VERSION ""

NS_ :

BS_:

BU_: VT3 VT2 VT1 Implement

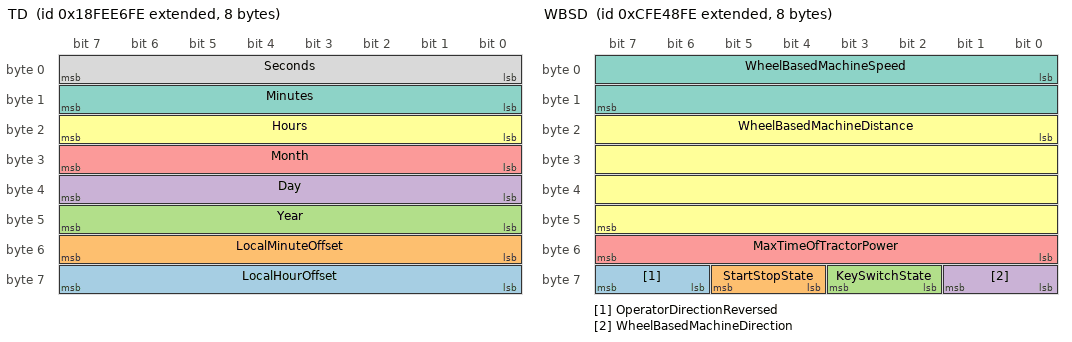
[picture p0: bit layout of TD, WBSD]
BO_ 2566842110 TD: 8 Vector__XXX
 SG_ LocalHourOffset : 56|8@1+ (1,-125) [-125|125] "hr" Vector__XXX
 SG_ LocalMinuteOffset : 48|8@1+ (1,-125) [-125|125] "mins" Vector__XXX
 SG_ Year : 40|8@1+ (1,1985) [1985|2235] "years" Vector__XXX
 SG_ Day : 32|8@1+ (0.25,0) [0|62.5] "days" Vector__XXX
 SG_ Month : 24|8@1+ (1,0) [0|250] "months" Vector__XXX
 SG_ Hours : 16|8@1+ (1,0) [0|250] "hr" Vector__XXX
 SG_ Minutes : 8|8@1+ (1,0) [0|250] "mins" Vector__XXX
 SG_ Seconds : 0|8@1+ (0.25,0) [0|62.5] "s" Vector__XXX

BO_ 2365475326 GBSD: 8 Vector__XXX
 SG_ GroundBasedMachineDirection : 56|2@1+ (1,0) [0|3] "" Vector__XXX
 SG_ GroundBasedMachineDistance : 16|32@1+ (0.001,0) [0|4211080] "m" Vector__XXX
 SG_ GroundBasedMachineSpeed : 0|16@1+ (0.001,0) [0|64.255] "m/s" Vector__XXX

BO_ 2365475070 WBSD: 8 Vector__XXX
 SG_ OperatorDirectionReversed : 62|2@1+ (1,0) [0|3] "" Vector__XXX
 SG_ StartStopState : 60|2@1+ (1,0) [0|4] "" Vector__XXX
 SG_ KeySwitchState : 58|2@1+ (1,0) [0|3] "" Vector__XXX
 SG_ WheelBasedMachineDirection : 56|2@1+ (1,0) [0|3] "" Vector__XXX
 SG_ MaxTimeOfTractorPower : 48|8@1+ (1,0) [0|250] "min" Vector__XXX
 SG_ WheelBasedMachineDistance : 16|32@1+ (0.001,0) [0|4211081.215] "m" Vector__XXX
 SG_ WheelBasedMachineSpeed : 0|16@1+ (0.001,0) [0|64.255] "m/s" Vector__XXX

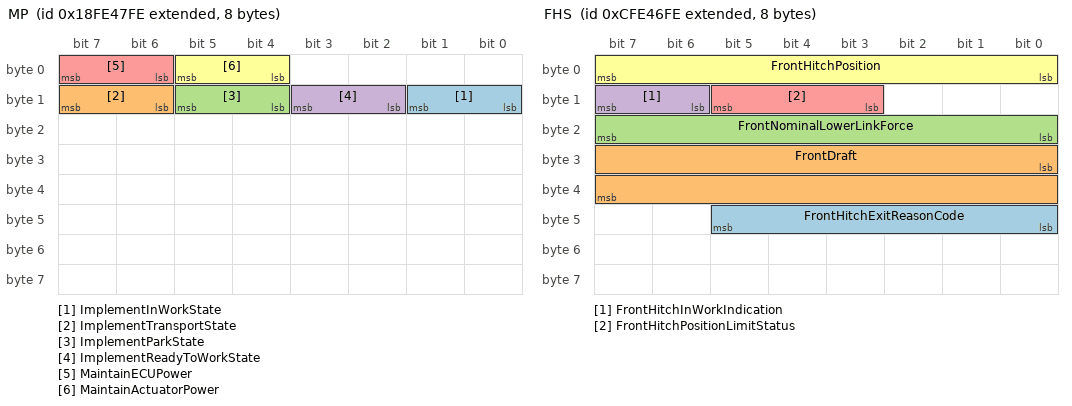
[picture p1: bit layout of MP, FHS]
BO_ 2566801406 MP: 8 Vector__XXX
 SG_ ImplementInWorkState : 8|2@1+ (1,0) [0|0] "" Vector__XXX
 SG_ ImplementTransportState : 14|2@1+ (1,0) [0|3] "" Vector__XXX
 SG_ ImplementParkState : 12|2@1+ (1,0) [0|3] "" Vector__XXX
 SG_ ImplementReadyToWorkState : 10|2@1+ (1,0) [0|3] "" Vector__XXX
 SG_ MaintainECUPower : 6|2@1+ (1,0) [0|0] "" Vector__XXX
 SG_ MaintainActuatorPower : 4|2@1+ (1,0) [0|3] "" Vector__XXX

BO_ 2365474558 FHS: 8 Vector__XXX
 SG_ FrontHitchExitReasonCode : 40|6@1+ (1,0) [0|63] "" Vector__XXX
 SG_ FrontDraft : 24|16@1+ (10,-320000) [-320000|322550] "N" Vector__XXX
 SG_ FrontNominalLowerLinkForce : 16|8@1+ (0.8,-100) [-100|100] "%" Vector__XXX
 SG_ FrontHitchInWorkIndication : 14|2@1+ (1,0) [0|3] "" Vector__XXX
 SG_ FrontHitchPositionLimitStatus : 11|3@1+ (1,0) [0|7] "" Vector__XXX
 SG_ FrontHitchPosition : 0|8@1+ (0.4,0) [0|100] "%" Vector__XXX

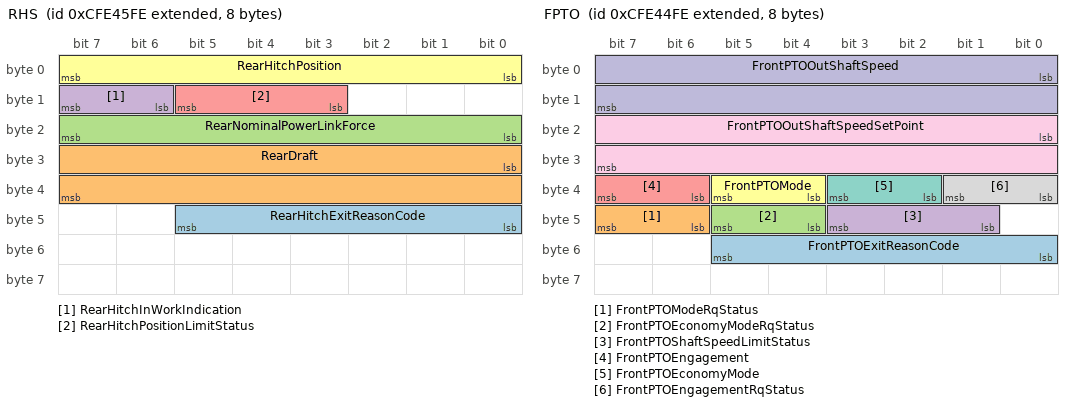
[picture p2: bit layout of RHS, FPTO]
BO_ 2365474302 RHS: 8 Vector__XXX
 SG_ RearHitchExitReasonCode : 40|6@1+ (1,0) [0|63] "" Vector__XXX
 SG_ RearDraft : 24|16@1+ (10,-320000) [-320000|322550] "N" Vector__XXX
 SG_ RearNominalPowerLinkForce : 16|8@1+ (0.8,-100) [-100|100] "%" Vector__XXX
 SG_ RearHitchInWorkIndication : 14|2@1+ (1,0) [0|3] "" Vector__XXX
 SG_ RearHitchPositionLimitStatus : 11|3@1+ (1,0) [0|7] "" Vector__XXX
 SG_ RearHitchPosition : 0|8@1+ (0.4,0) [0|100] "%" Vector__XXX

BO_ 2365474046 FPTO: 8 Vector__XXX
 SG_ FrontPTOExitReasonCode : 48|6@1+ (1,0) [0|63] "" Vector__XXX
 SG_ FrontPTOModeRqStatus : 46|2@1+ (1,0) [0|3] "" Vector__XXX
 SG_ FrontPTOEconomyModeRqStatus : 44|2@1+ (1,0) [0|3] "" Vector__XXX
 SG_ FrontPTOShaftSpeedLimitStatus : 41|3@1+ (1,0) [0|7] "" Vector__XXX
 SG_ FrontPTOEngagement : 38|2@1+ (1,0) [0|3] "" Vector__XXX
 SG_ FrontPTOMode : 36|2@1+ (1,0) [0|3] "" Vector__XXX
 SG_ FrontPTOEconomyMode : 34|2@1+ (1,0) [0|3] "" Vector__XXX
 SG_ FrontPTOEngagementRqStatus : 32|2@1+ (1,0) [0|3] "" Vector__XXX
 SG_ FrontPTOOutShaftSpeedSetPoint : 16|16@1+ (0.125,0) [0|8031.88] "1/min" Vector__XXX
 SG_ FrontPTOOutShaftSpeed : 0|16@1+ (0.125,0) [0|8031.88] "1/min" Vector__XXX

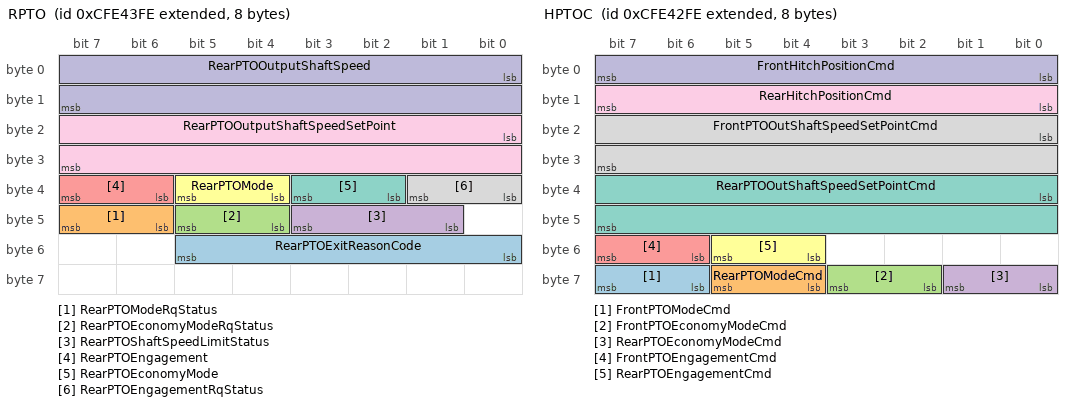
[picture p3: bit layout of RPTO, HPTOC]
BO_ 2365473790 RPTO: 8 Vector__XXX
 SG_ RearPTOExitReasonCode : 48|6@1+ (1,0) [0|63] "" Vector__XXX
 SG_ RearPTOModeRqStatus : 46|2@1+ (1,0) [0|3] "" Vector__XXX
 SG_ RearPTOEconomyModeRqStatus : 44|2@1+ (1,0) [0|3] "" Vector__XXX
 SG_ RearPTOShaftSpeedLimitStatus : 41|3@1+ (1,0) [0|7] "" Vector__XXX
 SG_ RearPTOEngagement : 38|2@1+ (1,0) [0|3] "" Vector__XXX
 SG_ RearPTOMode : 36|2@1+ (1,0) [0|3] "" Vector__XXX
 SG_ RearPTOEconomyMode : 34|2@1+ (1,0) [0|3] "" Vector__XXX
 SG_ RearPTOEngagementRqStatus : 32|2@1+ (1,0) [0|3] "" Vector__XXX
 SG_ RearPTOOutputShaftSpeedSetPoint : 16|16@1+ (0.125,0) [0|8031.88] "1/min" Vector__XXX
 SG_ RearPTOOutputShaftSpeed : 0|16@1+ (0.125,0) [0|8031.88] "1/min" Vector__XXX

BO_ 2365473534 HPTOC: 8 Vector__XXX
 SG_ FrontPTOModeCmd : 62|2@1+ (1,0) [0|3] "" Vector__XXX
 SG_ RearPTOModeCmd : 60|2@1+ (1,0) [0|3] "" Vector__XXX
 SG_ FrontPTOEconomyModeCmd : 58|2@1+ (1,0) [0|3] "" Vector__XXX
 SG_ RearPTOEconomyModeCmd : 56|2@1+ (1,0) [0|3] "" Vector__XXX
 SG_ FrontPTOEngagementCmd : 54|2@1+ (1,0) [0|3] "" Vector__XXX
 SG_ RearPTOEngagementCmd : 52|2@1+ (1,0) [0|3] "" Vector__XXX
 SG_ RearPTOOutShaftSpeedSetPointCmd : 32|16@1+ (0.125,0) [0|801.875] "1/min" Vector__XXX
 SG_ FrontPTOOutShaftSpeedSetPointCmd : 16|16@1+ (0.125,0) [0|8031.875] "1/min" Vector__XXX
 SG_ RearHitchPositionCmd : 8|8@1+ (0.4,0) [0|100] "%" Vector__XXX
 SG_ FrontHitchPositionCmd : 0|8@1+ (0.4,0) [0|100] "%" Vector__XXX

BO_ 2365473278 LCMD: 8 Vector__XXX
 SG_ ImplementRearWorkLightCmd : 62|2@1+ (1,0) [0|3] "" Vector__XXX
 SG_ ImplementLeftFacingWorkLightCmd : 60|2@1+ (1,0) [0|3] "" Vector__XXX
 SG_ ImplementRightFacingWorkLightCmd : 58|2@1+ (1,0) [0|3] "" Vector__XXX
 SG_ LightingDataRequestCmd : 56|2@1+ (1,0) [0|3] "" Vector__XXX
 SG_ ImplementLeftForwardLightCmd : 54|2@1+ (1,0) [0|3] "" Vector__XXX
 SG_ ImplementRightForwardLightCmd : 52|2@1+ (1,0) [0|3] "" Vector__XXX
 SG_ ImplementOEMOption1LightCmd : 50|2@1+ (1,0) [0|3] "" Vector__XXX
 SG_ ImplementOEMOption2LightCmd : 48|2@1+ (1,0) [0|3] "" Vector__XXX
 SG_ TractorFrontHighWorkLightCmd : 46|2@1+ (1,0) [0|3] "" Vector__XXX
 SG_ TractorFrontLowWorkLightCmd : 44|2@1+ (1,0) [0|3] "" Vector__XXX
 SG_ TractorSideHighWorkLightCmd : 42|2@1+ (1,0) [0|3] "" Vector__XXX
 SG_ TractorSideLowWorkLightCmd : 40|2@1+ (1,0) [0|3] "" Vector__XXX
 SG_ TractorRearHighWorkLightCmd : 38|2@1+ (1,0) [0|3] "" Vector__XXX
 SG_ TractorRearLowWorkLightCmd : 36|2@1+ (1,0) [0|3] "" Vector__XXX
 SG_ TractorUndersideWorkLightCmd : 34|2@1+ (1,0) [0|3] "" Vector__XXX
 SG_ RearFogLightCmd : 32|2@1+ (1,0) [0|3] "" Vector__XXX
 SG_ TractorMarkerLightCmd : 30|2@1+ (1,0) [0|3] "" Vector__XXX
 SG_ ImplementMarkerLightCmd : 28|2@1+ (1,0) [0|3] "" Vector__XXX
 SG_ TractorClearanceLightCmd : 26|2@1+ (1,0) [0|3] "" Vector__XXX
 SG_ ImplementClearanceLightCmd : 24|2@1+ (1,0) [0|3] "" Vector__XXX
 SG_ LeftStopLightCmd : 22|2@1+ (1,0) [0|3] "" Vector__XXX
 SG_ RightStopLightCmd : 20|2@1+ (1,0) [0|3] "" Vector__XXX
 SG_ CentreStopLightCmd : 18|2@1+ (1,0) [0|3] "" Vector__XXX
 SG_ BackUpLightAndAlarmHornCmd : 16|2@1+ (1,0) [0|3] "" Vector__XXX
 SG_ LeftTurnSignalLightCmd : 14|2@1+ (1,0) [0|3] "" Vector__XXX
 SG_ RightTurnSignalLightCmd : 12|2@1+ (1,0) [0|3] "" Vector__XXX
 SG_ RotatingBeaconLightCmd : 10|2@1+ (1,0) [0|3] "" Vector__XXX
 SG_ TractorFrontFogLightCmd : 8|2@1+ (1,0) [0|3] "" Vector__XXX
 SG_ HighBeamHeadLightCmd : 6|2@1+ (1,0) [0|3] "" Vector__XXX
 SG_ LowBeamHeadLightCmd : 4|2@1+ (1,0) [0|3] "" Vector__XXX
 SG_ AlternateHeadLightCmd : 2|2@1+ (1,0) [0|3] "" Vector__XXX
 SG_ DaytimeRunningLightCmd : 0|2@1+ (1,0) [0|3] "" Vector__XXX

BO_ 2566799614 LID: 8 Vector__XXX
 SG_ ImplementRearWorkLightData : 62|2@1+ (1,0) [0|3] "" Vector__XXX
 SG_ ImplLeftFacingWorkLightData : 60|2@1+ (1,0) [0|3] "" Vector__XXX
 SG_ ImplRightFacingWorkLightData : 58|2@1+ (1,0) [0|3] "" Vector__XXX
 SG_ ImplementLeftForwardLightData : 54|2@1+ (1,0) [0|3] "" Vector__XXX
 SG_ ImplementRightForwardLightData : 52|2@1+ (1,0) [0|3] "" Vector__XXX
 SG_ ImplementOEMOption1LightData : 50|2@1+ (1,0) [0|3] "" Vector__XXX
 SG_ ImplementOEMOption2LightData : 48|2@1+ (1,0) [0|3] "" Vector__XXX
 SG_ TractorFrontHighWorkLightData : 46|2@1+ (1,0) [0|3] "" Vector__XXX
 SG_ TractorFrontLowWorkLightData : 44|2@1+ (1,0) [0|3] "" Vector__XXX
 SG_ TractorSideHighWorkLightData : 42|2@1+ (1,0) [0|3] "" Vector__XXX
 SG_ TractorSideLowWorkLightData : 40|2@1+ (1,0) [0|3] "" Vector__XXX
 SG_ TractorRearHighWorkLightData : 38|2@1+ (1,0) [0|3] "" Vector__XXX
 SG_ TractorRearLowWorkLightData : 36|2@1+ (1,0) [0|3] "" Vector__XXX
 SG_ TractorUndersideWorkLightData : 34|2@1+ (1,0) [0|3] "" Vector__XXX
 SG_ RearFogLightData : 32|2@1+ (1,0) [0|3] "" Vector__XXX
 SG_ TractorMarkerLightData : 30|2@1+ (1,0) [0|3] "" Vector__XXX
 SG_ ImplementMarkerLightData : 28|2@1+ (1,0) [0|3] "" Vector__XXX
 SG_ TractorClearanceLightData : 26|2@1+ (1,0) [0|3] "" Vector__XXX
 SG_ ImplementClearanceLightData : 24|2@1+ (1,0) [0|3] "" Vector__XXX
 SG_ LefttStopLightData : 22|2@1+ (1,0) [0|3] "" Vector__XXX
 SG_ RightStopLightData : 20|2@1+ (1,0) [0|3] "" Vector__XXX
 SG_ CentreStopLightData : 18|2@1+ (1,0) [0|3] "" Vector__XXX
 SG_ BackUpLightAndAlarmHornData : 16|2@1+ (1,0) [0|3] "" Vector__XXX
 SG_ LeftTurnSignalLightData : 14|2@1+ (1,0) [0|3] "" Vector__XXX
 SG_ RightTurnSignalLightData : 12|2@1+ (1,0) [0|3] "" Vector__XXX
 SG_ RotationBeaconLightData : 10|2@1+ (1,0) [0|3] "" Vector__XXX
 SG_ TractorFrontFogLightData : 8|2@1+ (1,0) [0|3] "" Vector__XXX
 SG_ HighBeamHeadLightData : 6|2@1+ (1,0) [0|3] "" Vector__XXX
 SG_ LowBeamHeadLightData : 4|2@1+ (1,0) [0|3] "" Vector__XXX
 SG_ AlternateHeadLightData : 2|2@1+ (1,0) [0|3] "" Vector__XXX
 SG_ DaytimeRunningLightData : 0|2@1+ (1,0) [0|3] "" Vector__XXX

BO_ 2365472766 AV15C: 8 Vector__XXX
 SG_ Valve15FailSaveModeCmd : 22|2@1+ (1,0) [0|3] "" Vector__XXX
 SG_ Valve15StateCmd : 16|4@1+ (1,0) [0|15] "" Vector__XXX
 SG_ Valve15PortFlowCmd : 0|8@1+ (0.4,0) [0|100] "%" Vector__XXX

BO_ 2365472510 AV14C: 8 Vector__XXX
 SG_ Valve14FailSaveModeCmd : 22|2@1+ (1,0) [0|3] "" Vector__XXX
 SG_ Valve14StateCmd : 16|4@1+ (1,0) [0|15] "" Vector__XXX
 SG_ Valve14PortFlowCmd : 0|8@1+ (0.4,0) [0|100] "%" Vector__XXX

BO_ 2365472254 AV13C: 8 Vector__XXX
 SG_ Valve13FailSaveModeCmd : 22|2@1+ (1,0) [0|3] "" Vector__XXX
 SG_ Valve13StateCmd : 16|4@1+ (1,0) [0|15] "" Vector__XXX
 SG_ Valve13PortFlowCmd : 0|8@1+ (0.4,0) [0|100] "%" Vector__XXX

BO_ 2365471998 AV12C: 8 Vector__XXX
 SG_ Valve12FailSaveModeCmd : 22|2@1+ (1,0) [0|3] "" Vector__XXX
 SG_ Valve12StateCmd : 16|4@1+ (1,0) [0|15] "" Vector__XXX
 SG_ Valve12PortFlowCmd : 0|8@1+ (0.4,0) [0|100] "%" Vector__XXX

BO_ 2365471742 AV11C: 8 Vector__XXX
 SG_ Valve11FailSaveModeCmd : 22|2@1+ (1,0) [0|3] "" Vector__XXX
 SG_ Valve11StateCmd : 16|4@1+ (1,0) [0|15] "" Vector__XXX
 SG_ Valve11PortFlowCmd : 0|8@1+ (0.4,0) [0|100] "%" Vector__XXX

BO_ 2365471486 AV10C: 8 Vector__XXX
 SG_ Valve10FailSaveModeCmd : 22|2@1+ (1,0) [0|3] "" Vector__XXX
 SG_ Valve10StateCmd : 16|4@1+ (1,0) [0|15] "" Vector__XXX
 SG_ Valve10PortFlowCmd : 0|8@1+ (0.4,0) [0|100] "%" Vector__XXX

BO_ 2365471230 AV09C: 8 Vector__XXX
 SG_ Valve9FailSaveModeCmd : 22|2@1+ (1,0) [0|3] "" Vector__XXX
 SG_ Valve9StateCmd : 16|4@1+ (1,0) [0|15] "" Vector__XXX
 SG_ Valve9PortFlowCmd : 0|8@1+ (0.4,0) [0|100] "%" Vector__XXX

BO_ 2365470974 AV08C: 8 Vector__XXX
 SG_ Valve8FailSaveModeCmd : 22|2@1+ (1,0) [0|3] "" Vector__XXX
 SG_ Valve8StateCmd : 16|4@1+ (1,0) [0|15] "" Vector__XXX
 SG_ Valve8PortFlowCmd : 0|8@1+ (0.4,0) [0|100] "%" Vector__XXX

BO_ 2365470718 AV07C: 8 Vector__XXX
 SG_ Valve7FailSaveModeCmd : 22|2@1+ (1,0) [0|3] "" Vector__XXX
 SG_ Valve7StateCmd : 16|4@1+ (1,0) [0|15] "" Vector__XXX
 SG_ Valve7PortFlowCmd : 0|8@1+ (0.4,0) [0|100] "%" Vector__XXX

BO_ 2365470462 AV06C: 8 Vector__XXX
 SG_ Valve6FailSaveModeCmd : 22|2@1+ (1,0) [0|3] "" Vector__XXX
 SG_ Valve6StateCmd : 16|4@1+ (1,0) [0|15] "" Vector__XXX
 SG_ Valve6PortFlowCmd : 0|8@1+ (0.4,0) [0|100] "%" Vector__XXX

BO_ 2365470206 AV05C: 8 Vector__XXX
 SG_ Valve5FailSaveModeCmd : 22|2@1+ (1,0) [0|3] "" Vector__XXX
 SG_ Valve5StateCmd : 16|4@1+ (1,0) [0|15] "" Vector__XXX
 SG_ Valve5PortFlowCmd : 0|8@1+ (0.4,0) [0|100] "%" Vector__XXX

BO_ 2365469950 AV04C: 8 Vector__XXX
 SG_ Valve4FailSaveModeCmd : 22|2@1+ (1,0) [0|3] "" Vector__XXX
 SG_ Valve4StateCmd : 16|4@1+ (1,0) [0|15] "" Vector__XXX
 SG_ Valve4PortFlowCmd : 0|8@1+ (0.4,0) [0|100] "%" Vector__XXX

BO_ 2365469694 AV03C: 8 Vector__XXX
 SG_ Valve3FailSaveModeCmd : 22|2@1+ (1,0) [0|3] "" Vector__XXX
 SG_ Valve3StateCmd : 16|4@1+ (1,0) [0|15] "" Vector__XXX
 SG_ Valve3PortFlowCmd : 0|8@1+ (0.4,0) [0|100] "%" Vector__XXX

BO_ 2365469438 AV02C: 8 Vector__XXX
 SG_ Valve2FailSaveModeCmd : 22|2@1+ (1,0) [0|3] "" Vector__XXX
 SG_ Valve2StateCmd : 16|4@1+ (1,0) [0|15] "" Vector__XXX
 SG_ Valve2PortFlowCmd : 0|8@1+ (0.4,0) [0|100] "%" Vector__XXX

BO_ 2365469182 AV01C: 8 Vector__XXX
 SG_ Valve1FailSaveModeCmd : 22|2@1+ (1,0) [0|3] "" Vector__XXX
 SG_ Valve1StateCmd : 16|4@1+ (1,0) [0|15] "" Vector__XXX
 SG_ Valve1PortFlowCmd : 0|8@1+ (0.4,0) [0|100] "%" Vector__XXX

BO_ 2365468926 AV00C: 8 Vector__XXX
 SG_ Valve0FailSaveModeCmd : 22|2@1+ (1,0) [0|3] "" Vector__XXX
 SG_ Valve0StateCmd : 16|4@1+ (1,0) [0|15] "" Vector__XXX
 SG_ Valve0PortFlowCmd : 0|8@1+ (0.4,0) [0|100] "%" Vector__XXX

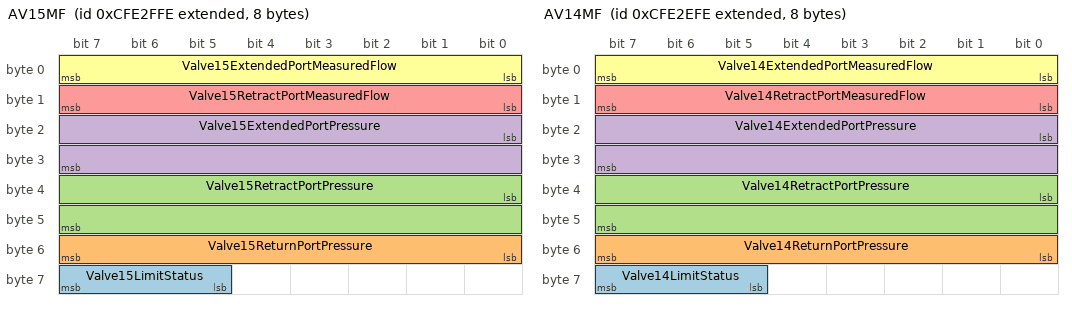
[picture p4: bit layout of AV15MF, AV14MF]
BO_ 2365468670 AV15MF: 8 Vector__XXX
 SG_ Valve15LimitStatus : 61|3@1+ (1,0) [0|7] "" Vector__XXX
 SG_ Valve15ReturnPortPressure : 48|8@1+ (16,0) [0|4000] "kPa" Vector__XXX
 SG_ Valve15RetractPortPressure : 32|16@1+ (5,0) [0|321275] "kPa" Vector__XXX
 SG_ Valve15ExtendedPortPressure : 16|16@1+ (5,0) [0|321275] "kPa" Vector__XXX
 SG_ Valve15RetractPortMeasuredFlow : 8|8@1+ (1,-125) [-125|125] "%" Vector__XXX
 SG_ Valve15ExtendedPortMeasuredFlow : 0|8@1+ (1,-125) [-125|125] "%" Vector__XXX

BO_ 2365468414 AV14MF: 8 Vector__XXX
 SG_ Valve14LimitStatus : 61|3@1+ (1,0) [0|7] "" Vector__XXX
 SG_ Valve14ReturnPortPressure : 48|8@1+ (16,0) [0|4000] "kPa" Vector__XXX
 SG_ Valve14RetractPortPressure : 32|16@1+ (5,0) [0|321275] "kPa" Vector__XXX
 SG_ Valve14ExtendedPortPressure : 16|16@1+ (5,0) [0|321275] "kPa" Vector__XXX
 SG_ Valve14RetractPortMeasuredFlow : 8|8@1+ (1,-125) [-125|125] "%" Vector__XXX
 SG_ Valve14ExtendedPortMeasuredFlow : 0|8@1+ (1,-125) [-125|125] "%" Vector__XXX

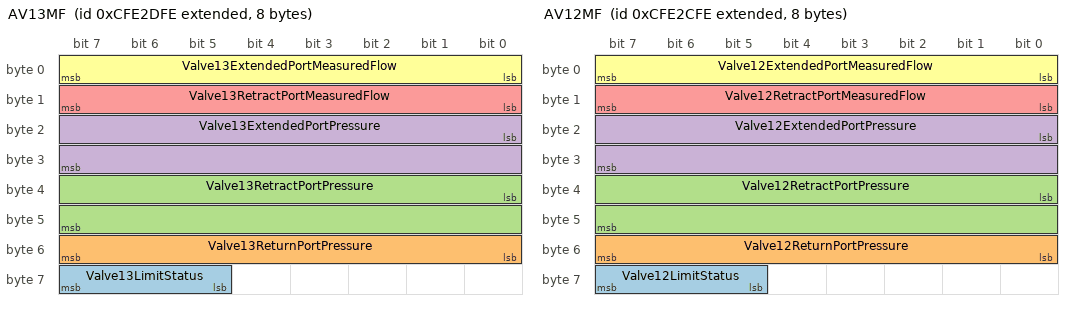
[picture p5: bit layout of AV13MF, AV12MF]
BO_ 2365468158 AV13MF: 8 Vector__XXX
 SG_ Valve13LimitStatus : 61|3@1+ (1,0) [0|7] "" Vector__XXX
 SG_ Valve13ReturnPortPressure : 48|8@1+ (16,0) [0|4000] "kPa" Vector__XXX
 SG_ Valve13RetractPortPressure : 32|16@1+ (5,0) [0|321275] "kPa" Vector__XXX
 SG_ Valve13ExtendedPortPressure : 16|16@1+ (5,0) [0|321275] "kPa" Vector__XXX
 SG_ Valve13RetractPortMeasuredFlow : 8|8@1+ (1,-125) [-125|125] "%" Vector__XXX
 SG_ Valve13ExtendedPortMeasuredFlow : 0|8@1+ (1,-125) [-125|125] "%" Vector__XXX

BO_ 2365467902 AV12MF: 8 Vector__XXX
 SG_ Valve12LimitStatus : 61|3@1+ (1,0) [0|7] "" Vector__XXX
 SG_ Valve12ReturnPortPressure : 48|8@1+ (16,0) [0|4000] "kPa" Vector__XXX
 SG_ Valve12RetractPortPressure : 32|16@1+ (5,0) [0|321275] "kPa" Vector__XXX
 SG_ Valve12ExtendedPortPressure : 16|16@1+ (5,0) [0|321275] "kPa" Vector__XXX
 SG_ Valve12RetractPortMeasuredFlow : 8|8@1+ (1,-125) [-125|125] "%" Vector__XXX
 SG_ Valve12ExtendedPortMeasuredFlow : 0|8@1+ (1,-125) [-125|125] "%" Vector__XXX

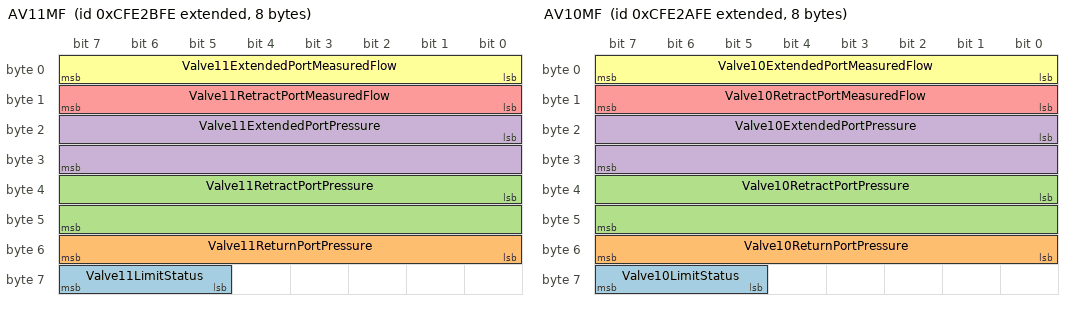
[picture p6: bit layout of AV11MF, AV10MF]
BO_ 2365467646 AV11MF: 8 Vector__XXX
 SG_ Valve11LimitStatus : 61|3@1+ (1,0) [0|7] "" Vector__XXX
 SG_ Valve11ReturnPortPressure : 48|8@1+ (16,0) [0|4000] "kPa" Vector__XXX
 SG_ Valve11RetractPortPressure : 32|16@1+ (5,0) [0|321275] "kPa" Vector__XXX
 SG_ Valve11ExtendedPortPressure : 16|16@1+ (5,0) [0|321275] "kPa" Vector__XXX
 SG_ Valve11RetractPortMeasuredFlow : 8|8@1+ (1,-125) [-125|125] "%" Vector__XXX
 SG_ Valve11ExtendedPortMeasuredFlow : 0|8@1+ (1,-125) [-125|125] "%" Vector__XXX

BO_ 2365467390 AV10MF: 8 Vector__XXX
 SG_ Valve10LimitStatus : 61|3@1+ (1,0) [0|7] "" Vector__XXX
 SG_ Valve10ReturnPortPressure : 48|8@1+ (16,0) [0|4000] "kPa" Vector__XXX
 SG_ Valve10RetractPortPressure : 32|16@1+ (5,0) [0|321275] "kPa" Vector__XXX
 SG_ Valve10ExtendedPortPressure : 16|16@1+ (5,0) [0|321275] "kPa" Vector__XXX
 SG_ Valve10RetractPortMeasuredFlow : 8|8@1+ (1,-125) [-125|125] "%" Vector__XXX
 SG_ Valve10ExtendedPortMeasuredFlow : 0|8@1+ (1,-125) [-125|125] "%" Vector__XXX

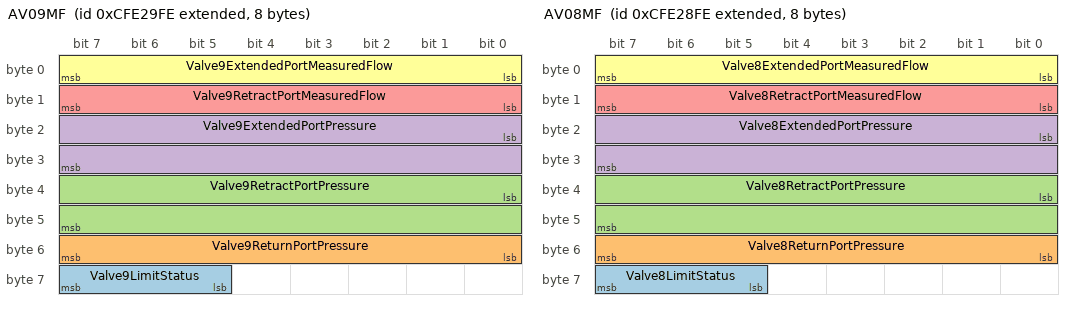
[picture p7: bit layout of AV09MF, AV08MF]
BO_ 2365467134 AV09MF: 8 Vector__XXX
 SG_ Valve9LimitStatus : 61|3@1+ (1,0) [0|7] "" Vector__XXX
 SG_ Valve9ReturnPortPressure : 48|8@1+ (16,0) [0|4000] "kPa" Vector__XXX
 SG_ Valve9RetractPortPressure : 32|16@1+ (5,0) [0|321275] "kPa" Vector__XXX
 SG_ Valve9ExtendedPortPressure : 16|16@1+ (5,0) [0|321275] "kPa" Vector__XXX
 SG_ Valve9RetractPortMeasuredFlow : 8|8@1+ (1,-125) [-125|125] "%" Vector__XXX
 SG_ Valve9ExtendedPortMeasuredFlow : 0|8@1+ (1,-125) [-125|125] "%" Vector__XXX

BO_ 2365466878 AV08MF: 8 Vector__XXX
 SG_ Valve8LimitStatus : 61|3@1+ (1,0) [0|7] "" Vector__XXX
 SG_ Valve8ReturnPortPressure : 48|8@1+ (16,0) [0|4000] "kPa" Vector__XXX
 SG_ Valve8RetractPortPressure : 32|16@1+ (5,0) [0|321275] "kPa" Vector__XXX
 SG_ Valve8ExtendedPortPressure : 16|16@1+ (5,0) [0|321275] "kPa" Vector__XXX
 SG_ Valve8RetractPortMeasuredFlow : 8|8@1+ (1,-125) [-125|125] "%" Vector__XXX
 SG_ Valve8ExtendedPortMeasuredFlow : 0|8@1+ (1,-125) [-125|125] "%" Vector__XXX

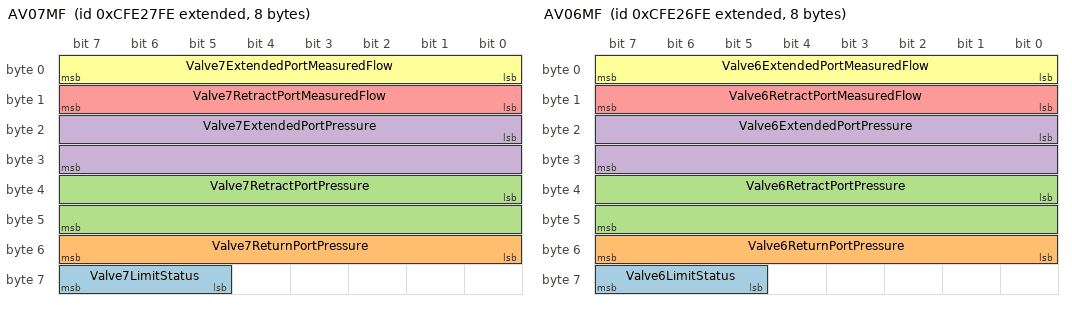
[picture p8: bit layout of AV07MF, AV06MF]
BO_ 2365466622 AV07MF: 8 Vector__XXX
 SG_ Valve7LimitStatus : 61|3@1+ (1,0) [0|7] "" Vector__XXX
 SG_ Valve7ReturnPortPressure : 48|8@1+ (16,0) [0|4000] "kPa" Vector__XXX
 SG_ Valve7RetractPortPressure : 32|16@1+ (5,0) [0|321275] "kPa" Vector__XXX
 SG_ Valve7ExtendedPortPressure : 16|16@1+ (5,0) [0|321275] "kPa" Vector__XXX
 SG_ Valve7RetractPortMeasuredFlow : 8|8@1+ (1,-125) [-125|125] "%" Vector__XXX
 SG_ Valve7ExtendedPortMeasuredFlow : 0|8@1+ (1,-125) [-125|125] "%" Vector__XXX

BO_ 2365466366 AV06MF: 8 Vector__XXX
 SG_ Valve6LimitStatus : 61|3@1+ (1,0) [0|7] "" Vector__XXX
 SG_ Valve6ReturnPortPressure : 48|8@1+ (16,0) [0|4000] "kPa" Vector__XXX
 SG_ Valve6RetractPortPressure : 32|16@1+ (5,0) [0|321275] "kPa" Vector__XXX
 SG_ Valve6ExtendedPortPressure : 16|16@1+ (5,0) [0|321275] "kPa" Vector__XXX
 SG_ Valve6RetractPortMeasuredFlow : 8|8@1+ (1,-125) [-125|125] "%" Vector__XXX
 SG_ Valve6ExtendedPortMeasuredFlow : 0|8@1+ (1,-125) [-125|125] "%" Vector__XXX

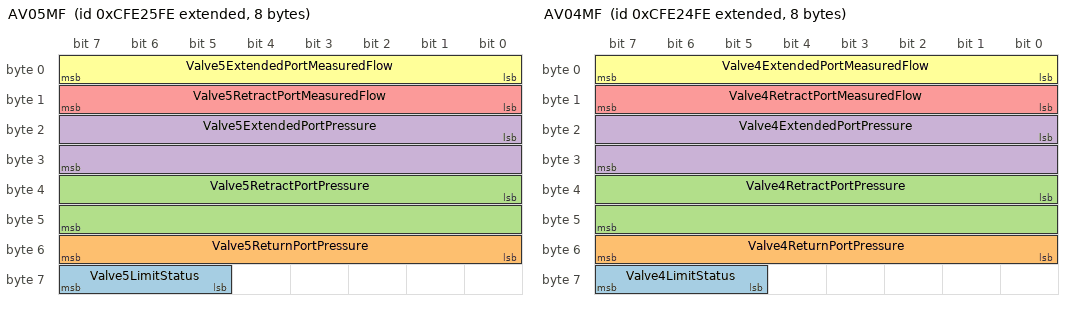
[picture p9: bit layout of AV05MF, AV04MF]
BO_ 2365466110 AV05MF: 8 Vector__XXX
 SG_ Valve5LimitStatus : 61|3@1+ (1,0) [0|7] "" Vector__XXX
 SG_ Valve5ReturnPortPressure : 48|8@1+ (16,0) [0|4000] "kPa" Vector__XXX
 SG_ Valve5RetractPortPressure : 32|16@1+ (5,0) [0|321275] "kPa" Vector__XXX
 SG_ Valve5ExtendedPortPressure : 16|16@1+ (5,0) [0|321275] "kPa" Vector__XXX
 SG_ Valve5RetractPortMeasuredFlow : 8|8@1+ (1,-125) [-125|125] "%" Vector__XXX
 SG_ Valve5ExtendedPortMeasuredFlow : 0|8@1+ (1,-125) [-125|125] "%" Vector__XXX

BO_ 2365465854 AV04MF: 8 Vector__XXX
 SG_ Valve4LimitStatus : 61|3@1+ (1,0) [0|7] "" Vector__XXX
 SG_ Valve4ReturnPortPressure : 48|8@1+ (16,0) [0|4000] "kPa" Vector__XXX
 SG_ Valve4RetractPortPressure : 32|16@1+ (5,0) [0|321275] "kPa" Vector__XXX
 SG_ Valve4ExtendedPortPressure : 16|16@1+ (5,0) [0|321275] "kPa" Vector__XXX
 SG_ Valve4RetractPortMeasuredFlow : 8|8@1+ (1,-125) [-125|125] "%" Vector__XXX
 SG_ Valve4ExtendedPortMeasuredFlow : 0|8@1+ (1,-125) [-125|125] "%" Vector__XXX

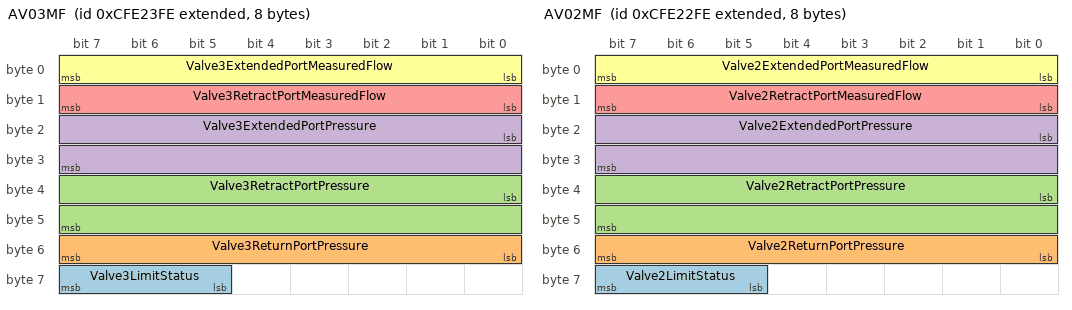
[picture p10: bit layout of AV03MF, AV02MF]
BO_ 2365465598 AV03MF: 8 Vector__XXX
 SG_ Valve3LimitStatus : 61|3@1+ (1,0) [0|7] "" Vector__XXX
 SG_ Valve3ReturnPortPressure : 48|8@1+ (16,0) [0|4000] "kPa" Vector__XXX
 SG_ Valve3RetractPortPressure : 32|16@1+ (5,0) [0|321275] "kPa" Vector__XXX
 SG_ Valve3ExtendedPortPressure : 16|16@1+ (5,0) [0|321275] "kPa" Vector__XXX
 SG_ Valve3RetractPortMeasuredFlow : 8|8@1+ (1,-125) [-125|125] "%" Vector__XXX
 SG_ Valve3ExtendedPortMeasuredFlow : 0|8@1+ (1,-125) [-125|125] "%" Vector__XXX

BO_ 2365465342 AV02MF: 8 Vector__XXX
 SG_ Valve2LimitStatus : 61|3@1+ (1,0) [0|7] "" Vector__XXX
 SG_ Valve2ReturnPortPressure : 48|8@1+ (16,0) [0|4000] "kPa" Vector__XXX
 SG_ Valve2RetractPortPressure : 32|16@1+ (5,0) [0|321275] "kPa" Vector__XXX
 SG_ Valve2ExtendedPortPressure : 16|16@1+ (5,0) [0|321275] "kPa" Vector__XXX
 SG_ Valve2RetractPortMeasuredFlow : 8|8@1+ (1,-125) [-125|125] "%" Vector__XXX
 SG_ Valve2ExtendedPortMeasuredFlow : 0|8@1+ (1,-125) [-125|125] "%" Vector__XXX

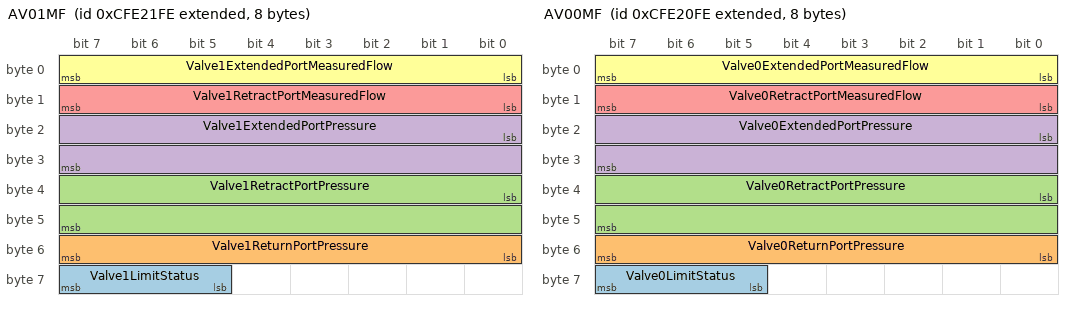
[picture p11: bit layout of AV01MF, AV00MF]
BO_ 2365465086 AV01MF: 8 Vector__XXX
 SG_ Valve1LimitStatus : 61|3@1+ (1,0) [0|7] "" Vector__XXX
 SG_ Valve1ReturnPortPressure : 48|8@1+ (16,0) [0|4000] "kPa" Vector__XXX
 SG_ Valve1RetractPortPressure : 32|16@1+ (5,0) [0|321275] "kPa" Vector__XXX
 SG_ Valve1ExtendedPortPressure : 16|16@1+ (5,0) [0|321275] "kPa" Vector__XXX
 SG_ Valve1RetractPortMeasuredFlow : 8|8@1+ (1,-125) [-125|125] "%" Vector__XXX
 SG_ Valve1ExtendedPortMeasuredFlow : 0|8@1+ (1,-125) [-125|125] "%" Vector__XXX

BO_ 2365464830 AV00MF: 8 Vector__XXX
 SG_ Valve0LimitStatus : 61|3@1+ (1,0) [0|7] "" Vector__XXX
 SG_ Valve0ReturnPortPressure : 48|8@1+ (16,0) [0|4000] "kPa" Vector__XXX
 SG_ Valve0RetractPortPressure : 32|16@1+ (5,0) [0|321275] "kPa" Vector__XXX
 SG_ Valve0ExtendedPortPressure : 16|16@1+ (5,0) [0|321275] "kPa" Vector__XXX
 SG_ Valve0RetractPortMeasuredFlow : 8|8@1+ (1,-125) [-125|125] "%" Vector__XXX
 SG_ Valve0ExtendedPortMeasuredFlow : 0|8@1+ (1,-125) [-125|125] "%" Vector__XXX

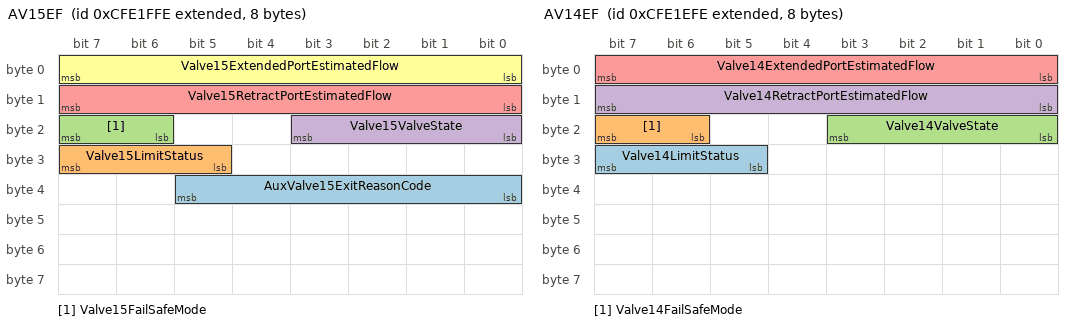
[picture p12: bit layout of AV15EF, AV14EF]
BO_ 2365464574 AV15EF: 8 Vector__XXX
 SG_ AuxValve15ExitReasonCode : 32|6@1+ (1,0) [0|63] "" Vector__XXX
 SG_ Valve15LimitStatus : 29|3@1+ (1,0) [0|7] "" Vector__XXX
 SG_ Valve15FailSafeMode : 22|2@1+ (1,0) [0|3] "" Vector__XXX
 SG_ Valve15ValveState : 16|4@1+ (1,0) [0|15] "" Vector__XXX
 SG_ Valve15RetractPortEstimatedFlow : 8|8@1+ (1,-125) [-125|125] "%" Vector__XXX
 SG_ Valve15ExtendedPortEstimatedFlow : 0|8@1+ (1,-125) [-125|125] "%" Vector__XXX

BO_ 2365464318 AV14EF: 8 Vector__XXX
 SG_ Valve14LimitStatus : 29|3@1+ (1,0) [0|7] "" Vector__XXX
 SG_ Valve14FailSafeMode : 22|2@1+ (1,0) [0|3] "" Vector__XXX
 SG_ Valve14ValveState : 16|4@1+ (1,0) [0|15] "" Vector__XXX
 SG_ Valve14RetractPortEstimatedFlow : 8|8@1+ (1,-125) [-125|125] "%" Vector__XXX
 SG_ Valve14ExtendedPortEstimatedFlow : 0|8@1+ (1,-125) [-125|125] "%" Vector__XXX

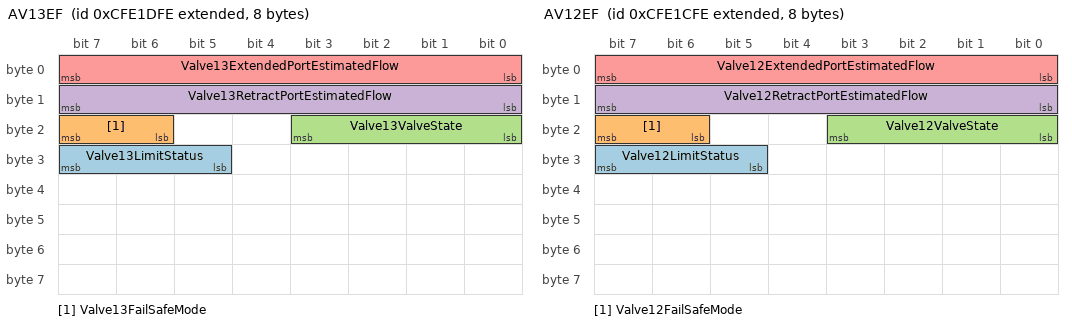
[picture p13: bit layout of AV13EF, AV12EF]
BO_ 2365464062 AV13EF: 8 Vector__XXX
 SG_ Valve13LimitStatus : 29|3@1+ (1,0) [0|7] "" Vector__XXX
 SG_ Valve13FailSafeMode : 22|2@1+ (1,0) [0|3] "" Vector__XXX
 SG_ Valve13ValveState : 16|4@1+ (1,0) [0|15] "" Vector__XXX
 SG_ Valve13RetractPortEstimatedFlow : 8|8@1+ (1,-125) [-125|125] "%" Vector__XXX
 SG_ Valve13ExtendedPortEstimatedFlow : 0|8@1+ (1,-125) [-125|125] "%" Vector__XXX

BO_ 2365463806 AV12EF: 8 Vector__XXX
 SG_ Valve12LimitStatus : 29|3@1+ (1,0) [0|7] "" Vector__XXX
 SG_ Valve12FailSafeMode : 22|2@1+ (1,0) [0|3] "" Vector__XXX
 SG_ Valve12ValveState : 16|4@1+ (1,0) [0|15] "" Vector__XXX
 SG_ Valve12RetractPortEstimatedFlow : 8|8@1+ (1,-125) [-125|125] "%" Vector__XXX
 SG_ Valve12ExtendedPortEstimatedFlow : 0|8@1+ (1,-125) [-125|125] "%" Vector__XXX

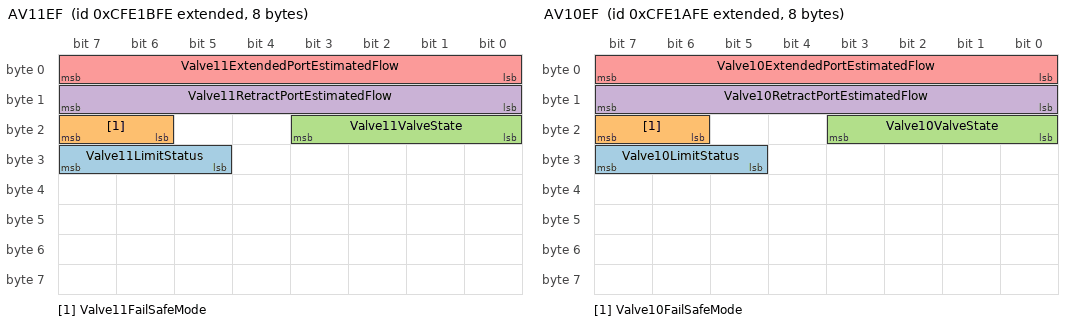
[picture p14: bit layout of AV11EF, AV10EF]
BO_ 2365463550 AV11EF: 8 Vector__XXX
 SG_ Valve11LimitStatus : 29|3@1+ (1,0) [0|7] "" Vector__XXX
 SG_ Valve11FailSafeMode : 22|2@1+ (1,0) [0|3] "" Vector__XXX
 SG_ Valve11ValveState : 16|4@1+ (1,0) [0|15] "" Vector__XXX
 SG_ Valve11RetractPortEstimatedFlow : 8|8@1+ (1,-125) [-125|125] "%" Vector__XXX
 SG_ Valve11ExtendedPortEstimatedFlow : 0|8@1+ (1,-125) [-125|125] "%" Vector__XXX

BO_ 2365463294 AV10EF: 8 Vector__XXX
 SG_ Valve10LimitStatus : 29|3@1+ (1,0) [0|7] "" Vector__XXX
 SG_ Valve10FailSafeMode : 22|2@1+ (1,0) [0|3] "" Vector__XXX
 SG_ Valve10ValveState : 16|4@1+ (1,0) [0|15] "" Vector__XXX
 SG_ Valve10RetractPortEstimatedFlow : 8|8@1+ (1,-125) [-125|125] "%" Vector__XXX
 SG_ Valve10ExtendedPortEstimatedFlow : 0|8@1+ (1,-125) [-125|125] "%" Vector__XXX

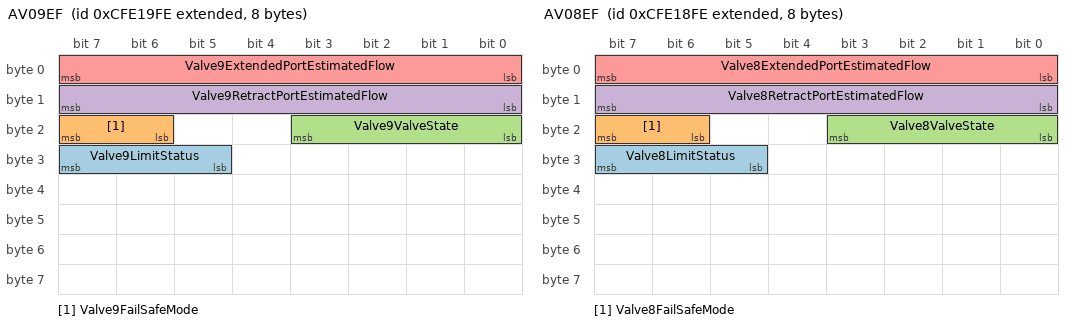
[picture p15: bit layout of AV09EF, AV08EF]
BO_ 2365463038 AV09EF: 8 Vector__XXX
 SG_ Valve9LimitStatus : 29|3@1+ (1,0) [0|7] "" Vector__XXX
 SG_ Valve9FailSafeMode : 22|2@1+ (1,0) [0|3] "" Vector__XXX
 SG_ Valve9ValveState : 16|4@1+ (1,0) [0|15] "" Vector__XXX
 SG_ Valve9RetractPortEstimatedFlow : 8|8@1+ (1,-125) [-125|125] "%" Vector__XXX
 SG_ Valve9ExtendedPortEstimatedFlow : 0|8@1+ (1,-125) [-125|125] "%" Vector__XXX

BO_ 2365462782 AV08EF: 8 Vector__XXX
 SG_ Valve8LimitStatus : 29|3@1+ (1,0) [0|7] "" Vector__XXX
 SG_ Valve8FailSafeMode : 22|2@1+ (1,0) [0|3] "" Vector__XXX
 SG_ Valve8ValveState : 16|4@1+ (1,0) [0|15] "" Vector__XXX
 SG_ Valve8RetractPortEstimatedFlow : 8|8@1+ (1,-125) [-125|125] "%" Vector__XXX
 SG_ Valve8ExtendedPortEstimatedFlow : 0|8@1+ (1,-125) [-125|125] "%" Vector__XXX

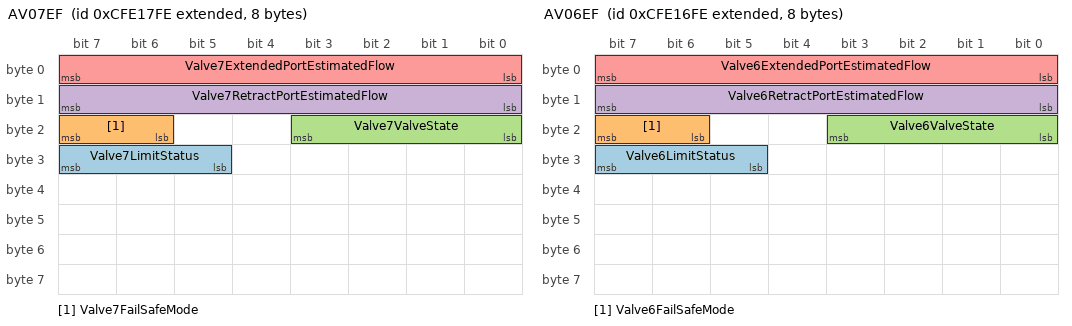
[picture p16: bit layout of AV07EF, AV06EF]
BO_ 2365462526 AV07EF: 8 Vector__XXX
 SG_ Valve7LimitStatus : 29|3@1+ (1,0) [0|7] "" Vector__XXX
 SG_ Valve7FailSafeMode : 22|2@1+ (1,0) [0|3] "" Vector__XXX
 SG_ Valve7ValveState : 16|4@1+ (1,0) [0|15] "" Vector__XXX
 SG_ Valve7RetractPortEstimatedFlow : 8|8@1+ (1,-125) [-125|125] "%" Vector__XXX
 SG_ Valve7ExtendedPortEstimatedFlow : 0|8@1+ (1,-125) [-125|125] "%" Vector__XXX

BO_ 2365462270 AV06EF: 8 Vector__XXX
 SG_ Valve6LimitStatus : 29|3@1+ (1,0) [0|7] "" Vector__XXX
 SG_ Valve6FailSafeMode : 22|2@1+ (1,0) [0|3] "" Vector__XXX
 SG_ Valve6ValveState : 16|4@1+ (1,0) [0|15] "" Vector__XXX
 SG_ Valve6RetractPortEstimatedFlow : 8|8@1+ (1,-125) [-125|125] "%" Vector__XXX
 SG_ Valve6ExtendedPortEstimatedFlow : 0|8@1+ (1,-125) [-125|125] "%" Vector__XXX

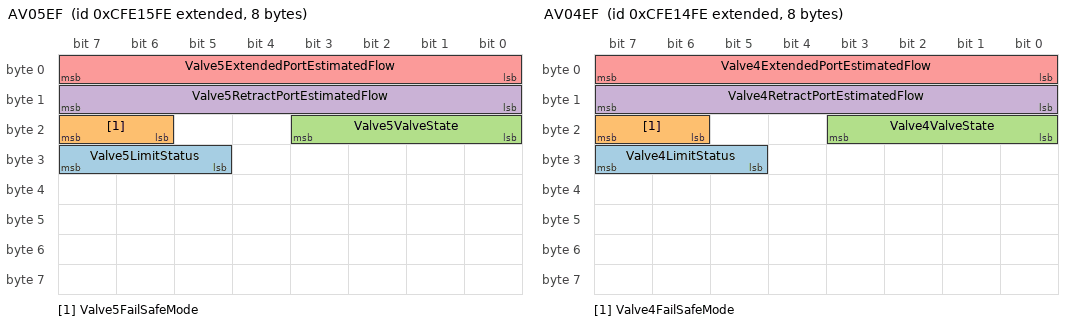
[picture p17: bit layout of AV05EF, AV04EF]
BO_ 2365462014 AV05EF: 8 Vector__XXX
 SG_ Valve5LimitStatus : 29|3@1+ (1,0) [0|7] "" Vector__XXX
 SG_ Valve5FailSafeMode : 22|2@1+ (1,0) [0|3] "" Vector__XXX
 SG_ Valve5ValveState : 16|4@1+ (1,0) [0|15] "" Vector__XXX
 SG_ Valve5RetractPortEstimatedFlow : 8|8@1+ (1,-125) [-125|125] "%" Vector__XXX
 SG_ Valve5ExtendedPortEstimatedFlow : 0|8@1+ (1,-125) [-125|125] "%" Vector__XXX

BO_ 2365461758 AV04EF: 8 Vector__XXX
 SG_ Valve4LimitStatus : 29|3@1+ (1,0) [0|7] "" Vector__XXX
 SG_ Valve4FailSafeMode : 22|2@1+ (1,0) [0|3] "" Vector__XXX
 SG_ Valve4ValveState : 16|4@1+ (1,0) [0|15] "" Vector__XXX
 SG_ Valve4RetractPortEstimatedFlow : 8|8@1+ (1,-125) [-125|125] "%" Vector__XXX
 SG_ Valve4ExtendedPortEstimatedFlow : 0|8@1+ (1,-125) [-125|125] "%" Vector__XXX

BO_ 2365461502 AV03EF: 8 Vector__XXX
 SG_ Valve3LimitStatus : 29|3@1+ (1,0) [0|7] "" Vector__XXX
 SG_ Valve3FailSafeMode : 22|2@1+ (1,0) [0|3] "" Vector__XXX
 SG_ Valve3ValveState : 16|4@1+ (1,0) [0|15] "" Vector__XXX
 SG_ Valve3RetractPortEstimatedFlow : 8|8@1+ (1,-125) [-125|125] "%" Vector__XXX
 SG_ Valve3ExtendedPortEstimatedFlow : 0|8@1+ (1,-125) [-125|125] "%" Vector__XXX

BO_ 2365461246 AV02EF: 8 Vector__XXX
 SG_ Valve2LimitStatus : 29|3@1+ (1,0) [0|7] "" Vector__XXX
 SG_ Valve2FailSafeMode : 22|2@1+ (1,0) [0|3] "" Vector__XXX
 SG_ Valve2ValveState : 16|4@1+ (1,0) [0|15] "" Vector__XXX
 SG_ Valve2RetractPortEstimatedFlow : 8|8@1+ (1,-125) [-125|125] "%" Vector__XXX
 SG_ Valve2ExtendedPortEstimatedFlow : 0|8@1+ (1,-125) [-125|125] "%" Vector__XXX

BO_ 2365460990 AV01EF: 8 Vector__XXX
 SG_ Valve1LimitStatus : 29|3@1+ (1,0) [0|7] "" Vector__XXX
 SG_ Valve1FailSafeMode : 22|2@1+ (1,0) [0|3] "" Vector__XXX
 SG_ Valve1ValveState : 16|4@1+ (1,0) [0|15] "" Vector__XXX
 SG_ Valve1RetractPortEstimatedFlow : 8|8@1+ (1,-125) [-125|125] "%" Vector__XXX
 SG_ Valve1ExtendedPortEstimatedFlow : 0|8@1+ (1,-125) [-125|125] "%" Vector__XXX

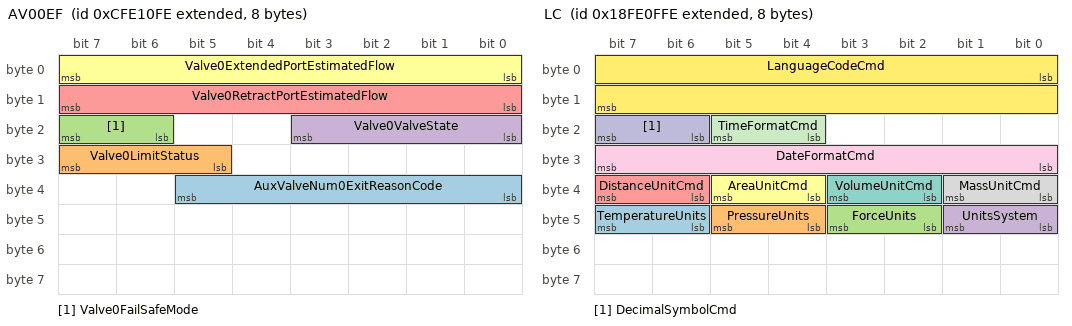
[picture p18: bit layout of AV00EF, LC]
BO_ 2365460734 AV00EF: 8 Vector__XXX
 SG_ AuxValveNum0ExitReasonCode : 32|6@1+ (1,0) [0|63] "" Vector__XXX
 SG_ Valve0LimitStatus : 29|3@1+ (1,0) [0|7] "" Vector__XXX
 SG_ Valve0FailSafeMode : 22|2@1+ (1,0) [0|3] "" Vector__XXX
 SG_ Valve0ValveState : 16|4@1+ (1,0) [0|15] "" Vector__XXX
 SG_ Valve0RetractPortEstimatedFlow : 8|8@1+ (1,-125) [-125|125] "%" Vector__XXX
 SG_ Valve0ExtendedPortEstimatedFlow : 0|8@1+ (1,-125) [-125|125] "%" Vector__XXX

BO_ 2566787070 LC: 8 Vector__XXX
 SG_ TemperatureUnits : 46|2@1+ (1,0) [0|3] "" Vector__XXX
 SG_ PressureUnits : 44|2@1+ (1,0) [0|3] "" Vector__XXX
 SG_ ForceUnits : 42|2@1+ (1,0) [0|3] "" Vector__XXX
 SG_ UnitsSystem : 40|2@1+ (1,0) [0|3] "" Vector__XXX
 SG_ DistanceUnitCmd : 38|2@1+ (1,0) [0|3] "" Vector__XXX
 SG_ AreaUnitCmd : 36|2@1+ (1,0) [0|3] "" Vector__XXX
 SG_ VolumeUnitCmd : 34|2@1+ (1,0) [0|3] "" Vector__XXX
 SG_ MassUnitCmd : 32|2@1+ (1,0) [0|3] "" Vector__XXX
 SG_ DateFormatCmd : 24|8@1+ (1,0) [0|255] "" Vector__XXX
 SG_ DecimalSymbolCmd : 22|2@1+ (1,0) [0|3] "" Vector__XXX
 SG_ TimeFormatCmd : 20|2@1+ (1,0) [0|3] "" Vector__XXX
 SG_ LanguageCodeCmd : 0|16@1+ (1,0) [0|16383] "" Vector__XXX

BO_ 2566786814 RESRR: 8 Vector__XXX
 SG_ ActualRepetitionRate : 24|16@1+ (1,0) [0|64255] "ms" Vector__XXX
 SG_ PGN : 0|24@1+ (1,0) [0|16777200] "" Vector__XXX

BO_ 2633895422 WSMSTR: 8 Vector__XXX
 SG_ NumberOfMembers : 0|8@1+ (1,0) [0|0] "" Vector__XXX

BO_ 2633895166 WSMEM: 8 Vector__XXX
 SG_ ArbitraryAddressCapable : 63|1@1+ (1,0) [0|1] "" Vector__XXX
 SG_ ECUInstance : 32|3@1+ (1,0) [0|7] "" Vector__XXX
 SG_ Function : 40|8@1+ (1,0) [0|255] "" Vector__XXX
 SG_ FunctionInstance : 35|5@1+ (1,0) [0|31] "" Vector__XXX
 SG_ IdentityNumber : 0|21@1+ (1,0) [0|2097152] "" Vector__XXX
 SG_ IndustryGroup M : 60|3@1+ (1,0) [0|7] "" Vector__XXX
 SG_ ManufacturerCode : 21|11@1+ (1,0) [0|2047] "" Vector__XXX
 SG_ VehicleSystem m0 : 49|7@1+ (1,0) [0|127] "" Vector__XXX
 SG_ VehicleSystem1 m1 : 49|7@1+ (1,0) [0|127] "" Vector__XXX
 SG_ VehicleSystem2 m2 : 49|7@1+ (1,0) [0|127] "" Vector__XXX
 SG_ VehicleSystem3 m3 : 49|7@1+ (1,0) [0|127] "" Vector__XXX
 SG_ VehicleSystem4 m4 : 49|7@1+ (1,0) [0|127] "" Vector__XXX
 SG_ VehicleSystem5 m5 : 49|7@1+ (1,0) [0|127] "" Vector__XXX
 SG_ VehicleSystemInstance m0 : 56|4@1+ (1,0) [0|15] "" Vector__XXX

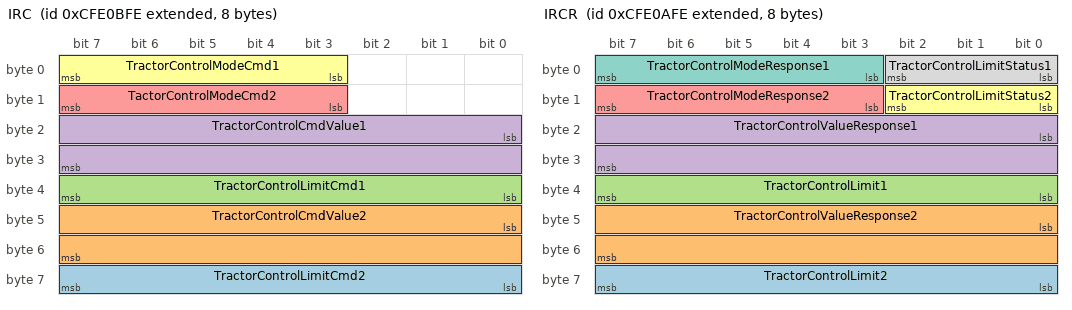
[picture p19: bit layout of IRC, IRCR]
BO_ 2365459454 IRC: 8 Vector__XXX
 SG_ TractorControlLimitCmd2 : 56|8@1- (1,0) [0|0] "" Vector__XXX
 SG_ TractorControlCmdValue2 : 40|16@1+ (1,0) [0|0] "" Vector__XXX
 SG_ TractorControlLimitCmd1 : 32|8@1- (1,0) [0|0] "" Vector__XXX
 SG_ TractorControlCmdValue1 : 16|16@1+ (1,0) [0|0] "" Vector__XXX
 SG_ TactorControlModeCmd2 : 11|5@1+ (1,0) [0|31] "" Vector__XXX
 SG_ TractorControlModeCmd1 : 3|5@1+ (1,0) [0|31] "" Vector__XXX

BO_ 2365459198 IRCR: 8 Vector__XXX
 SG_ TractorControlLimit2 : 56|8@1- (1,0) [0|0] "" Vector__XXX
 SG_ TractorControlValueResponse2 : 40|16@1+ (1,0) [0|0] "" Vector__XXX
 SG_ TractorControlLimit1 : 32|8@1- (1,0) [0|0] "" Vector__XXX
 SG_ TractorControlValueResponse1 : 16|16@1+ (1,0) [0|0] "" Vector__XXX
 SG_ TractorControlModeResponse2 : 11|5@1+ (1,0) [0|31] "" Vector__XXX
 SG_ TractorControlLimitStatus2 : 8|3@1+ (1,0) [0|7] "" Vector__XXX
 SG_ TractorControlModeResponse1 : 3|5@1+ (1,0) [0|31] "" Vector__XXX
 SG_ TractorControlLimitStatus1 : 0|3@1+ (1,0) [0|7] "" Vector__XXX

CM_ BO_ 2566842110 "Time/Date";
CM_ SG_ 2566842110 LocalHourOffset "The hour component of the offset between the UTC (Universal Time Coordinate) time and date and a local time zone time ...";
CM_ SG_ 2566842110 LocalMinuteOffset "The minute component of the offset between the UTC time and date and a local time zone time and date.  This is the ...";
CM_ SG_ 2566842110 Day "The day component of the current calendar date.  This should be reported as the day component of the current date at ...";
CM_ SG_ 2566842110 Hours "The hour component of the current time of day.  This should be reported as the hour component of the current time at ...";
CM_ SG_ 2566842110 Minutes "The minutes component of the current time of day.  This should be reported as the minutes component of the current time ...";
CM_ BO_ 2365475326 "Ground-based Speed and Distance";
CM_ BO_ 2365475070 "Wheel-based Speed and Distance";
CM_ SG_ 2365475070 OperatorDirectionReversed "This parameter indicates whether the reported direction is reversed from the perspective of the operator.";
CM_ BO_ 2566801406 "Message sent by any ECU connected to the implement bus requesting that the Tractor ECU not switch off 
the power for 2 s after it has received the wheel-based speed and distance message indicating that the 
ignition has been switched off. ";
CM_ SG_ 2566801406 ImplementInWorkState "Indicates that an implement is connected to a tractor or power unit and is in work state.";
CM_ BO_ 2365474558 "Secondary or Front Hitch Status";
CM_ SG_ 2365474558 FrontHitchExitReasonCode "This parameter is used to indicate why the front hitch cannot accept remote commands or has most recently 
stopped accepting remote commands. ";
CM_ SG_ 2365474558 FrontHitchPositionLimitStatus "Parameter used to report the tractor ECUs present limit status associated with a parameter whose commands are persistent";
CM_ BO_ 2365474302 "Primary or Rear Hitch Status";
CM_ SG_ 2365474302 RearHitchExitReasonCode "This parameter is used to indicate why the rear hitch cannot accept remote commands or has most recently 
stopped accepting remote commands. ";
CM_ SG_ 2365474302 RearHitchPositionLimitStatus "Parameter used to report the tractor ECUs present limit status associated with a parameter whose commands are persistent";
CM_ BO_ 2365474046 "Pprovides the measurement of the current secondary or front power take-off (PTO) output shaft parameters.";
CM_ SG_ 2365474046 FrontPTOExitReasonCode "This parameter is used to indicate why the front PTO cannot accept remote commands or has most recently 
stopped accepting remote commands.";
CM_ SG_ 2365474046 FrontPTOModeRqStatus "Parameter used to report the tractor ECUs status associated with a parameter whose requests are transient.";
CM_ SG_ 2365474046 FrontPTOEconomyModeRqStatus "Parameter used to report the tractor ECUs status associated with a parameter whose requests are transient.";
CM_ SG_ 2365474046 FrontPTOShaftSpeedLimitStatus "Parameter used to report the tractor ECUs present limit status associated with a parameter whose commands are persistent";
CM_ SG_ 2365474046 FrontPTOEngagementRqStatus "Parameter used to report the tractor ECUs status associated with a parameter whose requests are transient.";
CM_ BO_ 2365473790 "Provides the measurement of the current primary or rear power take-off (PTO) output shaft parameters.
";
CM_ SG_ 2365473790 RearPTOExitReasonCode "This parameter is used to indicate why the rear PTO cannot accept remote commands or has most recently 
stopped accepting remote commands.";
CM_ SG_ 2365473790 RearPTOModeRqStatus "Parameter used to report the tractor ECUs status associated with a parameter whose requests are transient.";
CM_ SG_ 2365473790 RearPTOEconomyModeRqStatus "Parameter used to report the tractor ECUs status associated with a parameter whose requests are transient.";
CM_ SG_ 2365473790 RearPTOShaftSpeedLimitStatus "Parameter used to report the tractor ECUs present limit status associated with a parameter whose commands are persistent";
CM_ SG_ 2365473790 RearPTOEngagementRqStatus "Parameter used to report the tractor ECUs status associated with a parameter whose requests are transient.";
CM_ BO_ 2365473534 "Hitch and PTO Commands";
CM_ BO_ 2365473278 "Lighting Command";
CM_ BO_ 2566799614 "Lighting Data";
CM_ BO_ 2365472766 "Auxiliary Valve Command";
CM_ BO_ 2365472510 "Auxiliary Valve Command";
CM_ BO_ 2365472254 "Auxiliary Valve Command";
CM_ BO_ 2365471998 "Auxiliary Valve Command";
CM_ BO_ 2365471742 "Auxiliary Valve Command";
CM_ BO_ 2365471486 "Auxiliary Valve Command";
CM_ BO_ 2365471230 "Auxiliary Valve Command";
CM_ BO_ 2365470974 "Auxiliary Valve Command";
CM_ BO_ 2365470718 "Auxiliary Valve Command";
CM_ BO_ 2365470462 "Auxiliary Valve Command";
CM_ BO_ 2365470206 "Auxiliary Valve Command";
CM_ BO_ 2365469950 "Auxiliary Valve Command";
CM_ BO_ 2365469694 "Auxiliary Valve Command";
CM_ BO_ 2365469438 "Auxiliary Valve Command";
CM_ BO_ 2365469182 "Auxiliary Valve Command";
CM_ BO_ 2365468926 "Auxiliary Valve Command";
CM_ BO_ 2365468670 "Auxiliary valve measured flow";
CM_ SG_ 2365468670 Valve15LimitStatus "Parameter used to report the tractor ECUs present limit status associated with a parameter whose commands are persistent";
CM_ BO_ 2365468414 "Auxiliary valve measured flow";
CM_ SG_ 2365468414 Valve14LimitStatus "Parameter used to report the tractor ECUs present limit status associated with a parameter whose commands are persistent";
CM_ BO_ 2365468158 "Auxiliary valve measured flow";
CM_ SG_ 2365468158 Valve13LimitStatus "Parameter used to report the tractor ECUs present limit status associated with a parameter whose commands are persistent";
CM_ BO_ 2365467902 "Auxiliary valve measured flow";
CM_ SG_ 2365467902 Valve12LimitStatus "Parameter used to report the tractor ECUs present limit status associated with a parameter whose commands are persistent";
CM_ BO_ 2365467646 "Auxiliary valve measured flow";
CM_ SG_ 2365467646 Valve11LimitStatus "Parameter used to report the tractor ECUs present limit status associated with a parameter whose commands are persistent";
CM_ BO_ 2365467390 "Auxiliary valve measured flow";
CM_ SG_ 2365467390 Valve10LimitStatus "Parameter used to report the tractor ECUs present limit status associated with a parameter whose commands are persistent";
CM_ BO_ 2365467134 "Auxiliary valve measured flow";
CM_ SG_ 2365467134 Valve9LimitStatus "Parameter used to report the tractor ECUs present limit status associated with a parameter whose commands are persistent";
CM_ BO_ 2365466878 "Auxiliary valve measured flow";
CM_ SG_ 2365466878 Valve8LimitStatus "Parameter used to report the tractor ECUs present limit status associated with a parameter whose commands are persistent";
CM_ BO_ 2365466622 "Auxiliary valve measured flow";
CM_ SG_ 2365466622 Valve7LimitStatus "Parameter used to report the tractor ECUs present limit status associated with a parameter whose commands are persistent";
CM_ BO_ 2365466366 "Auxiliary valve measured flow";
CM_ SG_ 2365466366 Valve6LimitStatus "Parameter used to report the tractor ECUs present limit status associated with a parameter whose commands are persistent";
CM_ BO_ 2365466110 "Auxiliary valve measured flow";
CM_ SG_ 2365466110 Valve5LimitStatus "Parameter used to report the tractor ECUs present limit status associated with a parameter whose commands are persistent";
CM_ BO_ 2365465854 "Auxiliary valve measured flow";
CM_ SG_ 2365465854 Valve4LimitStatus "Parameter used to report the tractor ECUs present limit status associated with a parameter whose commands are persistent";
CM_ BO_ 2365465598 "Auxiliary valve measured flow";
CM_ SG_ 2365465598 Valve3LimitStatus "Parameter used to report the tractor ECUs present limit status associated with a parameter whose commands are persistent";
CM_ BO_ 2365465342 "Auxiliary valve measured flow";
CM_ SG_ 2365465342 Valve2LimitStatus "Parameter used to report the tractor ECUs present limit status associated with a parameter whose commands are persistent";
CM_ BO_ 2365465086 "Auxiliary valve measured flow";
CM_ SG_ 2365465086 Valve1LimitStatus "Parameter used to report the tractor ECUs present limit status associated with a parameter whose commands are persistent";
CM_ BO_ 2365464830 "Auxiliary valve measured flow";
CM_ SG_ 2365464830 Valve0LimitStatus "Parameter used to report the tractor ECUs present limit status associated with a parameter whose commands are persistent";
CM_ BO_ 2365464574 "Esimated flow of auxiliary valve number 0 ";
CM_ SG_ 2365464574 AuxValve15ExitReasonCode "This parameter is used to indicate why the auxiliary valve 15 cannot accept remote commands or has most 
recently stopped accepting remote commands.";
CM_ SG_ 2365464574 Valve15LimitStatus "Parameter used to report the tractor ECUs present limit status associated with a parameter whose commands are persistent";
CM_ BO_ 2365464318 "Esimated flow of auxiliary valve number 0 ";
CM_ SG_ 2365464318 Valve14LimitStatus "Parameter used to report the tractor ECUs present limit status associated with a parameter whose commands are persistent";
CM_ BO_ 2365464062 "Esimated flow of auxiliary valve number 0 ";
CM_ SG_ 2365464062 Valve13LimitStatus "Parameter used to report the tractor ECUs present limit status associated with a parameter whose commands are persistent";
CM_ BO_ 2365463806 "Esimated flow of auxiliary valve number 0 ";
CM_ SG_ 2365463806 Valve12LimitStatus "Parameter used to report the tractor ECUs present limit status associated with a parameter whose commands are persistent";
CM_ BO_ 2365463550 "Esimated flow of auxiliary valve number 0 ";
CM_ SG_ 2365463550 Valve11LimitStatus "Parameter used to report the tractor ECUs present limit status associated with a parameter whose commands are persistent";
CM_ BO_ 2365463294 "Esimated flow of auxiliary valve number 0 ";
CM_ SG_ 2365463294 Valve10LimitStatus "Parameter used to report the tractor ECUs present limit status associated with a parameter whose commands are persistent";
CM_ BO_ 2365463038 "Esimated flow of auxiliary valve number 0 ";
CM_ SG_ 2365463038 Valve9LimitStatus "Parameter used to report the tractor ECUs present limit status associated with a parameter whose commands are persistent";
CM_ BO_ 2365462782 "Esimated flow of auxiliary valve number 0 ";
CM_ SG_ 2365462782 Valve8LimitStatus "Parameter used to report the tractor ECUs present limit status associated with a parameter whose commands are persistent";
CM_ BO_ 2365462526 "Esimated flow of auxiliary valve number 0 ";
CM_ SG_ 2365462526 Valve7LimitStatus "Parameter used to report the tractor ECUs present limit status associated with a parameter whose commands are persistent";
CM_ BO_ 2365462270 "Esimated flow of auxiliary valve number 0 ";
CM_ SG_ 2365462270 Valve6LimitStatus "Parameter used to report the tractor ECUs present limit status associated with a parameter whose commands are persistent";
CM_ BO_ 2365462014 "Esimated flow of auxiliary valve number 0 ";
CM_ SG_ 2365462014 Valve5LimitStatus "Parameter used to report the tractor ECUs present limit status associated with a parameter whose commands are persistent";
CM_ BO_ 2365461758 "Esimated flow of auxiliary valve number 0 ";
CM_ SG_ 2365461758 Valve4LimitStatus "Parameter used to report the tractor ECUs present limit status associated with a parameter whose commands are persistent";
CM_ BO_ 2365461502 "Esimated flow of auxiliary valve number 0 ";
CM_ SG_ 2365461502 Valve3LimitStatus "Parameter used to report the tractor ECUs present limit status associated with a parameter whose commands are persistent";
CM_ BO_ 2365461246 "Esimated flow of auxiliary valve number 0 ";
CM_ SG_ 2365461246 Valve2LimitStatus "Parameter used to report the tractor ECUs present limit status associated with a parameter whose commands are persistent";
CM_ BO_ 2365460990 "Esimated flow of auxiliary valve number 0 ";
CM_ SG_ 2365460990 Valve1LimitStatus "Parameter used to report the tractor ECUs present limit status associated with a parameter whose commands are persistent";
CM_ BO_ 2365460734 "Esimated flow of auxiliary valve number 0 ";
CM_ SG_ 2365460734 AuxValveNum0ExitReasonCode "This parameter is used to indicate why the auxiliary valve 0 cannot accept remote commands or has most 
recently stopped accepting remote commands.";
CM_ SG_ 2365460734 Valve0LimitStatus "Parameter used to report the tractor ECUs present limit status associated with a parameter whose commands are persistent";
CM_ BO_ 2566787070 "Language Command";
CM_ BO_ 2566786814 "Response for Repetition Rate";
CM_ BO_ 2633895422 "Working Set Master";
CM_ BO_ 2633895166 "Working Set Member";
CM_ BO_ 2365459454 "Tractor control mode command (previously: Implement remote control command)";
CM_ BO_ 2365459198 "Tractor control command tractor response (previoulsy: Implement remote control command Tractor response)";
CM_ SG_ 2365459198 TractorControlLimitStatus2 "Parameter used to report the tractor ECUs present limit status associated with a parameter whose commands are persistent";
CM_ SG_ 2365459198 TractorControlLimitStatus1 "Parameter used to report the tractor ECUs present limit status associated with a parameter whose commands are persistent";
BA_DEF_ SG_  "DDI" INT 0 65535;
BA_DEF_ BO_  "SingleFrame" INT 0 1;
BA_DEF_ BO_  "VFrameFormat" ENUM  "StandardCAN","ExtendedCAN","reserved","J1939PG","vector_leerstring";
BA_DEF_ BO_  "GenMsgSendType" ENUM  "cyclic","NotUsed","IfActive","NotUsed","NotUsed","NotUsed","NotUsed","NotUsed","noMsgSendType","vector_leerstring";
BA_DEF_ BO_  "GenMsgCycleTime" INT 0 3600000;
BA_DEF_ BO_  "GenMsgRequestable" INT 0 1;
BA_DEF_ BO_  "GenMsgCycleTimeFast" INT 0 3600000;
BA_DEF_ SG_  "SPN" INT 0 524287;
BA_DEF_ SG_  "GenSigSendType" ENUM  "Cyclic","OnWrite","OnWriteWithRepetition","OnChange","OnChangeWithRepetition","IfActive","IfActiveWithRepetition","NoSigSendType";
BA_DEF_ SG_  "SigType" ENUM  "Default","Range","RangeSigned","ASCII","Discrete","Control","ReferencePGN","DTC","StringDelimiter","StringLength","StringLengthControl","MessageCounter","MessageChecksum";
BA_DEF_ SG_  "GenSigStartValue" INT -2147483648 2147483647;
BA_DEF_ SG_  "SystemSignalLongSymbol" STRING ;
BA_DEF_DEF_  "DDI" 0;
BA_DEF_DEF_  "SingleFrame" 1;
BA_DEF_DEF_  "VFrameFormat" "J1939PG";
BA_DEF_DEF_  "GenMsgSendType" "noMsgSendType";
BA_DEF_DEF_  "GenMsgCycleTime" 0;
BA_DEF_DEF_  "GenMsgRequestable" 1;
BA_DEF_DEF_  "GenMsgCycleTimeFast" 0;
BA_DEF_DEF_  "SPN" 0;
BA_DEF_DEF_  "GenSigSendType" "NoSigSendType";
BA_DEF_DEF_  "SigType" "Default";
BA_DEF_DEF_  "GenSigStartValue" 0;
BA_DEF_DEF_  "SystemSignalLongSymbol" "";
BA_ "GenMsgSendType" BO_ 2365475326 8.53594844804822E-317;
BA_ "GenMsgCycleTime" BO_ 2365475326 100;
BA_ "GenMsgSendType" BO_ 2365475070 8.53733973690691E-317;
BA_ "GenMsgCycleTime" BO_ 2365475070 100;
BA_ "GenMsgCycleTime" BO_ 2566801406 100;
BA_ "GenMsgSendType" BO_ 2365474558 8.53967963180561E-317;
BA_ "GenMsgCycleTime" BO_ 2365474558 100;
BA_ "GenMsgSendType" BO_ 2365474302 8.54054523481712E-317;
BA_ "GenMsgCycleTime" BO_ 2365474302 100;
BA_ "GenMsgSendType" BO_ 2365474046 2;
BA_ "GenMsgCycleTime" BO_ 2365474046 100;
BA_ "GenMsgSendType" BO_ 2365473790 2;
BA_ "GenMsgCycleTime" BO_ 2365473790 100;
BA_ "GenMsgSendType" BO_ 2365473534 8.54526850239137E-317;
BA_ "GenMsgCycleTime" BO_ 2365473534 1000;
BA_ "GenMsgCycleTime" BO_ 2365473278 100;
BA_ "GenMsgCycleTime" BO_ 2566799614 100;
BA_ "GenMsgSendType" BO_ 2365472766 8.56219716768047E-317;
BA_ "GenMsgCycleTime" BO_ 2365472766 1000;
BA_ "GenMsgSendType" BO_ 2365472510 8.56296395756282E-317;
BA_ "GenMsgCycleTime" BO_ 2365472510 1000;
BA_ "GenMsgSendType" BO_ 2365472254 8.56373074744516E-317;
BA_ "GenMsgCycleTime" BO_ 2365472254 1000;
BA_ "GenMsgSendType" BO_ 2365471998 8.56449753732751E-317;
BA_ "GenMsgCycleTime" BO_ 2365471998 1000;
BA_ "GenMsgSendType" BO_ 2365471742 8.56526432720985E-317;
BA_ "GenMsgCycleTime" BO_ 2365471742 1000;
BA_ "GenMsgSendType" BO_ 2365471486 8.5660311170922E-317;
BA_ "GenMsgCycleTime" BO_ 2365471486 1000;
BA_ "GenMsgSendType" BO_ 2365471230 8.56679790697454E-317;
BA_ "GenMsgCycleTime" BO_ 2365471230 1000;
BA_ "GenMsgSendType" BO_ 2365470974 8.56756469685689E-317;
BA_ "GenMsgCycleTime" BO_ 2365470974 1000;
BA_ "GenMsgSendType" BO_ 2365470718 8.5683354392644E-317;
BA_ "GenMsgCycleTime" BO_ 2365470718 1000;
BA_ "GenMsgSendType" BO_ 2365470462 8.56910222914675E-317;
BA_ "GenMsgCycleTime" BO_ 2365470462 1000;
BA_ "GenMsgSendType" BO_ 2365470206 8.56986901902909E-317;
BA_ "GenMsgCycleTime" BO_ 2365470206 1000;
BA_ "GenMsgSendType" BO_ 2365469950 8.57063976143661E-317;
BA_ "GenMsgCycleTime" BO_ 2365469950 1000;
BA_ "GenMsgSendType" BO_ 2365469694 8.57140655131895E-317;
BA_ "GenMsgCycleTime" BO_ 2365469694 1000;
BA_ "GenMsgSendType" BO_ 2365469438 8.5721733412013E-317;
BA_ "GenMsgCycleTime" BO_ 2365469438 1000;
BA_ "GenMsgSendType" BO_ 2365469182 8.57294013108364E-317;
BA_ "GenMsgCycleTime" BO_ 2365469182 1000;
BA_ "GenMsgSendType" BO_ 2365468926 8.57370692096599E-317;
BA_ "GenMsgCycleTime" BO_ 2365468926 1000;
BA_ "GenMsgSendType" BO_ 2365468670 8.5746199542795E-317;
BA_ "GenMsgCycleTime" BO_ 2365468670 100;
BA_ "GenMsgSendType" BO_ 2365468414 8.57553298759302E-317;
BA_ "GenMsgCycleTime" BO_ 2365468414 100;
BA_ "GenMsgSendType" BO_ 2365468158 8.5764499734317E-317;
BA_ "GenMsgCycleTime" BO_ 2365468158 100;
BA_ "GenMsgSendType" BO_ 2365467902 8.57736300674521E-317;
BA_ "GenMsgCycleTime" BO_ 2365467902 100;
BA_ "GenMsgSendType" BO_ 2365467646 8.57827604005873E-317;
BA_ "GenMsgCycleTime" BO_ 2365467646 100;
BA_ "GenMsgSendType" BO_ 2365467390 8.57918907337224E-317;
BA_ "GenMsgCycleTime" BO_ 2365467390 100;
BA_ "GenMsgSendType" BO_ 2365467134 8.58010210668576E-317;
BA_ "GenMsgCycleTime" BO_ 2365467134 100;
BA_ "GenMsgSendType" BO_ 2365466878 8.58101513999927E-317;
BA_ "GenMsgCycleTime" BO_ 2365466878 100;
BA_ "GenMsgSendType" BO_ 2365466622 8.58192817331279E-317;
BA_ "GenMsgCycleTime" BO_ 2365466622 100;
BA_ "GenMsgSendType" BO_ 2365466366 8.58284515915147E-317;
BA_ "GenMsgCycleTime" BO_ 2365466366 100;
BA_ "GenMsgSendType" BO_ 2365466110 8.58375819246498E-317;
BA_ "GenMsgCycleTime" BO_ 2365466110 100;
BA_ "GenMsgSendType" BO_ 2365465854 8.5846712257785E-317;
BA_ "GenMsgCycleTime" BO_ 2365465854 100;
BA_ "GenMsgSendType" BO_ 2365465598 8.58558425909201E-317;
BA_ "GenMsgCycleTime" BO_ 2365465598 100;
BA_ "GenMsgSendType" BO_ 2365465342 8.58649729240553E-317;
BA_ "GenMsgCycleTime" BO_ 2365465342 100;
BA_ "GenMsgSendType" BO_ 2365465086 8.58741032571904E-317;
BA_ "GenMsgCycleTime" BO_ 2365465086 100;
BA_ "GenMsgSendType" BO_ 2365464830 8.58832335903256E-317;
BA_ "GenMsgCycleTime" BO_ 2365464830 100;
BA_ "GenMsgSendType" BO_ 2365464574 8.5893154428494E-317;
BA_ "GenMsgCycleTime" BO_ 2365464574 100;
BA_ "GenMsgSendType" BO_ 2365464318 8.59030752666625E-317;
BA_ "GenMsgCycleTime" BO_ 2365464318 100;
BA_ "GenMsgSendType" BO_ 2365464062 8.5912996104831E-317;
BA_ "GenMsgCycleTime" BO_ 2365464062 100;
BA_ "GenMsgSendType" BO_ 2365463806 8.59229169429995E-317;
BA_ "GenMsgCycleTime" BO_ 2365463806 100;
BA_ "GenMsgSendType" BO_ 2365463550 8.5932837781168E-317;
BA_ "GenMsgCycleTime" BO_ 2365463550 100;
BA_ "GenMsgSendType" BO_ 2365463294 8.59427586193365E-317;
BA_ "GenMsgCycleTime" BO_ 2365463294 100;
BA_ "GenMsgSendType" BO_ 2365463038 8.5952679457505E-317;
BA_ "GenMsgCycleTime" BO_ 2365463038 100;
BA_ "GenMsgSendType" BO_ 2365462782 8.59626002956735E-317;
BA_ "GenMsgCycleTime" BO_ 2365462782 100;
BA_ "GenMsgSendType" BO_ 2365462526 8.5972521133842E-317;
BA_ "GenMsgCycleTime" BO_ 2365462526 100;
BA_ "GenMsgSendType" BO_ 2365462270 8.59824419720105E-317;
BA_ "GenMsgCycleTime" BO_ 2365462270 100;
BA_ "GenMsgSendType" BO_ 2365462014 8.5992362810179E-317;
BA_ "GenMsgCycleTime" BO_ 2365462014 100;
BA_ "GenMsgSendType" BO_ 2365461758 8.60022836483475E-317;
BA_ "GenMsgCycleTime" BO_ 2365461758 100;
BA_ "GenMsgSendType" BO_ 2365461502 8.60122044865159E-317;
BA_ "GenMsgCycleTime" BO_ 2365461502 100;
BA_ "GenMsgSendType" BO_ 2365461246 8.60221253246844E-317;
BA_ "GenMsgCycleTime" BO_ 2365461246 100;
BA_ "GenMsgSendType" BO_ 2365460990 8.60320856881046E-317;
BA_ "GenMsgCycleTime" BO_ 2365460990 100;
BA_ "GenMsgSendType" BO_ 2365460734 8.60420065262731E-317;
BA_ "GenMsgCycleTime" BO_ 2365460734 100;
BA_ "GenMsgCycleTime" BO_ 2566787070 100;
BA_ "GenMsgCycleTime" BO_ 2566786814 100;
BA_ "GenMsgSendType" BO_ 2365459454 8.61276577466361E-317;
BA_ "GenMsgCycleTime" BO_ 2365459454 100;
BA_ "GenMsgCycleTime" BO_ 2365459198 100;
BA_ "SigType" SG_ 2566842110 LocalHourOffset 1;
BA_ "SPN" SG_ 2566842110 LocalHourOffset 1602;
BA_ "SigType" SG_ 2566842110 LocalMinuteOffset 1;
BA_ "SPN" SG_ 2566842110 LocalMinuteOffset 1601;
BA_ "SigType" SG_ 2566842110 Year 1;
BA_ "SPN" SG_ 2566842110 Year 964;
BA_ "SigType" SG_ 2566842110 Day 1;
BA_ "SPN" SG_ 2566842110 Day 962;
BA_ "SigType" SG_ 2566842110 Month 1;
BA_ "SPN" SG_ 2566842110 Month 963;
BA_ "SigType" SG_ 2566842110 Hours 1;
BA_ "SPN" SG_ 2566842110 Hours 961;
BA_ "SigType" SG_ 2566842110 Minutes 1;
BA_ "SPN" SG_ 2566842110 Minutes 960;
BA_ "SigType" SG_ 2566842110 Seconds 1;
BA_ "SPN" SG_ 2566842110 Seconds 959;
BA_ "SigType" SG_ 2365475326 GroundBasedMachineDirection 4;
BA_ "SPN" SG_ 2365475326 GroundBasedMachineDirection 1861;
BA_ "SigType" SG_ 2365475326 GroundBasedMachineDistance 1;
BA_ "SPN" SG_ 2365475326 GroundBasedMachineDistance 1860;
BA_ "SigType" SG_ 2365475326 GroundBasedMachineSpeed 1;
BA_ "SPN" SG_ 2365475326 GroundBasedMachineSpeed 1859;
BA_ "SigType" SG_ 2365475070 OperatorDirectionReversed 5;
BA_ "SPN" SG_ 2365475070 OperatorDirectionReversed 5244;
BA_ "SigType" SG_ 2365475070 StartStopState 4;
BA_ "SPN" SG_ 2365475070 StartStopState 5203;
BA_ "SigType" SG_ 2365475070 KeySwitchState 4;
BA_ "SPN" SG_ 2365475070 KeySwitchState 1865;
BA_ "SigType" SG_ 2365475070 WheelBasedMachineDirection 4;
BA_ "SPN" SG_ 2365475070 WheelBasedMachineDirection 1864;
BA_ "SigType" SG_ 2365475070 MaxTimeOfTractorPower 1;
BA_ "SPN" SG_ 2365475070 MaxTimeOfTractorPower 1866;
BA_ "SigType" SG_ 2365475070 WheelBasedMachineDistance 1;
BA_ "SPN" SG_ 2365475070 WheelBasedMachineDistance 1863;
BA_ "SigType" SG_ 2365475070 WheelBasedMachineSpeed 1;
BA_ "SPN" SG_ 2365475070 WheelBasedMachineSpeed 1862;
BA_ "SPN" SG_ 2566801406 ImplementInWorkState 7447;
BA_ "SigType" SG_ 2566801406 ImplementInWorkState 4;
BA_ "SigType" SG_ 2566801406 ImplementTransportState 4;
BA_ "SPN" SG_ 2566801406 ImplementTransportState 1869;
BA_ "SigType" SG_ 2566801406 ImplementParkState 4;
BA_ "SPN" SG_ 2566801406 ImplementParkState 1870;
BA_ "SigType" SG_ 2566801406 ImplementReadyToWorkState 4;
BA_ "SPN" SG_ 2566801406 ImplementReadyToWorkState 1871;
BA_ "SigType" SG_ 2566801406 MaintainECUPower 4;
BA_ "SPN" SG_ 2566801406 MaintainECUPower 1867;
BA_ "SigType" SG_ 2566801406 MaintainActuatorPower 4;
BA_ "SPN" SG_ 2566801406 MaintainActuatorPower 1868;
BA_ "SPN" SG_ 2365474558 FrontHitchExitReasonCode 5816;
BA_ "SigType" SG_ 2365474558 FrontDraft 1;
BA_ "SPN" SG_ 2365474558 FrontDraft 1878;
BA_ "SigType" SG_ 2365474558 FrontNominalLowerLinkForce 1;
BA_ "SPN" SG_ 2365474558 FrontNominalLowerLinkForce 1880;
BA_ "SigType" SG_ 2365474558 FrontHitchInWorkIndication 4;
BA_ "SPN" SG_ 2365474558 FrontHitchInWorkIndication 1876;
BA_ "SPN" SG_ 2365474558 FrontHitchPositionLimitStatus 5150;
BA_ "SigType" SG_ 2365474558 FrontHitchPosition 1;
BA_ "SPN" SG_ 2365474558 FrontHitchPosition 1872;
BA_ "SPN" SG_ 2365474302 RearHitchExitReasonCode 5819;
BA_ "SigType" SG_ 2365474302 RearDraft 1;
BA_ "SPN" SG_ 2365474302 RearDraft 1879;
BA_ "SigType" SG_ 2365474302 RearNominalPowerLinkForce 1;
BA_ "SPN" SG_ 2365474302 RearNominalPowerLinkForce 1881;
BA_ "SigType" SG_ 2365474302 RearHitchInWorkIndication 4;
BA_ "SPN" SG_ 2365474302 RearHitchInWorkIndication 1877;
BA_ "SPN" SG_ 2365474302 RearHitchPositionLimitStatus 5151;
BA_ "SigType" SG_ 2365474302 RearHitchPosition 1;
BA_ "SPN" SG_ 2365474302 RearHitchPosition 1873;
BA_ "SPN" SG_ 2365474046 FrontPTOExitReasonCode 5817;
BA_ "SigType" SG_ 2365474046 FrontPTOModeRqStatus 4;
BA_ "SPN" SG_ 2365474046 FrontPTOModeRqStatus 5153;
BA_ "SigType" SG_ 2365474046 FrontPTOEconomyModeRqStatus 4;
BA_ "SPN" SG_ 2365474046 FrontPTOEconomyModeRqStatus 5154;
BA_ "SPN" SG_ 2365474046 FrontPTOShaftSpeedLimitStatus 5155;
BA_ "SigType" SG_ 2365474046 FrontPTOEngagement 4;
BA_ "SPN" SG_ 2365474046 FrontPTOEngagement 1888;
BA_ "SigType" SG_ 2365474046 FrontPTOMode 4;
BA_ "SPN" SG_ 2365474046 FrontPTOMode 1889;
BA_ "SigType" SG_ 2365474046 FrontPTOEconomyMode 4;
BA_ "SPN" SG_ 2365474046 FrontPTOEconomyMode 1891;
BA_ "SigType" SG_ 2365474046 FrontPTOEngagementRqStatus 4;
BA_ "SPN" SG_ 2365474046 FrontPTOEngagementRqStatus 5152;
BA_ "SigType" SG_ 2365474046 FrontPTOOutShaftSpeedSetPoint 1;
BA_ "SPN" SG_ 2365474046 FrontPTOOutShaftSpeedSetPoint 1884;
BA_ "SigType" SG_ 2365474046 FrontPTOOutShaftSpeed 1;
BA_ "SPN" SG_ 2365474046 FrontPTOOutShaftSpeed 1882;
BA_ "SPN" SG_ 2365473790 RearPTOExitReasonCode 5820;
BA_ "SigType" SG_ 2365473790 RearPTOModeRqStatus 4;
BA_ "SPN" SG_ 2365473790 RearPTOModeRqStatus 5157;
BA_ "SigType" SG_ 2365473790 RearPTOEconomyModeRqStatus 4;
BA_ "SPN" SG_ 2365473790 RearPTOEconomyModeRqStatus 5158;
BA_ "SPN" SG_ 2365473790 RearPTOShaftSpeedLimitStatus 5159;
BA_ "SigType" SG_ 2365473790 RearPTOEngagement 4;
BA_ "SPN" SG_ 2365473790 RearPTOEngagement 2408;
BA_ "SigType" SG_ 2365473790 RearPTOMode 4;
BA_ "SPN" SG_ 2365473790 RearPTOMode 1890;
BA_ "SigType" SG_ 2365473790 RearPTOEconomyMode 4;
BA_ "SPN" SG_ 2365473790 RearPTOEconomyMode 1892;
BA_ "SigType" SG_ 2365473790 RearPTOEngagementRqStatus 4;
BA_ "SPN" SG_ 2365473790 RearPTOEngagementRqStatus 5156;
BA_ "SigType" SG_ 2365473790 RearPTOOutputShaftSpeedSetPoint 1;
BA_ "SPN" SG_ 2365473790 RearPTOOutputShaftSpeedSetPoint 1885;
BA_ "SigType" SG_ 2365473790 RearPTOOutputShaftSpeed 1;
BA_ "SPN" SG_ 2365473790 RearPTOOutputShaftSpeed 1883;
BA_ "SigType" SG_ 2365473534 FrontPTOModeCmd 4;
BA_ "SPN" SG_ 2365473534 FrontPTOModeCmd 1895;
BA_ "SigType" SG_ 2365473534 RearPTOModeCmd 4;
BA_ "SPN" SG_ 2365473534 RearPTOModeCmd 1896;
BA_ "SigType" SG_ 2365473534 FrontPTOEconomyModeCmd 4;
BA_ "SPN" SG_ 2365473534 FrontPTOEconomyModeCmd 1897;
BA_ "SigType" SG_ 2365473534 RearPTOEconomyModeCmd 4;
BA_ "SPN" SG_ 2365473534 RearPTOEconomyModeCmd 1898;
BA_ "SigType" SG_ 2365473534 FrontPTOEngagementCmd 4;
BA_ "SPN" SG_ 2365473534 FrontPTOEngagementCmd 1893;
BA_ "SigType" SG_ 2365473534 RearPTOEngagementCmd 4;
BA_ "SPN" SG_ 2365473534 RearPTOEngagementCmd 1894;
BA_ "SigType" SG_ 2365473534 RearPTOOutShaftSpeedSetPointCmd 1;
BA_ "SPN" SG_ 2365473534 RearPTOOutShaftSpeedSetPointCmd 1887;
BA_ "SigType" SG_ 2365473534 FrontPTOOutShaftSpeedSetPointCmd 1;
BA_ "SPN" SG_ 2365473534 FrontPTOOutShaftSpeedSetPointCmd 1886;
BA_ "SigType" SG_ 2365473534 RearHitchPositionCmd 1;
BA_ "SPN" SG_ 2365473534 RearHitchPositionCmd 1875;
BA_ "SigType" SG_ 2365473534 FrontHitchPositionCmd 1;
BA_ "SPN" SG_ 2365473534 FrontHitchPositionCmd 1874;
BA_ "SPN" SG_ 2365473278 ImplementRearWorkLightCmd 2405;
BA_ "SigType" SG_ 2365473278 ImplementRearWorkLightCmd 4;
BA_ "SPN" SG_ 2365473278 ImplementLeftFacingWorkLightCmd 2399;
BA_ "SigType" SG_ 2365473278 ImplementLeftFacingWorkLightCmd 4;
BA_ "SPN" SG_ 2365473278 ImplementRightFacingWorkLightCmd 2401;
BA_ "SigType" SG_ 2365473278 ImplementRightFacingWorkLightCmd 4;
BA_ "SPN" SG_ 2365473278 LightingDataRequestCmd 2393;
BA_ "SigType" SG_ 2365473278 LightingDataRequestCmd 4;
BA_ "SPN" SG_ 2365473278 ImplementLeftForwardLightCmd 2597;
BA_ "SigType" SG_ 2365473278 ImplementLeftForwardLightCmd 4;
BA_ "SPN" SG_ 2365473278 ImplementRightForwardLightCmd 2406;
BA_ "SigType" SG_ 2365473278 ImplementRightForwardLightCmd 4;
BA_ "SPN" SG_ 2365473278 ImplementOEMOption1LightCmd 2395;
BA_ "SigType" SG_ 2365473278 ImplementOEMOption1LightCmd 4;
BA_ "SPN" SG_ 2365473278 ImplementOEMOption2LightCmd 2397;
BA_ "SigType" SG_ 2365473278 ImplementOEMOption2LightCmd 4;
BA_ "SPN" SG_ 2365473278 TractorFrontHighWorkLightCmd 2355;
BA_ "SigType" SG_ 2365473278 TractorFrontHighWorkLightCmd 4;
BA_ "SPN" SG_ 2365473278 TractorFrontLowWorkLightCmd 2353;
BA_ "SigType" SG_ 2365473278 TractorFrontLowWorkLightCmd 4;
BA_ "SPN" SG_ 2365473278 TractorSideHighWorkLightCmd 2365;
BA_ "SigType" SG_ 2365473278 TractorSideHighWorkLightCmd 4;
BA_ "SPN" SG_ 2365473278 TractorSideLowWorkLightCmd 2363;
BA_ "SigType" SG_ 2365473278 TractorSideLowWorkLightCmd 4;
BA_ "SPN" SG_ 2365473278 TractorRearHighWorkLightCmd 2361;
BA_ "SigType" SG_ 2365473278 TractorRearHighWorkLightCmd 4;
BA_ "SPN" SG_ 2365473278 TractorRearLowWorkLightCmd 2359;
BA_ "SigType" SG_ 2365473278 TractorRearLowWorkLightCmd 4;
BA_ "SPN" SG_ 2365473278 TractorUndersideWorkLightCmd 2357;
BA_ "SigType" SG_ 2365473278 TractorUndersideWorkLightCmd 4;
BA_ "SPN" SG_ 2365473278 RearFogLightCmd 2389;
BA_ "SigType" SG_ 2365473278 RearFogLightCmd 4;
BA_ "SPN" SG_ 2365473278 TractorMarkerLightCmd 2377;
BA_ "SigType" SG_ 2365473278 TractorMarkerLightCmd 4;
BA_ "SPN" SG_ 2365473278 ImplementMarkerLightCmd 2379;
BA_ "SigType" SG_ 2365473278 ImplementMarkerLightCmd 4;
BA_ "SPN" SG_ 2365473278 TractorClearanceLightCmd 2381;
BA_ "SigType" SG_ 2365473278 TractorClearanceLightCmd 4;
BA_ "SPN" SG_ 2365473278 ImplementClearanceLightCmd 2383;
BA_ "SigType" SG_ 2365473278 ImplementClearanceLightCmd 4;
BA_ "SPN" SG_ 2365473278 LeftStopLightCmd 2371;
BA_ "SigType" SG_ 2365473278 LeftStopLightCmd 4;
BA_ "SPN" SG_ 2365473278 RightStopLightCmd 2373;
BA_ "SigType" SG_ 2365473278 RightStopLightCmd 4;
BA_ "SPN" SG_ 2365473278 CentreStopLightCmd 2375;
BA_ "SigType" SG_ 2365473278 CentreStopLightCmd 4;
BA_ "SPN" SG_ 2365473278 BackUpLightAndAlarmHornCmd 2391;
BA_ "SigType" SG_ 2365473278 BackUpLightAndAlarmHornCmd 4;
BA_ "SPN" SG_ 2365473278 LeftTurnSignalLightCmd 2367;
BA_ "SigType" SG_ 2365473278 LeftTurnSignalLightCmd 4;
BA_ "SPN" SG_ 2365473278 RightTurnSignalLightCmd 2369;
BA_ "SigType" SG_ 2365473278 RightTurnSignalLightCmd 4;
BA_ "SPN" SG_ 2365473278 RotatingBeaconLightCmd 2385;
BA_ "SigType" SG_ 2365473278 RotatingBeaconLightCmd 4;
BA_ "SPN" SG_ 2365473278 TractorFrontFogLightCmd 2387;
BA_ "SigType" SG_ 2365473278 TractorFrontFogLightCmd 4;
BA_ "SPN" SG_ 2365473278 HighBeamHeadLightCmd 2347;
BA_ "SigType" SG_ 2365473278 HighBeamHeadLightCmd 4;
BA_ "SPN" SG_ 2365473278 LowBeamHeadLightCmd 2349;
BA_ "SigType" SG_ 2365473278 LowBeamHeadLightCmd 4;
BA_ "SPN" SG_ 2365473278 AlternateHeadLightCmd 2351;
BA_ "SigType" SG_ 2365473278 AlternateHeadLightCmd 4;
BA_ "SPN" SG_ 2365473278 DaytimeRunningLightCmd 2403;
BA_ "SigType" SG_ 2365473278 DaytimeRunningLightCmd 4;
BA_ "SPN" SG_ 2566799614 ImplementRearWorkLightData 2394;
BA_ "SigType" SG_ 2566799614 ImplementRearWorkLightData 4;
BA_ "SPN" SG_ 2566799614 ImplLeftFacingWorkLightData 2400;
BA_ "SigType" SG_ 2566799614 ImplLeftFacingWorkLightData 4;
BA_ "SPN" SG_ 2566799614 ImplRightFacingWorkLightData 2402;
BA_ "SigType" SG_ 2566799614 ImplRightFacingWorkLightData 4;
BA_ "SPN" SG_ 2566799614 ImplementLeftForwardLightData 2598;
BA_ "SigType" SG_ 2566799614 ImplementLeftForwardLightData 4;
BA_ "SPN" SG_ 2566799614 ImplementRightForwardLightData 2407;
BA_ "SigType" SG_ 2566799614 ImplementRightForwardLightData 4;
BA_ "SPN" SG_ 2566799614 ImplementOEMOption1LightData 2396;
BA_ "SigType" SG_ 2566799614 ImplementOEMOption1LightData 4;
BA_ "SPN" SG_ 2566799614 ImplementOEMOption2LightData 2398;
BA_ "SigType" SG_ 2566799614 ImplementOEMOption2LightData 4;
BA_ "SPN" SG_ 2566799614 TractorFrontHighWorkLightData 2356;
BA_ "SigType" SG_ 2566799614 TractorFrontHighWorkLightData 4;
BA_ "SPN" SG_ 2566799614 TractorFrontLowWorkLightData 2354;
BA_ "SigType" SG_ 2566799614 TractorFrontLowWorkLightData 4;
BA_ "SPN" SG_ 2566799614 TractorSideHighWorkLightData 2366;
BA_ "SigType" SG_ 2566799614 TractorSideHighWorkLightData 4;
BA_ "SPN" SG_ 2566799614 TractorSideLowWorkLightData 2364;
BA_ "SigType" SG_ 2566799614 TractorSideLowWorkLightData 4;
BA_ "SPN" SG_ 2566799614 TractorRearHighWorkLightData 2362;
BA_ "SigType" SG_ 2566799614 TractorRearHighWorkLightData 4;
BA_ "SPN" SG_ 2566799614 TractorRearLowWorkLightData 2360;
BA_ "SigType" SG_ 2566799614 TractorRearLowWorkLightData 4;
BA_ "SPN" SG_ 2566799614 TractorUndersideWorkLightData 2358;
BA_ "SigType" SG_ 2566799614 TractorUndersideWorkLightData 4;
BA_ "SPN" SG_ 2566799614 RearFogLightData 2390;
BA_ "SigType" SG_ 2566799614 RearFogLightData 4;
BA_ "SPN" SG_ 2566799614 TractorMarkerLightData 2378;
BA_ "SigType" SG_ 2566799614 TractorMarkerLightData 4;
BA_ "SPN" SG_ 2566799614 ImplementMarkerLightData 2380;
BA_ "SigType" SG_ 2566799614 ImplementMarkerLightData 4;
BA_ "SPN" SG_ 2566799614 TractorClearanceLightData 2382;
BA_ "SigType" SG_ 2566799614 TractorClearanceLightData 4;
BA_ "SPN" SG_ 2566799614 ImplementClearanceLightData 2384;
BA_ "SigType" SG_ 2566799614 ImplementClearanceLightData 4;
BA_ "SPN" SG_ 2566799614 LefttStopLightData 2372;
BA_ "SigType" SG_ 2566799614 LefttStopLightData 4;
BA_ "SPN" SG_ 2566799614 RightStopLightData 2374;
BA_ "SigType" SG_ 2566799614 RightStopLightData 4;
BA_ "SPN" SG_ 2566799614 CentreStopLightData 2376;
BA_ "SigType" SG_ 2566799614 CentreStopLightData 4;
BA_ "SPN" SG_ 2566799614 BackUpLightAndAlarmHornData 2392;
BA_ "SigType" SG_ 2566799614 BackUpLightAndAlarmHornData 4;
BA_ "SPN" SG_ 2566799614 LeftTurnSignalLightData 2368;
BA_ "SigType" SG_ 2566799614 LeftTurnSignalLightData 4;
BA_ "SPN" SG_ 2566799614 RightTurnSignalLightData 2370;
BA_ "SigType" SG_ 2566799614 RightTurnSignalLightData 4;
BA_ "SPN" SG_ 2566799614 RotationBeaconLightData 2386;
BA_ "SigType" SG_ 2566799614 RotationBeaconLightData 4;
BA_ "SPN" SG_ 2566799614 TractorFrontFogLightData 2388;
BA_ "SigType" SG_ 2566799614 TractorFrontFogLightData 4;
BA_ "SPN" SG_ 2566799614 HighBeamHeadLightData 2348;
BA_ "SigType" SG_ 2566799614 HighBeamHeadLightData 4;
BA_ "SPN" SG_ 2566799614 LowBeamHeadLightData 2350;
BA_ "SigType" SG_ 2566799614 LowBeamHeadLightData 4;
BA_ "SPN" SG_ 2566799614 AlternateHeadLightData 2352;
BA_ "SigType" SG_ 2566799614 AlternateHeadLightData 4;
BA_ "SPN" SG_ 2566799614 DaytimeRunningLightData 2404;
BA_ "SigType" SG_ 2566799614 DaytimeRunningLightData 4;
BA_ "SPN" SG_ 2365472766 Valve15FailSaveModeCmd 2345;
BA_ "SigType" SG_ 2365472766 Valve15FailSaveModeCmd 4;
BA_ "SPN" SG_ 2365472766 Valve15StateCmd 2344;
BA_ "SPN" SG_ 2365472766 Valve15PortFlowCmd 2343;
BA_ "SigType" SG_ 2365472766 Valve15PortFlowCmd 1;
BA_ "SPN" SG_ 2365472510 Valve14FailSaveModeCmd 2333;
BA_ "SigType" SG_ 2365472510 Valve14FailSaveModeCmd 4;
BA_ "SPN" SG_ 2365472510 Valve14StateCmd 2332;
BA_ "SPN" SG_ 2365472510 Valve14PortFlowCmd 2331;
BA_ "SigType" SG_ 2365472510 Valve14PortFlowCmd 1;
BA_ "SPN" SG_ 2365472254 Valve13FailSaveModeCmd 2321;
BA_ "SigType" SG_ 2365472254 Valve13FailSaveModeCmd 4;
BA_ "SPN" SG_ 2365472254 Valve13StateCmd 2320;
BA_ "SPN" SG_ 2365472254 Valve13PortFlowCmd 2319;
BA_ "SigType" SG_ 2365472254 Valve13PortFlowCmd 1;
BA_ "SPN" SG_ 2365471998 Valve12FailSaveModeCmd 2309;
BA_ "SigType" SG_ 2365471998 Valve12FailSaveModeCmd 4;
BA_ "SPN" SG_ 2365471998 Valve12StateCmd 2308;
BA_ "SPN" SG_ 2365471998 Valve12PortFlowCmd 2307;
BA_ "SigType" SG_ 2365471998 Valve12PortFlowCmd 1;
BA_ "SPN" SG_ 2365471742 Valve11FailSaveModeCmd 2297;
BA_ "SigType" SG_ 2365471742 Valve11FailSaveModeCmd 4;
BA_ "SPN" SG_ 2365471742 Valve11StateCmd 2296;
BA_ "SPN" SG_ 2365471742 Valve11PortFlowCmd 2295;
BA_ "SigType" SG_ 2365471742 Valve11PortFlowCmd 1;
BA_ "SPN" SG_ 2365471486 Valve10FailSaveModeCmd 2285;
BA_ "SigType" SG_ 2365471486 Valve10FailSaveModeCmd 4;
BA_ "SPN" SG_ 2365471486 Valve10StateCmd 2284;
BA_ "SPN" SG_ 2365471486 Valve10PortFlowCmd 2283;
BA_ "SigType" SG_ 2365471486 Valve10PortFlowCmd 1;
BA_ "SPN" SG_ 2365471230 Valve9FailSaveModeCmd 2273;
BA_ "SigType" SG_ 2365471230 Valve9FailSaveModeCmd 4;
BA_ "SPN" SG_ 2365471230 Valve9StateCmd 2272;
BA_ "SPN" SG_ 2365471230 Valve9PortFlowCmd 2271;
BA_ "SigType" SG_ 2365471230 Valve9PortFlowCmd 1;
BA_ "SPN" SG_ 2365470974 Valve8FailSaveModeCmd 2261;
BA_ "SigType" SG_ 2365470974 Valve8FailSaveModeCmd 4;
BA_ "SPN" SG_ 2365470974 Valve8StateCmd 2260;
BA_ "SPN" SG_ 2365470974 Valve8PortFlowCmd 2259;
BA_ "SigType" SG_ 2365470974 Valve8PortFlowCmd 1;
BA_ "SPN" SG_ 2365470718 Valve7FailSaveModeCmd 1993;
BA_ "SigType" SG_ 2365470718 Valve7FailSaveModeCmd 4;
BA_ "SPN" SG_ 2365470718 Valve7StateCmd 1992;
BA_ "SPN" SG_ 2365470718 Valve7PortFlowCmd 1991;
BA_ "SigType" SG_ 2365470718 Valve7PortFlowCmd 1;
BA_ "SPN" SG_ 2365470462 Valve6FailSaveModeCmd 1981;
BA_ "SigType" SG_ 2365470462 Valve6FailSaveModeCmd 4;
BA_ "SPN" SG_ 2365470462 Valve6StateCmd 1980;
BA_ "SPN" SG_ 2365470462 Valve6PortFlowCmd 1979;
BA_ "SigType" SG_ 2365470462 Valve6PortFlowCmd 1;
BA_ "SPN" SG_ 2365470206 Valve5FailSaveModeCmd 1969;
BA_ "SigType" SG_ 2365470206 Valve5FailSaveModeCmd 4;
BA_ "SPN" SG_ 2365470206 Valve5StateCmd 1968;
BA_ "SPN" SG_ 2365470206 Valve5PortFlowCmd 1967;
BA_ "SigType" SG_ 2365470206 Valve5PortFlowCmd 1;
BA_ "SPN" SG_ 2365469950 Valve4FailSaveModeCmd 1957;
BA_ "SigType" SG_ 2365469950 Valve4FailSaveModeCmd 4;
BA_ "SPN" SG_ 2365469950 Valve4StateCmd 1956;
BA_ "SPN" SG_ 2365469950 Valve4PortFlowCmd 1955;
BA_ "SigType" SG_ 2365469950 Valve4PortFlowCmd 1;
BA_ "SPN" SG_ 2365469694 Valve3FailSaveModeCmd 1945;
BA_ "SigType" SG_ 2365469694 Valve3FailSaveModeCmd 4;
BA_ "SPN" SG_ 2365469694 Valve3StateCmd 1944;
BA_ "SPN" SG_ 2365469694 Valve3PortFlowCmd 1943;
BA_ "SigType" SG_ 2365469694 Valve3PortFlowCmd 1;
BA_ "SPN" SG_ 2365469438 Valve2FailSaveModeCmd 1933;
BA_ "SigType" SG_ 2365469438 Valve2FailSaveModeCmd 4;
BA_ "SPN" SG_ 2365469438 Valve2StateCmd 1932;
BA_ "SPN" SG_ 2365469438 Valve2PortFlowCmd 1931;
BA_ "SigType" SG_ 2365469438 Valve2PortFlowCmd 1;
BA_ "SigType" SG_ 2365469182 Valve1FailSaveModeCmd 4;
BA_ "SPN" SG_ 2365469182 Valve1StateCmd 1920;
BA_ "SPN" SG_ 2365469182 Valve1PortFlowCmd 1919;
BA_ "SigType" SG_ 2365469182 Valve1PortFlowCmd 1;
BA_ "SPN" SG_ 2365468926 Valve0FailSaveModeCmd 1909;
BA_ "SigType" SG_ 2365468926 Valve0FailSaveModeCmd 4;
BA_ "SPN" SG_ 2365468926 Valve0StateCmd 1908;
BA_ "SPN" SG_ 2365468926 Valve0PortFlowCmd 1907;
BA_ "SigType" SG_ 2365468926 Valve0PortFlowCmd 1;
BA_ "SPN" SG_ 2365468670 Valve15LimitStatus 5190;
BA_ "SPN" SG_ 2365468670 Valve15ReturnPortPressure 2342;
BA_ "SigType" SG_ 2365468670 Valve15ReturnPortPressure 1;
BA_ "SPN" SG_ 2365468670 Valve15RetractPortPressure 2341;
BA_ "SigType" SG_ 2365468670 Valve15RetractPortPressure 1;
BA_ "SPN" SG_ 2365468670 Valve15ExtendedPortPressure 2340;
BA_ "SigType" SG_ 2365468670 Valve15ExtendedPortPressure 1;
BA_ "SPN" SG_ 2365468670 Valve15RetractPortMeasuredFlow 2336;
BA_ "SigType" SG_ 2365468670 Valve15RetractPortMeasuredFlow 1;
BA_ "SPN" SG_ 2365468670 Valve15ExtendedPortMeasuredFlow 2335;
BA_ "SigType" SG_ 2365468670 Valve15ExtendedPortMeasuredFlow 1;
BA_ "SPN" SG_ 2365468414 Valve14LimitStatus 5188;
BA_ "SPN" SG_ 2365468414 Valve14ReturnPortPressure 2330;
BA_ "SigType" SG_ 2365468414 Valve14ReturnPortPressure 1;
BA_ "SPN" SG_ 2365468414 Valve14RetractPortPressure 2329;
BA_ "SigType" SG_ 2365468414 Valve14RetractPortPressure 1;
BA_ "SPN" SG_ 2365468414 Valve14ExtendedPortPressure 2328;
BA_ "SigType" SG_ 2365468414 Valve14ExtendedPortPressure 1;
BA_ "SPN" SG_ 2365468414 Valve14RetractPortMeasuredFlow 2324;
BA_ "SigType" SG_ 2365468414 Valve14RetractPortMeasuredFlow 1;
BA_ "SPN" SG_ 2365468414 Valve14ExtendedPortMeasuredFlow 2323;
BA_ "SigType" SG_ 2365468414 Valve14ExtendedPortMeasuredFlow 1;
BA_ "SPN" SG_ 2365468158 Valve13LimitStatus 5186;
BA_ "SPN" SG_ 2365468158 Valve13ReturnPortPressure 2318;
BA_ "SigType" SG_ 2365468158 Valve13ReturnPortPressure 1;
BA_ "SPN" SG_ 2365468158 Valve13RetractPortPressure 2317;
BA_ "SigType" SG_ 2365468158 Valve13RetractPortPressure 1;
BA_ "SPN" SG_ 2365468158 Valve13ExtendedPortPressure 2316;
BA_ "SigType" SG_ 2365468158 Valve13ExtendedPortPressure 1;
BA_ "SPN" SG_ 2365468158 Valve13RetractPortMeasuredFlow 2312;
BA_ "SigType" SG_ 2365468158 Valve13RetractPortMeasuredFlow 1;
BA_ "SPN" SG_ 2365468158 Valve13ExtendedPortMeasuredFlow 2311;
BA_ "SigType" SG_ 2365468158 Valve13ExtendedPortMeasuredFlow 1;
BA_ "SPN" SG_ 2365467902 Valve12LimitStatus 5184;
BA_ "SPN" SG_ 2365467902 Valve12ReturnPortPressure 2306;
BA_ "SigType" SG_ 2365467902 Valve12ReturnPortPressure 1;
BA_ "SPN" SG_ 2365467902 Valve12RetractPortPressure 2305;
BA_ "SigType" SG_ 2365467902 Valve12RetractPortPressure 1;
BA_ "SPN" SG_ 2365467902 Valve12ExtendedPortPressure 2304;
BA_ "SigType" SG_ 2365467902 Valve12ExtendedPortPressure 1;
BA_ "SPN" SG_ 2365467902 Valve12RetractPortMeasuredFlow 2300;
BA_ "SigType" SG_ 2365467902 Valve12RetractPortMeasuredFlow 1;
BA_ "SPN" SG_ 2365467902 Valve12ExtendedPortMeasuredFlow 2299;
BA_ "SigType" SG_ 2365467902 Valve12ExtendedPortMeasuredFlow 1;
BA_ "SPN" SG_ 2365467646 Valve11LimitStatus 5182;
BA_ "SPN" SG_ 2365467646 Valve11ReturnPortPressure 2294;
BA_ "SigType" SG_ 2365467646 Valve11ReturnPortPressure 1;
BA_ "SPN" SG_ 2365467646 Valve11RetractPortPressure 2293;
BA_ "SigType" SG_ 2365467646 Valve11RetractPortPressure 1;
BA_ "SPN" SG_ 2365467646 Valve11ExtendedPortPressure 2292;
BA_ "SigType" SG_ 2365467646 Valve11ExtendedPortPressure 1;
BA_ "SPN" SG_ 2365467646 Valve11RetractPortMeasuredFlow 2288;
BA_ "SigType" SG_ 2365467646 Valve11RetractPortMeasuredFlow 1;
BA_ "SPN" SG_ 2365467646 Valve11ExtendedPortMeasuredFlow 2287;
BA_ "SigType" SG_ 2365467646 Valve11ExtendedPortMeasuredFlow 1;
BA_ "SPN" SG_ 2365467390 Valve10LimitStatus 5180;
BA_ "SPN" SG_ 2365467390 Valve10ReturnPortPressure 2282;
BA_ "SigType" SG_ 2365467390 Valve10ReturnPortPressure 1;
BA_ "SPN" SG_ 2365467390 Valve10RetractPortPressure 2281;
BA_ "SigType" SG_ 2365467390 Valve10RetractPortPressure 1;
BA_ "SPN" SG_ 2365467390 Valve10ExtendedPortPressure 2280;
BA_ "SigType" SG_ 2365467390 Valve10ExtendedPortPressure 1;
BA_ "SPN" SG_ 2365467390 Valve10RetractPortMeasuredFlow 2276;
BA_ "SigType" SG_ 2365467390 Valve10RetractPortMeasuredFlow 1;
BA_ "SPN" SG_ 2365467390 Valve10ExtendedPortMeasuredFlow 2275;
BA_ "SigType" SG_ 2365467390 Valve10ExtendedPortMeasuredFlow 1;
BA_ "SPN" SG_ 2365467134 Valve9LimitStatus 5178;
BA_ "SPN" SG_ 2365467134 Valve9ReturnPortPressure 2270;
BA_ "SigType" SG_ 2365467134 Valve9ReturnPortPressure 1;
BA_ "SPN" SG_ 2365467134 Valve9RetractPortPressure 2269;
BA_ "SigType" SG_ 2365467134 Valve9RetractPortPressure 1;
BA_ "SPN" SG_ 2365467134 Valve9ExtendedPortPressure 2268;
BA_ "SigType" SG_ 2365467134 Valve9ExtendedPortPressure 1;
BA_ "SPN" SG_ 2365467134 Valve9RetractPortMeasuredFlow 2264;
BA_ "SigType" SG_ 2365467134 Valve9RetractPortMeasuredFlow 1;
BA_ "SPN" SG_ 2365467134 Valve9ExtendedPortMeasuredFlow 2263;
BA_ "SigType" SG_ 2365467134 Valve9ExtendedPortMeasuredFlow 1;
BA_ "SPN" SG_ 2365466878 Valve8LimitStatus 5176;
BA_ "SPN" SG_ 2365466878 Valve8ReturnPortPressure 2258;
BA_ "SigType" SG_ 2365466878 Valve8ReturnPortPressure 1;
BA_ "SPN" SG_ 2365466878 Valve8RetractPortPressure 2257;
BA_ "SigType" SG_ 2365466878 Valve8RetractPortPressure 1;
BA_ "SPN" SG_ 2365466878 Valve8ExtendedPortPressure 2256;
BA_ "SigType" SG_ 2365466878 Valve8ExtendedPortPressure 1;
BA_ "SPN" SG_ 2365466878 Valve8RetractPortMeasuredFlow 1996;
BA_ "SigType" SG_ 2365466878 Valve8RetractPortMeasuredFlow 1;
BA_ "SPN" SG_ 2365466878 Valve8ExtendedPortMeasuredFlow 1995;
BA_ "SigType" SG_ 2365466878 Valve8ExtendedPortMeasuredFlow 1;
BA_ "SPN" SG_ 2365466622 Valve7LimitStatus 5174;
BA_ "SPN" SG_ 2365466622 Valve7ReturnPortPressure 1990;
BA_ "SigType" SG_ 2365466622 Valve7ReturnPortPressure 1;
BA_ "SPN" SG_ 2365466622 Valve7RetractPortPressure 1989;
BA_ "SigType" SG_ 2365466622 Valve7RetractPortPressure 1;
BA_ "SPN" SG_ 2365466622 Valve7ExtendedPortPressure 1988;
BA_ "SigType" SG_ 2365466622 Valve7ExtendedPortPressure 1;
BA_ "SPN" SG_ 2365466622 Valve7RetractPortMeasuredFlow 1984;
BA_ "SigType" SG_ 2365466622 Valve7RetractPortMeasuredFlow 1;
BA_ "SPN" SG_ 2365466622 Valve7ExtendedPortMeasuredFlow 1983;
BA_ "SigType" SG_ 2365466622 Valve7ExtendedPortMeasuredFlow 1;
BA_ "SPN" SG_ 2365466366 Valve6LimitStatus 5172;
BA_ "SPN" SG_ 2365466366 Valve6ReturnPortPressure 1978;
BA_ "SigType" SG_ 2365466366 Valve6ReturnPortPressure 1;
BA_ "SPN" SG_ 2365466366 Valve6RetractPortPressure 1977;
BA_ "SigType" SG_ 2365466366 Valve6RetractPortPressure 1;
BA_ "SPN" SG_ 2365466366 Valve6ExtendedPortPressure 1976;
BA_ "SigType" SG_ 2365466366 Valve6ExtendedPortPressure 1;
BA_ "SPN" SG_ 2365466366 Valve6RetractPortMeasuredFlow 1972;
BA_ "SigType" SG_ 2365466366 Valve6RetractPortMeasuredFlow 1;
BA_ "SPN" SG_ 2365466366 Valve6ExtendedPortMeasuredFlow 1971;
BA_ "SigType" SG_ 2365466366 Valve6ExtendedPortMeasuredFlow 1;
BA_ "SPN" SG_ 2365466110 Valve5LimitStatus 5170;
BA_ "SPN" SG_ 2365466110 Valve5ReturnPortPressure 1966;
BA_ "SigType" SG_ 2365466110 Valve5ReturnPortPressure 1;
BA_ "SPN" SG_ 2365466110 Valve5RetractPortPressure 1965;
BA_ "SigType" SG_ 2365466110 Valve5RetractPortPressure 1;
BA_ "SPN" SG_ 2365466110 Valve5ExtendedPortPressure 1964;
BA_ "SigType" SG_ 2365466110 Valve5ExtendedPortPressure 1;
BA_ "SPN" SG_ 2365466110 Valve5RetractPortMeasuredFlow 1960;
BA_ "SigType" SG_ 2365466110 Valve5RetractPortMeasuredFlow 1;
BA_ "SPN" SG_ 2365466110 Valve5ExtendedPortMeasuredFlow 1959;
BA_ "SigType" SG_ 2365466110 Valve5ExtendedPortMeasuredFlow 1;
BA_ "SPN" SG_ 2365465854 Valve4LimitStatus 5168;
BA_ "SPN" SG_ 2365465854 Valve4ReturnPortPressure 1954;
BA_ "SigType" SG_ 2365465854 Valve4ReturnPortPressure 1;
BA_ "SPN" SG_ 2365465854 Valve4RetractPortPressure 1953;
BA_ "SigType" SG_ 2365465854 Valve4RetractPortPressure 1;
BA_ "SPN" SG_ 2365465854 Valve4ExtendedPortPressure 1952;
BA_ "SigType" SG_ 2365465854 Valve4ExtendedPortPressure 1;
BA_ "SPN" SG_ 2365465854 Valve4RetractPortMeasuredFlow 1948;
BA_ "SigType" SG_ 2365465854 Valve4RetractPortMeasuredFlow 1;
BA_ "SPN" SG_ 2365465854 Valve4ExtendedPortMeasuredFlow 1947;
BA_ "SigType" SG_ 2365465854 Valve4ExtendedPortMeasuredFlow 1;
BA_ "SPN" SG_ 2365465598 Valve3LimitStatus 5166;
BA_ "SPN" SG_ 2365465598 Valve3ReturnPortPressure 1942;
BA_ "SigType" SG_ 2365465598 Valve3ReturnPortPressure 1;
BA_ "SPN" SG_ 2365465598 Valve3RetractPortPressure 1941;
BA_ "SigType" SG_ 2365465598 Valve3RetractPortPressure 1;
BA_ "SPN" SG_ 2365465598 Valve3ExtendedPortPressure 1940;
BA_ "SigType" SG_ 2365465598 Valve3ExtendedPortPressure 1;
BA_ "SPN" SG_ 2365465598 Valve3RetractPortMeasuredFlow 1936;
BA_ "SigType" SG_ 2365465598 Valve3RetractPortMeasuredFlow 1;
BA_ "SPN" SG_ 2365465598 Valve3ExtendedPortMeasuredFlow 1935;
BA_ "SigType" SG_ 2365465598 Valve3ExtendedPortMeasuredFlow 1;
BA_ "SPN" SG_ 2365465342 Valve2LimitStatus 5164;
BA_ "SPN" SG_ 2365465342 Valve2ReturnPortPressure 1930;
BA_ "SigType" SG_ 2365465342 Valve2ReturnPortPressure 1;
BA_ "SPN" SG_ 2365465342 Valve2RetractPortPressure 1929;
BA_ "SigType" SG_ 2365465342 Valve2RetractPortPressure 1;
BA_ "SPN" SG_ 2365465342 Valve2ExtendedPortPressure 1928;
BA_ "SigType" SG_ 2365465342 Valve2ExtendedPortPressure 1;
BA_ "SPN" SG_ 2365465342 Valve2RetractPortMeasuredFlow 1924;
BA_ "SigType" SG_ 2365465342 Valve2RetractPortMeasuredFlow 1;
BA_ "SPN" SG_ 2365465342 Valve2ExtendedPortMeasuredFlow 1923;
BA_ "SigType" SG_ 2365465342 Valve2ExtendedPortMeasuredFlow 1;
BA_ "SPN" SG_ 2365465086 Valve1LimitStatus 5162;
BA_ "SPN" SG_ 2365465086 Valve1ReturnPortPressure 1918;
BA_ "SigType" SG_ 2365465086 Valve1ReturnPortPressure 1;
BA_ "SPN" SG_ 2365465086 Valve1RetractPortPressure 1917;
BA_ "SigType" SG_ 2365465086 Valve1RetractPortPressure 1;
BA_ "SPN" SG_ 2365465086 Valve1ExtendedPortPressure 1916;
BA_ "SigType" SG_ 2365465086 Valve1ExtendedPortPressure 1;
BA_ "SPN" SG_ 2365465086 Valve1RetractPortMeasuredFlow 1912;
BA_ "SigType" SG_ 2365465086 Valve1RetractPortMeasuredFlow 1;
BA_ "SPN" SG_ 2365465086 Valve1ExtendedPortMeasuredFlow 1911;
BA_ "SigType" SG_ 2365465086 Valve1ExtendedPortMeasuredFlow 1;
BA_ "SPN" SG_ 2365464830 Valve0LimitStatus 5160;
BA_ "SPN" SG_ 2365464830 Valve0ReturnPortPressure 1906;
BA_ "SigType" SG_ 2365464830 Valve0ReturnPortPressure 1;
BA_ "SPN" SG_ 2365464830 Valve0RetractPortPressure 1905;
BA_ "SigType" SG_ 2365464830 Valve0RetractPortPressure 1;
BA_ "SPN" SG_ 2365464830 Valve0ExtendedPortPressure 1904;
BA_ "SigType" SG_ 2365464830 Valve0ExtendedPortPressure 1;
BA_ "SigType" SG_ 2365464830 Valve0RetractPortMeasuredFlow 1;
BA_ "SPN" SG_ 2365464830 Valve0RetractPortMeasuredFlow 1900;
BA_ "SigType" SG_ 2365464830 Valve0ExtendedPortMeasuredFlow 1;
BA_ "SPN" SG_ 2365464830 Valve0ExtendedPortMeasuredFlow 1899;
BA_ "SPN" SG_ 2365464574 AuxValve15ExitReasonCode 5815;
BA_ "SPN" SG_ 2365464574 Valve15LimitStatus 5191;
BA_ "SPN" SG_ 2365464574 Valve15FailSafeMode 2346;
BA_ "SigType" SG_ 2365464574 Valve15FailSafeMode 4;
BA_ "SPN" SG_ 2365464574 Valve15ValveState 2339;
BA_ "SPN" SG_ 2365464574 Valve15RetractPortEstimatedFlow 2338;
BA_ "SigType" SG_ 2365464574 Valve15RetractPortEstimatedFlow 1;
BA_ "SPN" SG_ 2365464574 Valve15ExtendedPortEstimatedFlow 2337;
BA_ "SigType" SG_ 2365464574 Valve15ExtendedPortEstimatedFlow 1;
BA_ "SPN" SG_ 2365464318 Valve14LimitStatus 5189;
BA_ "SPN" SG_ 2365464318 Valve14FailSafeMode 2334;
BA_ "SigType" SG_ 2365464318 Valve14FailSafeMode 4;
BA_ "SPN" SG_ 2365464318 Valve14ValveState 2327;
BA_ "SPN" SG_ 2365464318 Valve14RetractPortEstimatedFlow 2326;
BA_ "SigType" SG_ 2365464318 Valve14RetractPortEstimatedFlow 1;
BA_ "SPN" SG_ 2365464318 Valve14ExtendedPortEstimatedFlow 2325;
BA_ "SigType" SG_ 2365464318 Valve14ExtendedPortEstimatedFlow 1;
BA_ "SPN" SG_ 2365464062 Valve13LimitStatus 5187;
BA_ "SPN" SG_ 2365464062 Valve13FailSafeMode 2322;
BA_ "SigType" SG_ 2365464062 Valve13FailSafeMode 4;
BA_ "SPN" SG_ 2365464062 Valve13ValveState 2315;
BA_ "SPN" SG_ 2365464062 Valve13RetractPortEstimatedFlow 2314;
BA_ "SigType" SG_ 2365464062 Valve13RetractPortEstimatedFlow 1;
BA_ "SPN" SG_ 2365464062 Valve13ExtendedPortEstimatedFlow 2313;
BA_ "SigType" SG_ 2365464062 Valve13ExtendedPortEstimatedFlow 1;
BA_ "SPN" SG_ 2365463806 Valve12LimitStatus 5185;
BA_ "SPN" SG_ 2365463806 Valve12FailSafeMode 2310;
BA_ "SigType" SG_ 2365463806 Valve12FailSafeMode 4;
BA_ "SPN" SG_ 2365463806 Valve12ValveState 2303;
BA_ "SPN" SG_ 2365463806 Valve12RetractPortEstimatedFlow 2302;
BA_ "SigType" SG_ 2365463806 Valve12RetractPortEstimatedFlow 1;
BA_ "SPN" SG_ 2365463806 Valve12ExtendedPortEstimatedFlow 2301;
BA_ "SigType" SG_ 2365463806 Valve12ExtendedPortEstimatedFlow 1;
BA_ "SPN" SG_ 2365463550 Valve11LimitStatus 5183;
BA_ "SPN" SG_ 2365463550 Valve11FailSafeMode 2298;
BA_ "SigType" SG_ 2365463550 Valve11FailSafeMode 4;
BA_ "SPN" SG_ 2365463550 Valve11ValveState 2291;
BA_ "SPN" SG_ 2365463550 Valve11RetractPortEstimatedFlow 2290;
BA_ "SigType" SG_ 2365463550 Valve11RetractPortEstimatedFlow 1;
BA_ "SPN" SG_ 2365463550 Valve11ExtendedPortEstimatedFlow 2289;
BA_ "SigType" SG_ 2365463550 Valve11ExtendedPortEstimatedFlow 1;
BA_ "SPN" SG_ 2365463294 Valve10LimitStatus 5181;
BA_ "SPN" SG_ 2365463294 Valve10FailSafeMode 2286;
BA_ "SigType" SG_ 2365463294 Valve10FailSafeMode 4;
BA_ "SPN" SG_ 2365463294 Valve10ValveState 2279;
BA_ "SPN" SG_ 2365463294 Valve10RetractPortEstimatedFlow 2278;
BA_ "SigType" SG_ 2365463294 Valve10RetractPortEstimatedFlow 1;
BA_ "SPN" SG_ 2365463294 Valve10ExtendedPortEstimatedFlow 2277;
BA_ "SigType" SG_ 2365463294 Valve10ExtendedPortEstimatedFlow 1;
BA_ "SPN" SG_ 2365463038 Valve9LimitStatus 5179;
BA_ "SPN" SG_ 2365463038 Valve9FailSafeMode 2274;
BA_ "SigType" SG_ 2365463038 Valve9FailSafeMode 4;
BA_ "SPN" SG_ 2365463038 Valve9ValveState 2267;
BA_ "SPN" SG_ 2365463038 Valve9RetractPortEstimatedFlow 2266;
BA_ "SigType" SG_ 2365463038 Valve9RetractPortEstimatedFlow 1;
BA_ "SPN" SG_ 2365463038 Valve9ExtendedPortEstimatedFlow 2265;
BA_ "SigType" SG_ 2365463038 Valve9ExtendedPortEstimatedFlow 1;
BA_ "SPN" SG_ 2365462782 Valve8LimitStatus 5177;
BA_ "SPN" SG_ 2365462782 Valve8FailSafeMode 2262;
BA_ "SigType" SG_ 2365462782 Valve8FailSafeMode 4;
BA_ "SPN" SG_ 2365462782 Valve8ValveState 1999;
BA_ "SPN" SG_ 2365462782 Valve8RetractPortEstimatedFlow 1998;
BA_ "SigType" SG_ 2365462782 Valve8RetractPortEstimatedFlow 1;
BA_ "SPN" SG_ 2365462782 Valve8ExtendedPortEstimatedFlow 1997;
BA_ "SigType" SG_ 2365462782 Valve8ExtendedPortEstimatedFlow 1;
BA_ "SPN" SG_ 2365462526 Valve7LimitStatus 5175;
BA_ "SPN" SG_ 2365462526 Valve7FailSafeMode 1994;
BA_ "SigType" SG_ 2365462526 Valve7FailSafeMode 4;
BA_ "SPN" SG_ 2365462526 Valve7ValveState 1987;
BA_ "SPN" SG_ 2365462526 Valve7RetractPortEstimatedFlow 1986;
BA_ "SigType" SG_ 2365462526 Valve7RetractPortEstimatedFlow 1;
BA_ "SPN" SG_ 2365462526 Valve7ExtendedPortEstimatedFlow 1985;
BA_ "SigType" SG_ 2365462526 Valve7ExtendedPortEstimatedFlow 1;
BA_ "SPN" SG_ 2365462270 Valve6LimitStatus 5173;
BA_ "SPN" SG_ 2365462270 Valve6FailSafeMode 1982;
BA_ "SigType" SG_ 2365462270 Valve6FailSafeMode 4;
BA_ "SPN" SG_ 2365462270 Valve6ValveState 1975;
BA_ "SPN" SG_ 2365462270 Valve6RetractPortEstimatedFlow 1974;
BA_ "SigType" SG_ 2365462270 Valve6RetractPortEstimatedFlow 1;
BA_ "SPN" SG_ 2365462270 Valve6ExtendedPortEstimatedFlow 1973;
BA_ "SigType" SG_ 2365462270 Valve6ExtendedPortEstimatedFlow 1;
BA_ "SPN" SG_ 2365462014 Valve5LimitStatus 5171;
BA_ "SPN" SG_ 2365462014 Valve5FailSafeMode 1970;
BA_ "SigType" SG_ 2365462014 Valve5FailSafeMode 4;
BA_ "SPN" SG_ 2365462014 Valve5ValveState 1963;
BA_ "SPN" SG_ 2365462014 Valve5RetractPortEstimatedFlow 1962;
BA_ "SigType" SG_ 2365462014 Valve5RetractPortEstimatedFlow 1;
BA_ "SPN" SG_ 2365462014 Valve5ExtendedPortEstimatedFlow 1961;
BA_ "SigType" SG_ 2365462014 Valve5ExtendedPortEstimatedFlow 1;
BA_ "SPN" SG_ 2365461758 Valve4LimitStatus 5169;
BA_ "SPN" SG_ 2365461758 Valve4FailSafeMode 1958;
BA_ "SigType" SG_ 2365461758 Valve4FailSafeMode 4;
BA_ "SPN" SG_ 2365461758 Valve4ValveState 1951;
BA_ "SPN" SG_ 2365461758 Valve4RetractPortEstimatedFlow 1950;
BA_ "SigType" SG_ 2365461758 Valve4RetractPortEstimatedFlow 1;
BA_ "SPN" SG_ 2365461758 Valve4ExtendedPortEstimatedFlow 1949;
BA_ "SigType" SG_ 2365461758 Valve4ExtendedPortEstimatedFlow 1;
BA_ "SPN" SG_ 2365461502 Valve3LimitStatus 5167;
BA_ "SPN" SG_ 2365461502 Valve3FailSafeMode 1946;
BA_ "SigType" SG_ 2365461502 Valve3FailSafeMode 4;
BA_ "SPN" SG_ 2365461502 Valve3ValveState 1939;
BA_ "SPN" SG_ 2365461502 Valve3RetractPortEstimatedFlow 1938;
BA_ "SigType" SG_ 2365461502 Valve3RetractPortEstimatedFlow 1;
BA_ "SPN" SG_ 2365461502 Valve3ExtendedPortEstimatedFlow 1937;
BA_ "SigType" SG_ 2365461502 Valve3ExtendedPortEstimatedFlow 1;
BA_ "SPN" SG_ 2365461246 Valve2LimitStatus 5165;
BA_ "SPN" SG_ 2365461246 Valve2FailSafeMode 1934;
BA_ "SigType" SG_ 2365461246 Valve2FailSafeMode 4;
BA_ "SPN" SG_ 2365461246 Valve2ValveState 1927;
BA_ "SPN" SG_ 2365461246 Valve2RetractPortEstimatedFlow 1926;
BA_ "SigType" SG_ 2365461246 Valve2RetractPortEstimatedFlow 1;
BA_ "SPN" SG_ 2365461246 Valve2ExtendedPortEstimatedFlow 1925;
BA_ "SigType" SG_ 2365461246 Valve2ExtendedPortEstimatedFlow 1;
BA_ "SPN" SG_ 2365460990 Valve1LimitStatus 5163;
BA_ "SPN" SG_ 2365460990 Valve1FailSafeMode 1922;
BA_ "SigType" SG_ 2365460990 Valve1FailSafeMode 4;
BA_ "SPN" SG_ 2365460990 Valve1ValveState 1915;
BA_ "SPN" SG_ 2365460990 Valve1RetractPortEstimatedFlow 1914;
BA_ "SigType" SG_ 2365460990 Valve1RetractPortEstimatedFlow 1;
BA_ "SPN" SG_ 2365460990 Valve1ExtendedPortEstimatedFlow 1913;
BA_ "SigType" SG_ 2365460990 Valve1ExtendedPortEstimatedFlow 1;
BA_ "SPN" SG_ 2365460734 AuxValveNum0ExitReasonCode 5800;
BA_ "SPN" SG_ 2365460734 Valve0LimitStatus 5161;
BA_ "SPN" SG_ 2365460734 Valve0FailSafeMode 1910;
BA_ "SigType" SG_ 2365460734 Valve0FailSafeMode 4;
BA_ "SPN" SG_ 2365460734 Valve0ValveState 1903;
BA_ "SPN" SG_ 2365460734 Valve0RetractPortEstimatedFlow 1902;
BA_ "SigType" SG_ 2365460734 Valve0RetractPortEstimatedFlow 1;
BA_ "SigType" SG_ 2365460734 Valve0ExtendedPortEstimatedFlow 1;
BA_ "SPN" SG_ 2365460734 Valve0ExtendedPortEstimatedFlow 1901;
BA_ "SigType" SG_ 2566787070 TemperatureUnits 4;
BA_ "SPN" SG_ 2566787070 TemperatureUnits 5194;
BA_ "SigType" SG_ 2566787070 PressureUnits 4;
BA_ "SPN" SG_ 2566787070 PressureUnits 5195;
BA_ "SigType" SG_ 2566787070 ForceUnits 4;
BA_ "SPN" SG_ 2566787070 ForceUnits 5196;
BA_ "SigType" SG_ 2566787070 UnitsSystem 4;
BA_ "SPN" SG_ 2566787070 UnitsSystem 5197;
BA_ "SPN" SG_ 2566787070 DistanceUnitCmd 2414;
BA_ "SigType" SG_ 2566787070 DistanceUnitCmd 4;
BA_ "SPN" SG_ 2566787070 AreaUnitCmd 2415;
BA_ "SigType" SG_ 2566787070 AreaUnitCmd 4;
BA_ "SPN" SG_ 2566787070 VolumeUnitCmd 2416;
BA_ "SigType" SG_ 2566787070 VolumeUnitCmd 4;
BA_ "SPN" SG_ 2566787070 MassUnitCmd 2417;
BA_ "SigType" SG_ 2566787070 MassUnitCmd 4;
BA_ "SPN" SG_ 2566787070 DateFormatCmd 2412;
BA_ "SigType" SG_ 2566787070 DateFormatCmd 1;
BA_ "SPN" SG_ 2566787070 DecimalSymbolCmd 2411;
BA_ "SigType" SG_ 2566787070 DecimalSymbolCmd 4;
BA_ "SPN" SG_ 2566787070 TimeFormatCmd 2413;
BA_ "SigType" SG_ 2566787070 TimeFormatCmd 4;
BA_ "SPN" SG_ 2566787070 LanguageCodeCmd 2410;
BA_ "SigType" SG_ 2566787070 LanguageCodeCmd 3;
BA_ "SigType" SG_ 2566786814 ActualRepetitionRate 1;
BA_ "SPN" SG_ 2566786814 ActualRepetitionRate 5198;
BA_ "SigType" SG_ 2566786814 PGN 6;
BA_ "SigType" SG_ 2633895422 NumberOfMembers 3;
BA_ "SPN" SG_ 2633895166 ArbitraryAddressCapable 2844;
BA_ "SPN" SG_ 2633895166 ECUInstance 2840;
BA_ "SPN" SG_ 2633895166 Function 2841;
BA_ "SPN" SG_ 2633895166 FunctionInstance 2839;
BA_ "SPN" SG_ 2633895166 IdentityNumber 2837;
BA_ "SPN" SG_ 2633895166 IndustryGroup 2846;
BA_ "SigType" SG_ 2633895166 ManufacturerCode 1;
BA_ "SPN" SG_ 2633895166 ManufacturerCode 2838;
BA_ "SPN" SG_ 2633895166 VehicleSystemInstance 2843;
BA_ "SigType" SG_ 2365459454 TractorControlCmdValue2 1;
BA_ "SigType" SG_ 2365459454 TractorControlCmdValue1 1;
BA_ "SPN" SG_ 2365459454 TractorControlModeCmd1 5204;
BA_ "SigType" SG_ 2365459198 TractorControlValueResponse2 1;
BA_ "SigType" SG_ 2365459198 TractorControlValueResponse1 1;
BA_ "SPN" SG_ 2365459198 TractorControlModeResponse1 5213;
BA_ "SPN" SG_ 2365459198 TractorControlLimitStatus1 5227;
VAL_ 2365475326 GroundBasedMachineDirection 3 "NotAvailable" 2 "ErrorIndication" 1 "Forward" 0 "Reverse" ;
VAL_ 2365475070 OperatorDirectionReversed 0 "Not reversed" 1 "Reversed" 2 "Error" 3 "Not available" ;
VAL_ 2365475070 StartStopState 3 "Don't Care" 2 "Reserved" 1 "Start or enable implement work" 0 "Stop or disable implement work" ;
VAL_ 2365475070 KeySwitchState 3 "NotAvailable" 2 "ErrorIndication" 1 "KeySwitchNotOff" 0 "KeySwitchOff" ;
VAL_ 2365475070 WheelBasedMachineDirection 3 "NotAvailable" 2 "ErrorIndicator" 1 "Forward" 0 "Reverse" ;
VAL_ 2566801406 ImplementInWorkState 3 "Not available" 2 "Error indication" 1 "Implement is in work state" 0 "Implement is not in work state" ;
VAL_ 2566801406 ImplementTransportState 3 "Not available" 2 "Error indication" 1 "Implement may be transported" 0 "Implement may not be transported" ;
VAL_ 2566801406 ImplementParkState 3 "Not available" 2 "Error indication" 1 "Implement may be disconnected" 0 "Implement may not be disconnected" ;
VAL_ 2566801406 ImplementReadyToWorkState 3 "Not available" 2 "Error indication" 1 "Implement is ready for field work" 0 "Implement is not ready for field work" ;
VAL_ 2566801406 MaintainECUPower 3 "DoNotCare" 1 "RequireForTwoMoreSecOfECU_PWR" 0 "NoFurtherRequireForECU_PWR" ;
VAL_ 2566801406 MaintainActuatorPower 3 "DoNotCare" 1 "RequireForTwoMoreSecOfPWR" 0 "NoFurtherRequirementForPWR" ;
VAL_ 2365474558 FrontHitchExitReasonCode 0 "No reason/all clear " 1 "Operator presence not detected" 2 "Implement released control of function" 3 "Operator override of function " 4 "Operator control not in valid position " 5 "Remote command timeout " 6 "Remote command out of range/invalid " 7 "Function not calibrated " 8 "Operator control fault " 9 "Function fault " 20 "Hydraulic oil level too low " 21 "Hitch locked out " 62 "Error" 63 "Not available (parameter not supported) " ;
VAL_ 2365474558 FrontHitchInWorkIndication 3 "NotAvailable" 2 "ErrorIndication" 1 "HitchPositionIsInWorl" 0 "HitchPositionIsOutOfWork" ;
VAL_ 2365474558 FrontHitchPositionLimitStatus 0 "Not limited" 1 "Operator Limited" 2 "Limited High" 3 "Limited Low" 4 "Reserved" 5 "Reserver" 6 "Non-recoverable Fault" 7 "Not available" ;
VAL_ 2365474302 RearHitchExitReasonCode 0 "No reason/all clear " 1 "Operator presence not detected" 2 "Implement released control of function" 3 "Operator override of function " 4 "Operator control not in valid position " 5 "Remote command timeout " 6 "Remote command out of range/invalid " 7 "Function not calibrated " 8 "Operator control fault " 9 "Function fault " 20 "Hydraulic oil level too low " 21 "Hitch locked out " 62 "Error" 63 "Not available (parameter not supported) " ;
VAL_ 2365474302 RearHitchInWorkIndication 3 "NotAvailable" 2 "ErrorIndication" 1 "HitchPositionIsInWork" 0 "HitchPositionIsOutOfWork" ;
VAL_ 2365474302 RearHitchPositionLimitStatus 0 "Not limited" 1 "Operator Limited" 2 "Limited High" 3 "Limited Low" 4 "Reserved" 5 "Reserver" 6 "Non-recoverable Fault" 7 "Not available" ;
VAL_ 2365474046 FrontPTOExitReasonCode 0 "No reason/all clear" 1 "Operator presence not detected" 2 "Implement released control of function" 3 "Operator override of function " 4 "Operator control not in valid position " 5 "Remote command timeout " 6 "Remote command out of range/invalid " 7 "Function not calibrated " 8 "Operator control fault " 9 "Function fault " 20 "Invalid PTO gear" 62 "Error " 63 "Not available (parameter not supported)" ;
VAL_ 2365474046 FrontPTOModeRqStatus 0 "External Request accepted" 1 "Control Override" 2 "Error" 3 "Not available" ;
VAL_ 2365474046 FrontPTOEconomyModeRqStatus 0 "External Request accepted" 1 "Control Override" 2 "Error" 3 "Not available" ;
VAL_ 2365474046 FrontPTOShaftSpeedLimitStatus 0 "Not limited" 1 "Operator Limited" 2 "Limited High" 3 "Limited Low" 4 "Reserved" 5 "Reserver" 6 "Non-recoverable Fault" 7 "Not available" ;
VAL_ 2365474046 FrontPTOEngagement 3 "NotAvailable" 2 "ErrorIndication" 1 "PTOEngaged" 0 "PTODisengaged" ;
VAL_ 2365474046 FrontPTOMode 3 "NotAvailable" 2 "ErrorIndication" 1 "PTOModeIs1000" 0 "PTOModeIs540" ;
VAL_ 2365474046 FrontPTOEconomyMode 3 "NotAvailable" 2 "ErrorIndication" 1 "PTOEconomyModeIsEngaged" 0 "PTOEconomyModeIsDisengaged" ;
VAL_ 2365474046 FrontPTOEngagementRqStatus 0 "External Request accepted" 1 "Control Override" 2 "Error" 3 "Not available" ;
VAL_ 2365473790 RearPTOExitReasonCode 0 "No reason/all clear" 1 "Operator presence not detected" 2 "Implement released control of function" 3 "Operator override of function " 4 "Operator control not in valid position " 5 "Remote command timeout " 6 "Remote command out of range/invalid " 7 "Function not calibrated " 8 "Operator control fault " 9 "Function fault " 20 "Invalid PTO gear" 62 "Error " 63 "Not available (parameter not supported)" ;
VAL_ 2365473790 RearPTOModeRqStatus 0 "External Request accepted" 1 "Control Override" 2 "Error" 3 "Not available" ;
VAL_ 2365473790 RearPTOEconomyModeRqStatus 0 "External Request accepted" 1 "Control Override" 2 "Error" 3 "Not available" ;
VAL_ 2365473790 RearPTOShaftSpeedLimitStatus 0 "Not limited" 1 "Operator Limited" 2 "Limited High" 3 "Limited Low" 4 "Reserved" 5 "Reserver" 6 "Non-recoverable Fault" 7 "Not available" ;
VAL_ 2365473790 RearPTOEngagement 3 "NotAvailable" 2 "ErrorIndication" 1 "PTOEngaged" 0 "PTODisengaged" ;
VAL_ 2365473790 RearPTOMode 3 "NotAvailable" 2 "ErrorIndication" 1 "PTOModeIs1000" 0 "PTOModeIs540" ;
VAL_ 2365473790 RearPTOEconomyMode 3 "NotAvailabel" 2 "ErrorIndication" 1 "PTOEconomyModeIsEngaged" 0 "PTOEconomyModeIsDisengaged" ;
VAL_ 2365473790 RearPTOEngagementRqStatus 0 "External Request accepted" 1 "Control Override" 2 "Error" 3 "Not available" ;
VAL_ 2365473534 FrontPTOModeCmd 3 "DoNotCare" 1 "Select1000rpmMode" 0 "Select540rpmMode" ;
VAL_ 2365473534 RearPTOModeCmd 3 "DoNotCare" 1 "Select1000rpmMode" 0 "Select540rpmMode" ;
VAL_ 2365473534 FrontPTOEconomyModeCmd 3 "DoNotCare" 1 "EngagePTOEconomyMode" 0 "DisengagePTOEconomyMode" ;
VAL_ 2365473534 RearPTOEconomyModeCmd 3 "DoNotCare" 1 "EngagePTOEconomyMode" 0 "DisengagePTOEconomyMode" ;
VAL_ 2365473534 FrontPTOEngagementCmd 3 "DoNotCare" 1 "EngagePTO" 0 "DisengagePTO" ;
VAL_ 2365473534 RearPTOEngagementCmd 3 "DoNotCare" 1 "EngangePTO" 0 "DisengagePTO" ;
VAL_ 2365473278 ImplementRearWorkLightCmd 0 "Deactivate" 1 "Activate" 2 "Reserved" 3 "Dont Care" ;
VAL_ 2365473278 ImplementLeftFacingWorkLightCmd 3 "Dont Care" 1 "Activate" 0 "Deactivate" 2 "Reserved" ;
VAL_ 2365473278 ImplementRightFacingWorkLightCmd 0 "Deactivate" 1 "Activate" 2 "Reserved" 3 "Dont Care" ;
VAL_ 2365473278 LightingDataRequestCmd 3 "DoNotCare" 1 "Acitvate" 0 "Deactivate" ;
VAL_ 2365473278 ImplementLeftForwardLightCmd 3 "DoNotCare" 1 "Acitvate" 0 "Deactivate" ;
VAL_ 2365473278 ImplementRightForwardLightCmd 3 "DoNotCare" 1 "Acitvate" 0 "Deactivate" ;
VAL_ 2365473278 ImplementOEMOption1LightCmd 0 "Deactivate" 1 "Activate" 2 "Reserved" 3 "Dont Care" ;
VAL_ 2365473278 ImplementOEMOption2LightCmd 0 "Deactivate" 1 "Activate" 2 "Reserved" 3 "Dont Care" ;
VAL_ 2365473278 TractorFrontHighWorkLightCmd 3 "DoNotCare" 1 "Acitvate" 0 "Deactivate" ;
VAL_ 2365473278 TractorFrontLowWorkLightCmd 3 "DoNotCare" 1 "Acitvate" 0 "Deactivate" ;
VAL_ 2365473278 TractorSideHighWorkLightCmd 3 "DoNotCare" 1 "Acitvate" 0 "Deactivate" ;
VAL_ 2365473278 TractorSideLowWorkLightCmd 3 "DoNotCare" 1 "Acitvate" 0 "Deactivate" ;
VAL_ 2365473278 TractorRearHighWorkLightCmd 3 "DoNotCare" 1 "Acitvate" 0 "Deactivate" ;
VAL_ 2365473278 TractorRearLowWorkLightCmd 3 "DoNotCare" 1 "Acitvate" 0 "Deactivate" ;
VAL_ 2365473278 TractorUndersideWorkLightCmd 3 "DoNotCare" 1 "Acitvate" 0 "Deactivate" ;
VAL_ 2365473278 RearFogLightCmd 3 "Dont Care" 1 "Activate" 0 "Deactivate" 2 "Reserved" ;
VAL_ 2365473278 TractorMarkerLightCmd 3 "Dont Care" 1 "Activate" 0 "Deactivate" 2 "Reserved" ;
VAL_ 2365473278 ImplementMarkerLightCmd 3 "Dont Care" 1 "Activate" 0 "Deactivate" 2 "Reserved" ;
VAL_ 2365473278 TractorClearanceLightCmd 3 "Dont Care" 1 "Activate" 0 "Deactivate" 2 "Reserved" ;
VAL_ 2365473278 ImplementClearanceLightCmd 3 "Dont Care" 1 "Activate" 0 "Deactivate" 2 "Reserved" ;
VAL_ 2365473278 LeftStopLightCmd 3 "Dont Care" 1 "Activate" 0 "Deactivate" 2 "Reserved" ;
VAL_ 2365473278 RightStopLightCmd 0 "Deactivate" 1 "Activate" 2 "Reserved" 3 "Dont Care" ;
VAL_ 2365473278 CentreStopLightCmd 3 "DoNotCare" 1 "Acitvate" 0 "Deactivate" ;
VAL_ 2365473278 BackUpLightAndAlarmHornCmd 3 "Dont Care" 1 "Activate" 0 "Deactivate" 2 "Reserved" ;
VAL_ 2365473278 LeftTurnSignalLightCmd 3 "DoNotCare" 1 "Activate" 0 "Deactivate" ;
VAL_ 2365473278 RightTurnSignalLightCmd 3 "DoNotCare" 1 "Activate" 0 "Deactivate" ;
VAL_ 2365473278 RotatingBeaconLightCmd 0 "Deactivate" 1 "Activate" 2 "Reserved" 3 "Dont Care" ;
VAL_ 2365473278 TractorFrontFogLightCmd 3 "DoNotCare" 1 "Activate" 0 "Deactivate" ;
VAL_ 2365473278 HighBeamHeadLightCmd 3 "Dont Care" 1 "Activate" 0 "Deactivate" 2 "Reserved" ;
VAL_ 2365473278 LowBeamHeadLightCmd 3 "Dont Care" 1 "Activate" 0 "Deactivate" 2 "Reserved" ;
VAL_ 2365473278 AlternateHeadLightCmd 3 "DoNotCare" 1 "Activate" 0 "Deactivate" ;
VAL_ 2365473278 DaytimeRunningLightCmd 3 "DoNotCare" 1 "Activate" 0 "Deactivate" ;
VAL_ 2566799614 ImplementRearWorkLightData 3 "NotAvailable" 2 "FaultDetected" 1 "Activated" 0 "Deactivated" ;
VAL_ 2566799614 ImplLeftFacingWorkLightData 3 "NotAvailable" 2 "FaultDetected" 1 "Activated" 0 "Deactivated" ;
VAL_ 2566799614 ImplRightFacingWorkLightData 3 "NotAvailable" 2 "FaultDetected" 1 "Activated" 0 "Deactivated" ;
VAL_ 2566799614 ImplementLeftForwardLightData 3 "NotAvailable" 2 "FaultDetected" 1 "Activated" 0 "Deactivated" ;
VAL_ 2566799614 ImplementRightForwardLightData 3 "NotAvailable" 2 "FaultDetected" 1 "Activated" 0 "Deactivated" ;
VAL_ 2566799614 ImplementOEMOption1LightData 3 "NotAvailable" 2 "FaultDetected" 1 "Activated" 0 "Deactivated" ;
VAL_ 2566799614 ImplementOEMOption2LightData 3 "NotAvailable" 2 "FaultDetected" 1 "Activated" 0 "Deactivated" ;
VAL_ 2566799614 TractorFrontHighWorkLightData 3 "NotAvailable" 2 "FaultDetected" 1 "Activated" 0 "Deactivated" ;
VAL_ 2566799614 TractorFrontLowWorkLightData 3 "NotAvailable" 2 "FaultDetected" 1 "Activated" 0 "Deactivated" ;
VAL_ 2566799614 TractorSideHighWorkLightData 3 "NotAvailable" 2 "FaultDetected" 1 "Activated" 0 "Deactivated" ;
VAL_ 2566799614 TractorSideLowWorkLightData 3 "NotAvailable" 2 "FaultDetected" 1 "Activated" 0 "Deactivated" ;
VAL_ 2566799614 TractorRearHighWorkLightData 3 "NotAvailable" 2 "FaultDetected" 1 "Activated" 0 "Deactivated" ;
VAL_ 2566799614 TractorRearLowWorkLightData 3 "NotAvailable" 2 "FaultDetected" 1 "Activated" 0 "Deactivated" ;
VAL_ 2566799614 TractorUndersideWorkLightData 3 "NotAvailable" 2 "FaultDetected" 1 "Activated" 0 "Deactivated" ;
VAL_ 2566799614 RearFogLightData 3 "NotAvailable" 2 "FaultDetected" 1 "Activated" 0 "Deactivated" ;
VAL_ 2566799614 TractorMarkerLightData 3 "NotAvailable" 2 "FaultDetected" 1 "Activated" 0 "Deactivated" ;
VAL_ 2566799614 ImplementMarkerLightData 3 "NotAvailable" 2 "FaultDetected" 1 "Activated" 0 "Deactivated" ;
VAL_ 2566799614 TractorClearanceLightData 3 "NotAvailable" 2 "FaultDetected" 1 "Activated" 0 "Deactivated" ;
VAL_ 2566799614 ImplementClearanceLightData 3 "NotAvailable" 2 "FaultDetected" 1 "Activated" 0 "Deactivated" ;
VAL_ 2566799614 LefttStopLightData 3 "NotAvailable" 2 "FaultDetected" 1 "Activated" 0 "Deactivated" ;
VAL_ 2566799614 RightStopLightData 3 "NotAvailable" 2 "FaultDetected" 1 "Activated" 0 "Deactivated" ;
VAL_ 2566799614 CentreStopLightData 3 "NotAvailable" 2 "FaultDetected" 1 "Activated" 0 "Deactivated" ;
VAL_ 2566799614 BackUpLightAndAlarmHornData 3 "NotAvailable" 2 "FaultDetected" 1 "Activated" 0 "Deactivated" ;
VAL_ 2566799614 LeftTurnSignalLightData 3 "NotAvailable" 2 "FaultDetected" 1 "Activated" 0 "Deactivated" ;
VAL_ 2566799614 RightTurnSignalLightData 3 "NotAvailable" 2 "FaultDetected" 1 "Activated" 0 "Deactivated" ;
VAL_ 2566799614 RotationBeaconLightData 3 "NotAvailable" 2 "FaultDetected" 1 "Activated" 0 "Deactivated" ;
VAL_ 2566799614 TractorFrontFogLightData 3 "NotAvailable" 2 "FaultDetected" 1 "Activated" 0 "Deactivated" ;
VAL_ 2566799614 HighBeamHeadLightData 3 "Not Available" 2 "Fault Detected" 1 "Activated" 0 "Deactivated" ;
VAL_ 2566799614 LowBeamHeadLightData 3 "Not Available" 2 "Fault Detected" 1 "Activated" 0 "Deactivated" ;
VAL_ 2566799614 AlternateHeadLightData 3 "NotAvailable" 2 "FaultDetected" 1 "Activated" 0 "Deactivated" ;
VAL_ 2566799614 DaytimeRunningLightData 3 "NotAvailable" 2 "FaultDetected" 1 "Activated" 0 "Deactivated" ;
VAL_ 2365472766 Valve15FailSaveModeCmd 3 "DoNotCare" 1 "Float" 0 "Block" ;
VAL_ 2365472766 Valve15StateCmd 15 "Reserved" 3 "Float" 2 "Retract" 1 "Extend" 0 "Block" ;
VAL_ 2365472510 Valve14FailSaveModeCmd 3 "DoNotCare" 1 "Float" 0 "Block" ;
VAL_ 2365472510 Valve14StateCmd 15 "Reserved" 3 "Float" 2 "Retract" 1 "Extend" 0 "Block" ;
VAL_ 2365472254 Valve13FailSaveModeCmd 3 "DoNotCare" 1 "Float" 0 "Block" ;
VAL_ 2365472254 Valve13StateCmd 15 "Reserved" 3 "Float" 2 "Retract" 1 "Extend" 0 "Block" ;
VAL_ 2365471998 Valve12FailSaveModeCmd 3 "DoNotCare" 1 "Float" 0 "Block" ;
VAL_ 2365471998 Valve12StateCmd 15 "Reserved" 3 "Float" 2 "Retract" 1 "Extend" 0 "Block" ;
VAL_ 2365471742 Valve11FailSaveModeCmd 3 "DoNotCare" 1 "Float" 0 "Block" ;
VAL_ 2365471742 Valve11StateCmd 15 "Reserved" 3 "Float" 2 "Retract" 1 "Extend" 0 "Block" ;
VAL_ 2365471486 Valve10FailSaveModeCmd 3 "DoNotCare" 1 "Float" 0 "Block" ;
VAL_ 2365471486 Valve10StateCmd 15 "Reserved" 3 "Float" 2 "Retract" 1 "Extend" 0 "Block" ;
VAL_ 2365471230 Valve9FailSaveModeCmd 3 "DoNotCare" 1 "Float" 0 "Block" ;
VAL_ 2365471230 Valve9StateCmd 15 "Reserved" 3 "Float" 2 "Retract" 1 "Extend" 0 "Block" ;
VAL_ 2365470974 Valve8FailSaveModeCmd 3 "DoNotCare" 1 "Float" 0 "Block" ;
VAL_ 2365470974 Valve8StateCmd 15 "Reserved" 3 "Float" 2 "Retract" 1 "Extend" 0 "Block" ;
VAL_ 2365470718 Valve7FailSaveModeCmd 3 "DoNotCare" 1 "Float" 0 "Block" ;
VAL_ 2365470718 Valve7StateCmd 15 "Reserved" 3 "Float" 2 "Retract" 1 "Extend" 0 "Block" ;
VAL_ 2365470462 Valve6FailSaveModeCmd 3 "DoNotCare" 1 "Float" 0 "Block" ;
VAL_ 2365470462 Valve6StateCmd 15 "Reserved" 3 "Float" 2 "Retract" 1 "Extend" 0 "Block" ;
VAL_ 2365470206 Valve5FailSaveModeCmd 3 "DoNotCare" 1 "Float" 0 "Block" ;
VAL_ 2365470206 Valve5StateCmd 15 "Reserved" 3 "Float" 2 "Retract" 1 "Extend" 0 "Block" ;
VAL_ 2365469950 Valve4FailSaveModeCmd 3 "DoNotCare" 1 "Float" 0 "Block" ;
VAL_ 2365469950 Valve4StateCmd 15 "Reserved" 3 "Float" 2 "Retract" 1 "Extend" 0 "Block" ;
VAL_ 2365469694 Valve3FailSaveModeCmd 3 "DoNotCare" 1 "Float" 0 "Block" ;
VAL_ 2365469694 Valve3StateCmd 15 "Reserved" 3 "Float" 2 "Retract" 1 "Extend" 0 "Block" ;
VAL_ 2365469438 Valve2FailSaveModeCmd 3 "DoNotCare" 1 "Float" 0 "Block" ;
VAL_ 2365469438 Valve2StateCmd 15 "Reserved" 3 "Float" 2 "Retract" 1 "Extend" 0 "Block" ;
VAL_ 2365469182 Valve1FailSaveModeCmd 3 "DoNotCare" 1 "Float" 0 "Block" ;
VAL_ 2365469182 Valve1StateCmd 15 "Reserved" 3 "Float" 2 "Retract" 1 "Extend" 0 "Block" ;
VAL_ 2365468926 Valve0FailSaveModeCmd 3 "DoNotCare" 1 "Float" 0 "Block" ;
VAL_ 2365468926 Valve0StateCmd 15 "Reserved" 3 "Float" 2 "Retract" 1 "Extend" 0 "Block" ;
VAL_ 2365468670 Valve15LimitStatus 0 "Not limited" 1 "Operator Limited" 2 "Limited High" 3 "Limited Low" 4 "Reserved" 5 "Reserver" 6 "Non-recoverable Fault" 7 "Not available" ;
VAL_ 2365468414 Valve14LimitStatus 0 "Not limited" 1 "Operator Limited" 2 "Limited High" 3 "Limited Low" 4 "Reserved" 5 "Reserver" 6 "Non-recoverable Fault" 7 "Not available" ;
VAL_ 2365468158 Valve13LimitStatus 0 "Not limited" 1 "Operator Limited" 2 "Limited High" 3 "Limited Low" 4 "Reserved" 5 "Reserver" 6 "Non-recoverable Fault" 7 "Not available" ;
VAL_ 2365467902 Valve12LimitStatus 0 "Not limited" 1 "Operator Limited" 2 "Limited High" 3 "Limited Low" 4 "Reserved" 5 "Reserver" 6 "Non-recoverable Fault" 7 "Not available" ;
VAL_ 2365467646 Valve11LimitStatus 0 "Not limited" 1 "Operator Limited" 2 "Limited High" 3 "Limited Low" 4 "Reserved" 5 "Reserver" 6 "Non-recoverable Fault" 7 "Not available" ;
VAL_ 2365467390 Valve10LimitStatus 0 "Not limited" 1 "Operator Limited" 2 "Limited High" 3 "Limited Low" 4 "Reserved" 5 "Reserver" 6 "Non-recoverable Fault" 7 "Not available" ;
VAL_ 2365467134 Valve9LimitStatus 0 "Not limited" 1 "Operator Limited" 2 "Limited High" 3 "Limited Low" 4 "Reserved" 5 "Reserver" 6 "Non-recoverable Fault" 7 "Not available" ;
VAL_ 2365466878 Valve8LimitStatus 0 "Not limited" 1 "Operator Limited" 2 "Limited High" 3 "Limited Low" 4 "Reserved" 5 "Reserver" 6 "Non-recoverable Fault" 7 "Not available" ;
VAL_ 2365466622 Valve7LimitStatus 0 "Not limited" 1 "Operator Limited" 2 "Limited High" 3 "Limited Low" 4 "Reserved" 5 "Reserver" 6 "Non-recoverable Fault" 7 "Not available" ;
VAL_ 2365466366 Valve6LimitStatus 0 "Not limited" 1 "Operator Limited" 2 "Limited High" 3 "Limited Low" 4 "Reserved" 5 "Reserver" 6 "Non-recoverable Fault" 7 "Not available" ;
VAL_ 2365466110 Valve5LimitStatus 0 "Not limited" 1 "Operator Limited" 2 "Limited High" 3 "Limited Low" 4 "Reserved" 5 "Reserver" 6 "Non-recoverable Fault" 7 "Not available" ;
VAL_ 2365465854 Valve4LimitStatus 0 "Not limited" 1 "Operator Limited" 2 "Limited High" 3 "Limited Low" 4 "Reserved" 5 "Reserver" 6 "Non-recoverable Fault" 7 "Not available" ;
VAL_ 2365465598 Valve3LimitStatus 0 "Not limited" 1 "Operator Limited" 2 "Limited High" 3 "Limited Low" 4 "Reserved" 5 "Reserver" 6 "Non-recoverable Fault" 7 "Not available" ;
VAL_ 2365465342 Valve2LimitStatus 0 "Not limited" 1 "Operator Limited" 2 "Limited High" 3 "Limited Low" 4 "Reserved" 5 "Reserver" 6 "Non-recoverable Fault" 7 "Not available" ;
VAL_ 2365465086 Valve1LimitStatus 0 "Not limited" 1 "Operator Limited" 2 "Limited High" 3 "Limited Low" 4 "Reserved" 5 "Reserver" 6 "Non-recoverable Fault" 7 "Not available" ;
VAL_ 2365464830 Valve0LimitStatus 0 "Not limited" 1 "Operator Limited" 2 "Limited High" 3 "Limited Low" 4 "Reserved" 5 "Reserver" 6 "Non-recoverable Fault" 7 "Not available" ;
VAL_ 2365464574 AuxValve15ExitReasonCode 0 "No reason/all clear " 1 "Operator presence not detected " 2 "Implement released control of function" 3 "Operator override of function" 4 "Operator control not in valid position" 5 "Remote command timeout " 6 "Remote command out of range/invalid " 7 "Function not calibrated" 8 "Operator control fault " 9 "Function fault " 20 "Hydraulic oil level too low " 21 "Valve locked out " 62 "Error " 63 "Not available (parameter not supported)" ;
VAL_ 2365464574 Valve15LimitStatus 0 "Not limited" 1 "Operator Limited" 2 "Limited High" 3 "Limited Low" 4 "Reserved" 5 "Reserver" 6 "Non-recoverable Fault" 7 "Not available" ;
VAL_ 2365464574 Valve15FailSafeMode 3 "NotAvailable" 2 "ErrorIndication" 1 "Float" 0 "Block" ;
VAL_ 2365464574 Valve15ValveState 15 "DoNotCare" 14 "ErrorIndication" 3 "Floating" 2 "Retract" 1 "Extend" 0 "Blocked" ;
VAL_ 2365464318 Valve14LimitStatus 0 "Not limited" 1 "Operator Limited" 2 "Limited High" 3 "Limited Low" 4 "Reserved" 5 "Reserver" 6 "Non-recoverable Fault" 7 "Not available" ;
VAL_ 2365464318 Valve14FailSafeMode 3 "NotAvailable" 2 "ErrorIndication" 1 "Float" 0 "Block" ;
VAL_ 2365464318 Valve14ValveState 15 "DoNotCare" 14 "ErrorIndication" 3 "Floating" 2 "Retract" 1 "Extend" 0 "Blocked" ;
VAL_ 2365464062 Valve13LimitStatus 0 "Not limited" 1 "Operator Limited" 2 "Limited High" 3 "Limited Low" 4 "Reserved" 5 "Reserver" 6 "Non-recoverable Fault" 7 "Not available" ;
VAL_ 2365464062 Valve13FailSafeMode 3 "NotAvailable" 2 "ErrorIndication" 1 "Float" 0 "Block" ;
VAL_ 2365464062 Valve13ValveState 15 "DoNotCare" 14 "ErrorIndication" 3 "Floating" 2 "Retract" 1 "Extend" 0 "Blocked" ;
VAL_ 2365463806 Valve12LimitStatus 0 "Not limited" 1 "Operator Limited" 2 "Limited High" 3 "Limited Low" 4 "Reserved" 5 "Reserver" 6 "Non-recoverable Fault" 7 "Not available" ;
VAL_ 2365463806 Valve12FailSafeMode 3 "NotAvailable" 2 "ErrorIndication" 1 "Float" 0 "Block" ;
VAL_ 2365463806 Valve12ValveState 15 "DoNotCare" 14 "ErrorIndication" 3 "Floating" 2 "Retract" 1 "Extend" 0 "Blocked" ;
VAL_ 2365463550 Valve11LimitStatus 0 "Not limited" 1 "Operator Limited" 2 "Limited High" 3 "Limited Low" 4 "Reserved" 5 "Reserver" 6 "Non-recoverable Fault" 7 "Not available" ;
VAL_ 2365463550 Valve11FailSafeMode 3 "NotAvailable" 2 "ErrorIndication" 1 "Float" 0 "Block" ;
VAL_ 2365463550 Valve11ValveState 15 "DoNotCare" 14 "ErrorIndication" 3 "Floating" 2 "Retract" 1 "Extend" 0 "Blocked" ;
VAL_ 2365463294 Valve10LimitStatus 0 "Not limited" 1 "Operator Limited" 2 "Limited High" 3 "Limited Low" 4 "Reserved" 5 "Reserver" 6 "Non-recoverable Fault" 7 "Not available" ;
VAL_ 2365463294 Valve10FailSafeMode 3 "NotAvailable" 2 "ErrorIndication" 1 "Float" 0 "Block" ;
VAL_ 2365463294 Valve10ValveState 15 "DoNotCare" 14 "ErrorIndication" 3 "Floating" 2 "Retract" 1 "Extend" 0 "Blocked" ;
VAL_ 2365463038 Valve9LimitStatus 0 "Not limited" 1 "Operator Limited" 2 "Limited High" 3 "Limited Low" 4 "Reserved" 5 "Reserver" 6 "Non-recoverable Fault" 7 "Not available" ;
VAL_ 2365463038 Valve9FailSafeMode 3 "NotAvailable" 2 "ErrorIndication" 1 "Float" 0 "Block" ;
VAL_ 2365463038 Valve9ValveState 15 "DoNotCare" 14 "ErrorIndication" 3 "Floating" 2 "Retract" 1 "Extend" 0 "Blocked" ;
VAL_ 2365462782 Valve8LimitStatus 0 "Not limited" 1 "Operator Limited" 2 "Limited High" 3 "Limited Low" 4 "Reserved" 5 "Reserver" 6 "Non-recoverable Fault" 7 "Not available" ;
VAL_ 2365462782 Valve8FailSafeMode 3 "NotAvailable" 2 "ErrorIndication" 1 "Float" 0 "Block" ;
VAL_ 2365462782 Valve8ValveState 15 "DoNotCare" 14 "ErrorIndication" 3 "Floating" 2 "Retract" 1 "Extend" 0 "Blocked" ;
VAL_ 2365462526 Valve7LimitStatus 0 "Not limited" 1 "Operator Limited" 2 "Limited High" 3 "Limited Low" 4 "Reserved" 5 "Reserver" 6 "Non-recoverable Fault" 7 "Not available" ;
VAL_ 2365462526 Valve7FailSafeMode 3 "NotAvailable" 2 "ErrorIndication" 1 "Float" 0 "Block" ;
VAL_ 2365462526 Valve7ValveState 15 "DoNotCare" 14 "ErrorIndication" 3 "Floating" 2 "Retract" 1 "Extend" 0 "Blocked" ;
VAL_ 2365462270 Valve6LimitStatus 0 "Not limited" 1 "Operator Limited" 2 "Limited High" 3 "Limited Low" 4 "Reserved" 5 "Reserver" 6 "Non-recoverable Fault" 7 "Not available" ;
VAL_ 2365462270 Valve6FailSafeMode 3 "NotAvailable" 2 "ErrorIndication" 1 "Float" 0 "Block" ;
VAL_ 2365462270 Valve6ValveState 15 "DoNotCare" 14 "ErrorIndication" 3 "Floating" 2 "Retract" 1 "Extend" 0 "Blocked" ;
VAL_ 2365462014 Valve5LimitStatus 0 "Not limited" 1 "Operator Limited" 2 "Limited High" 3 "Limited Low" 4 "Reserved" 5 "Reserver" 6 "Non-recoverable Fault" 7 "Not available" ;
VAL_ 2365462014 Valve5FailSafeMode 3 "NotAvailable" 2 "ErrorIndication" 1 "Float" 0 "Block" ;
VAL_ 2365462014 Valve5ValveState 15 "DoNotCare" 14 "ErrorIndication" 3 "Floating" 2 "Retract" 1 "Extend" 0 "Blocked" ;
VAL_ 2365461758 Valve4LimitStatus 0 "Not limited" 1 "Operator Limited" 2 "Limited High" 3 "Limited Low" 4 "Reserved" 5 "Reserver" 6 "Non-recoverable Fault" 7 "Not available" ;
VAL_ 2365461758 Valve4FailSafeMode 3 "NotAvailable" 2 "ErrorIndication" 1 "Float" 0 "Block" ;
VAL_ 2365461758 Valve4ValveState 15 "DoNotCare" 14 "ErrorIndication" 3 "Floating" 2 "Retract" 1 "Extend" 0 "Blocked" ;
VAL_ 2365461502 Valve3LimitStatus 0 "Not limited" 1 "Operator Limited" 2 "Limited High" 3 "Limited Low" 4 "Reserved" 5 "Reserver" 6 "Non-recoverable Fault" 7 "Not available" ;
VAL_ 2365461502 Valve3FailSafeMode 3 "NotAvailable" 2 "ErrorIndication" 1 "Float" 0 "Block" ;
VAL_ 2365461502 Valve3ValveState 15 "DoNotCare" 14 "ErrorIndication" 3 "Floating" 2 "Retract" 1 "Extend" 0 "Blocked" ;
VAL_ 2365461246 Valve2LimitStatus 0 "Not limited" 1 "Operator Limited" 2 "Limited High" 3 "Limited Low" 4 "Reserved" 5 "Reserver" 6 "Non-recoverable Fault" 7 "Not available" ;
VAL_ 2365461246 Valve2FailSafeMode 3 "NotAvailable" 2 "ErrorIndication" 1 "Float" 0 "Block" ;
VAL_ 2365461246 Valve2ValveState 15 "DoNotCare" 14 "ErrorIndication" 3 "Floating" 2 "Retract" 1 "Extend" 0 "Blocked" ;
VAL_ 2365460990 Valve1LimitStatus 0 "Not limited" 1 "Operator Limited" 2 "Limited High" 3 "Limited Low" 4 "Reserved" 5 "Reserver" 6 "Non-recoverable Fault" 7 "Not available" ;
VAL_ 2365460990 Valve1FailSafeMode 3 "NotAvailable" 2 "ErrorIndication" 1 "Float" 0 "Block" ;
VAL_ 2365460990 Valve1ValveState 15 "DoNotCare" 14 "ErrorIndication" 3 "Floating" 2 "Retract" 1 "Extend" 0 "Blocked" ;
VAL_ 2365460734 AuxValveNum0ExitReasonCode 0 "No reason/all clear " 1 "Operator presence not detected " 2 "Implement released control of function " 3 "Operator override of function " 4 "Operator control not in valid position " 5 "Remote command timeout " 6 "Remote command out of range/invalid " 7 "Function not calibrated " 8 "Operator control fault " 9 "Function fault " 20 "Hydraulic oil level too low " 21 "Valve locked out" 62 "Error " 63 "Not available (parameter not supported)" ;
VAL_ 2365460734 Valve0LimitStatus 0 "Not limited" 1 "Operator Limited" 2 "Limited High" 3 "Limited Low" 4 "Reserved" 5 "Reserver" 6 "Non-recoverable Fault" 7 "Not available" ;
VAL_ 2365460734 Valve0FailSafeMode 3 "NotAvailable" 2 "ErrorIndication" 1 "Float" 0 "Block" ;
VAL_ 2365460734 Valve0ValveState 15 "DoNotCare" 14 "ErrorIndication" 3 "Floating" 2 "Retract" 1 "Extend" 0 "Blocked" ;
VAL_ 2566787070 TemperatureUnits 3 "NoAction" 2 "Reserved" 1 "Imperial" 0 "Metric" ;
VAL_ 2566787070 PressureUnits 3 "NoAction" 2 "Reserved" 1 "Imperial" 0 "Metric" ;
VAL_ 2566787070 ForceUnits 3 "NoAction" 2 "Reserved" 1 "Imperial" 0 "Metric" ;
VAL_ 2566787070 UnitsSystem 3 "NoAction" 2 "US" 1 "Imperial" 0 "Metric" ;
VAL_ 2566787070 DistanceUnitCmd 3 "NoAction" 1 "Imperial" 0 "Metric" ;
VAL_ 2566787070 AreaUnitCmd 3 "NoAction" 1 "Imperial" 0 "Metric" ;
VAL_ 2566787070 VolumeUnitCmd 3 "NoAction" 2 "US" 1 "Imperial" 0 "Metric" ;
VAL_ 2566787070 MassUnitCmd 3 "NoAction" 2 "TonsPounds" 1 "Imperial" 0 "Metric" ;
VAL_ 2566787070 DateFormatCmd 5 "yyyyddmm" 4 "yyyymmdd" 3 "mmddyyyy" 2 "mmyyyydd" 1 "ddyyyymm" 0 "ddmmyyyy" ;
VAL_ 2566787070 DecimalSymbolCmd 3 "NoAction" 1 "PointIsUsed" 0 "CommaIsUsed" ;
VAL_ 2566787070 TimeFormatCmd 3 "NoAction" 1 "Hour12" 0 "Hour24" ;
VAL_ 2633895166 Function 43 "Transmission Display" 44 "Exhaust Emission Control" 45 "Vehicle Dynamic Stability Control" 46 "Oil Sensor Unit" 47 "Information System Controller" 48 "Ramp Control" 49 "Clutch/Converter Control" 50 "Auxiliary Heater" 51 "Forward-Looking Collision Warning System" 52 "Chassis Controller" 53 "Alternator/Charging System" 54 "Communications Unit, Cellular" 55 "Communications Unit, Satellite" 56 "Communications Unit, Radio" 57 "Steering Column Unit" 58 "Fan Drive Control" 59 "Starter" 60 "Cab Display" 61 "File Server/Printer" 62 "On-Board Diagnostic Unit" 63 "Engine Valve Controller" 64 "Endurance Braking" 65 "Gas Flow Measurement" 66 "I/O Controller" 67 "Electrical System Controller" 68 "Aftertreatment system gas measurement" 69 "Engine Emission Aftertreatement System" 70 "Auxiliary Regeneration Device" 71 "Transfer Case Control" 72 "Coolant Valve Controller" 73 "Rollover Detection Control" 74 "Lubrication System" 75 "Supplemental Fan" 76 "Temperature Sensor" 77 "Fuel Properties Sensor" 78 "Fire Suppression System" 79 "Reserved" 80 "Reserved" 81 "Reserved" 82 "Reserved" 83 "Reserved" 84 "Reserved" 85 "Reserved" 86 "Reserved" 87 "Reserved" 88 "Reserved" 89 "Reserved" 90 "Reserved" 91 "Reserved" 92 "Reserved" 93 "Reserved" 94 "Reserved" 95 "Reserved" 96 "Reserved" 97 "Reserved" 98 "Reserved" 99 "Reserved" 100 "Reserved" 0 "Engine" 1 "Auxiliary Power Unit (APU)" 2 "Electric Propulsion Control" 3 "Transmission" 4 "Battery Pack Monitor" 5 "Shift Control/Console" 6 "Power TakeOff - (Main or Rear)" 7 "Axle - Steering" 8 "Axle - Drive" 9 "Brakes - System Controller" 10 "Brakes - Steer Axle" 11 "Brakes - Drive Axle" 12 "Retarder - Engine" 13 "Retarder - Driveline" 14 "Cruise Control" 15 "Fuel System" 16 "Steering Controller" 17 "Suspension - Steer Axle" 18 "Suspension - Drive Axle" 19 "Instrument Cluster" 20 "Trip Recorder" 21 "Cab Climate Control" 22 "Aerodynamic Control" 23 "Vehicle Navigation" 24 "Vehicle Security" 25 "Network Interconnect ECU" 26 "Body Controller" 27 "Power TakeOff (Secondary or Front)" 28 "Off Vehicle Gateway" 29 "Virtual Terminal (in cab)" 30 "Management Computer" 31 "Propulsion Battery Charger" 32 "Headway Controller" 33 "System Monitor" 34 "Hydraulic Pump Controller" 35 "Suspension - System Controller" 36 "Pneumatic - System Controller" 37 "Cab Controller" 38 "Tire Pressure Control" 39 "Ignition Control Module" 40 "Seat Control" 41 "Lighting - Operator Controls" 42 "Water Pump Control" 101 "Reserved" 102 "Reserved" 103 "Reserved" 104 "Reserved" 105 "Reserved" 106 "Reserved" 107 "Reserved" 108 "Reserved" 109 "Reserved" 110 "Reserved" 111 "Reserved" 112 "Reserved" 113 "Reserved" 114 "Reserved" 115 "Reserved" 116 "Reserved" 117 "Reserved" 118 "Reserved" 119 "Reserved" 120 "Reserved" 121 "Reserved" 122 "Reserved" 123 "Reserved" 124 "Reserved" 125 "Reserved" 126 "Reserved" 127 "Reserved" ;
VAL_ 2633895166 IndustryGroup 7 "Reserved for SAE" 5 "IndustrialProcessCtrlStationary" 4 "Marine" 3 "Construction" 2 "Agricultural and Forestry" 1 "On-Highway" 0 "Global" 6 "Reserved for SAE" ;
VAL_ 2633895166 ManufacturerCode 234 "Mondial electronic GmbH" 235 "SailorMade Marine Telemetry - Tetra Technology Ltd." 236 "Norac Systems International Inc" 237 "Agtron Enterprises Inc" 238 "ZF Friedrichshafen AG" 239 "May & Scofield Ltd" 240 "Vanair Mfg" 241 "Schneider Automation SAS " 242 "Kokusandenki Co. Ltd" 243 "eRide, Inc." 244 "Techno-Matic" 245 "Capstan Ag Systems, Inc." 246 "Class 1, Inc" 247 "ePULSE" 248 "Cooper Standard Automotive Active Systems Group" 264 "Autolync" 265 "MTS Sensor Technologie GmbH" 266 "International Thermal Research Ltd" 267 "Red Lion Controls, Inc" 268 "Accurate Technologies" 269 "Saft America Inc.,  Space & Defense Division" 270 "Tennant" 271 "Cole Hersee" 312 "Lectronix, Inc." 313 "Ilmor Engineering, Inc" 314 "CSM GmbH" 315 "Icom Incorporated" 316 "ITT Flow Control" 317 "Navtronics Bvba" 318 "SAT Plan" 319 "Cadec Global" 320 "Miedema Landbouwwerktuigenfabriek B.V." 321 "Ultra Electronics, Electrics" 322 "MICHENKA s.r.o." 323 "Mobileye Vision Technologies Ltd." 324 "Snap-on Diagnostics" 325 "ASM Automation Sensorik Messtechnik GmbH" 326 "Akron Brass Company" 327 "Sonceboz SA" 272 "Gross Mechanical Laboratories, Inc" 273 "Active Research Limited" 274 "LTW Technology Co., LTD" 275 "Navico Egersund AS" 276 "Aqua-Hot Heating Systems" 277 "LHP Telematics" 278 "Takata Electronics" 279 "Geometris LP" 280 "Leica Geosystems Pty Ltd" 299 "Rauch Landmaschinen GmbH" 300 "Systron Donner Automotive" 301 "Parker Hannifin (UK) Ltd FDE group" 302 "Nissin Kogyo Co., LTD" 303 "CTS Corporation" 304 "EmpirBus AB" 305 "NovAtel Inc" 306 "Sleipner Motor AB" 307 "MBW Technologies" 308 "Cyntrx" 309 "Krauss-Maffei Wegmann GmbH & Co. KG" 310 "TECNORD srl" 311 "Patrick Power Products" 281 "Precision Governors LLC" 282 "Medallion Instrumentation Systems" 283 "CWF Hamilton & Co Ltd" 284 "Mobile Tech Chile" 285 "Sea Recovery Corp" 286 "Coelmo srl" 287 "NTech Industries, Inc" 288 "Mitsubishi FUSO Truck & Bus Corp." 289 "Watlow" 290 "Kuebler GmbH" 291 "Groeneveld Transport Efficiency BV" 292 "IKUSI - Angel Iglesias S.A." 293 "Spyder Controls Corp." 294 "Grayhill Inc." 295 "BEP Marine" 296 "micro dynamics GmbH" 297 "Zonar Systems Inc" 298 "Holley Performance" 253 "Mobile Control Systems" 254 "GE Sensing" 255 "MEAS France" 256 "Tyco Electronics AMP" 257 "Honda Motor Co., Ltd" 258 "ARAG" 259 "Jetter AG" 260 "Reichhardt GmbH" 261 "Red Dot Corporation" 262 "HydraForce, Inc" 263 "IMMI" 223 "Vaueo Retarder Co., Ltd." 224 "EMMI Network, S.L." 225 "SKF" 226 "Monaco Coach Corporation" 227 "Lykketronic A/S" 228 "ZF Marine Electronics" 229 "Garmin International Inc." 230 "Saucon Technologies" 231 "Topcon Positioning Systems, Inc." 0 "Reserved" 1 "Allied Signal Inc." 2 "Allison Transmission, GMC" 3 "Ametek, US Gauge Division" 4 "Ametek-Dixson" 5 "AMP Inc." 6 "Berifors Electronics AB" 7 "Case Corp." 8 "Caterpillar Inc." 9 "Chrysler Corp." 10 "Cummins Engine Co." 11 "Dearborn Group Inc." 12 "Deere & Company, Precision Farming" 13 "Delco Electronics" 14 "Detroit Diesel Corporation" 15 "Dickey-John Corp." 16 "Eaton Corp." 17 "Eaton Corp. Res & Dev" 18 "Eaton Corp, Transmission Division" 19 "Eaton Corp. Trucking Info Services" 20 "Eaton Ltd" 21 "Echilin Inc., Midland Brake Inc." 22 "Ford Motor Co., Electronic Concepts $ Systems" 23 "Ford Motor Co., Heavy Truck" 24 "Ford Motor Co., Vehicle Controls" 25 "Daimler Trucks North America LLC" 26 "General Motors Corp., Service Technology Group" 27 "GMC" 28 "Grote Ind. Inc." 29 "Hino Motors Ltd." 30 "Isuzu Motors Ltd." 31 "J Pollak Corp." 32 "Jacobs Vehicle Systems" 33 "John Deere" 34 "Kelsey Hayes Co." 35 "Kenworth Truck Co." 36 "Lucas Ltd." 37 "Mack Trucks Inc." 38 "Micro Processor Systems Inc." 39 "Microfirm Inc." 40 "Motorola AIEG Inc." 41 "Motorola Inc." 42 "International Truck and Engine Corp. Engine Electronics" 43 "International Truck and Engine Corp. Vehicle Electronics" 44 "Nippondenso Co. Ltd." 45 "PACCAR" 46 "Noregon Systems, Inc" 47 "Phillips Semiconductor" 48 "Pollak Alphabet" 49 "RE America Inc." 50 "Robert Bosch Corp" 51 "Robert Bosch GmbH" 52 "Meritor Automotive, Inc." 53 "Continental Automotive Systems US, Inc." 54 "Meritor Wabco" 55 "Ryder System Inc." 56 "SAIC" 57 "Sauer-Danfoss Co." 58 "SPX Corporation, OTC Division" 59 "VES Inc." 60 "Volvo Trucks North America Inc." 61 "Volvo Truck Corp." 62 "Wabco" 63 "ZF Industries Inc." 64 "unused" 65 "MAN Nutzfahrzeuge AG" 66 "John Deere Construction Equipment Division" 67 "Funk Manufacturing Company" 68 "Scania" 69 "Trimble Navigation" 70 "Flex-Coil Limited" 71 "Vansco Electronics Ltd." 72 "Sisu Corporation" 73 "LeTourneau, Inc." 74 "Eaton Axle-Brake Division" 75 "Deere & Co. Agricultural Division" 76 "unused" 77 "Deere Power Systems Group" 78 "Frank W. Murphy Manufacturing, Inc." 79 "Daimler Benz AG - Engine Division (PBM)" 80 "Twin Disc, Inc." 81 "Fire Research Corp" 82 "Bobcat/Ingersoll-Rand" 83 "Bendix VORAD Technologies" 84 "New Holland UK Limited" 85 "Kohler Co." 86 "C.E. Niehoff & Company" 87 "J.C. Bamford Excavators Ltd (JCB)" 88 "Satloc Precision GPS" 89 "Kverneland Group, Electronics Division" 90 "Knorr-Bremse SfN GmbH" 91 "BSG Bodensee Steuergeraete GmbH" 92 "Ag-Chem Equipment Co., Inc." 93 "Perkins Engines Company Ltd." 94 "CNH Global N.V." 95 "Pacific Insight Electronics Corp." 96 "Mech@tronic IT GmbH" 97 "Ag Leader Technology, Inc." 98 "Mueller-Elektronik GmbH & Co." 99 "International Transmissions Ltd (ITL)" 100 "VDO Technik AG" 101 "Sensoria" 102 "AGCO GmbH & Co." 103 "CLAAS Agrosystems GmbH & Co. KG" 104 "Claas Selbstfahrende Erntemaschinen GmbH" 105 "Kiepe Elektrik GmbH & Co. KG" 106 "BAE Systems Controls, Inc." 107 "Grimme Landmaschinen GmbH & Co. KG" 108 "WTK-Elecktronik GmbH" 109 "TeeJet Technologies Denmark" 110 "EPIQ Sensor-Nite" 111 "Maschinenfabrik Bernard Krone GmbH" 112 "MECALAC" 113 "Stress-Tek, Inc." 114 "EControls, Inc." 115 "NACCO Materials Handling Group, Inc." 116 "BEELINE Technologies" 117 "HUSCO International" 118 "Intron GmbH" 119 "IntegriNautics" 120 "RDS Technology Ltd." 121 "HED (Hydro Electronic Devices, Inc.)" 122 "FG Wilson (Engineering) Limited" 123 "Basler Electric" 124 "Hydac Electronic" 125 "Nevada Automotive Test Center" 126 "Driver Tech" 127 "Holland USA" 128 "Gerhard Duecker GmbH & Co. KG" 129 "OMNEX Control Systems, Inc." 130 "Nido - Universal Machines B.V." 131 "ITT Industries" 132 "Mulag-Fahrzeugwerk" 133 "Bucher Schoerling GmbH" 134 "Iris Technology Ltd." 135 "Airmar Technology Corporation" 136 "Komatsu Ltd." 137 "Maretron" 138 "Georg Fritzmeier GmbH & Co. KG" 139 "Caterpillar Trimble Control Technologies (CTCT), LLC" 140 "Lowrance Electronics, Inc." 141 "Thales Navigation Ltd." 142 "TRW Automotive (Commercial Steering Systems)" 143 "W. Gmeiner GmbH & Co." 144 "Mercury Marine" 145 "MurCal Controls" 146 "Maxima Technologies" 147 "Nautibus Electronic GmbH" 148 "Blue Water Data, Inc." 149 "Holset" 150 "Fleetguard" 151 "Raven Industries Inc. - Flow Controls Division" 152 "elobau GmbH & Co. KG" 153 "Woodward, Industrial Controls Division" 154 "Westerbeke Corporation" 155 "Vetronix Corporation" 156 "ITT Industries - Cannon" 157 "ISSPRO Inc." 158 "Firestone Industrial Products Company" 159 "NTech Industries Inc." 160 "Nido" 161 "Offshore Systems (UK) Limited" 162 "Axiomatic Technologies" 163 "BRP Inc." 164 "DaimlerChrysler Off-Highway" 165 "CPAC Systems AB" 166 "Phoenix International" 167 "JLG Industries Inc." 168 "Xantrex" 169 "Marlin Technologies Inc." 170 "Computronics Corporation Ltd." 171 "Wachendorff Elektronik GmbH & Co. KG" 172 "Yanmar Marine USA" 173 "Ryeso, Inc." 174 "AB Volvo Penta" 175 "Veris Technologies, Inc." 176 "Moritz Aerospace" 177 "Diagnostic System Associates" 178 "Siemens VDO Automotive AG" 179 "TeeJet Technologies Denmark" 180 "Smart Power Systems" 181 "Coretronics, Inc." 182 "Vehicle Systems Engineering B.V." 183 "KDS Controls, Inc." 184 "EIA Electronics" 185 "Beede Electrical Instrument Company" 186 "Altronic, Inc." 187 "Air-Weigh" 188 "EMP Corp." 189 "QUALCOMM" 190 "Hella KGaA Hueck & Co." 191 "XRS Corporation" 192 "Floscan" 193 "Nobletec" 194 "TriMark Corporation" 195 "General Engine Products" 196 "LEMKEN GmbH & Co. KG" 197 "Mechron Power Systems" 198 "Mystic Valley Communications" 199 "Actia Corp." 200 "MGM Brakes" 201 "Disenos y Tecnologia S.A." 202 "Curtis Instruments, Inc." 203 "MILtronik GmbH" 204 "The Morey Corporation" 205 "SmarTire Systems Inc" 206 "port GmbH" 207 "Otto Engineering" 208 "Drew Technologies, Inc." 209 "Bell Equip. Co. SA (PTY) LTD" 210 "Iteris, Inc." 211 "DNA Group" 212 "Sure Power Industries, Inc." 213 "CNH Belgium N.V." 214 "MC elettronica Srl" 215 "Aetna Engineering/Fireboy-Xintex" 216 "Paneltronics Inc." 217 "RM Michaelides Software & Elektronik GmbH" 218 "Gits Manufacturing Company" 219 "Cat OEM Solutions" 220 "Beede Electrical Instrument Company, Inc." 221 "SiE" 222 "Generac Power Systems, Inc." 1850 "Teleflex" 1851 "Raymarine" 1852 "Navionics" 1853 "Japan Radio Co." 1854 "Northstar Technologies" 1855 "Furuno USA" 1856 "Trimble" 1857 "Simrad" 1858 "Litton" 1859 "Kvasar AB" 1860 "MMP" 1861 "Vector North America" 1862 "Sanshin" 1863 "Thomas G. Faria Co." 232 "TSD Integrated Controls" 233 "Yacht Monitoring Solutions Inc." 249 "Schaltbau GmbH" 250 "Kuhn Group" 251 "German Agricultural Society" 252 "Sensor-Technik Wiedemann GmbH" 328 "Qwerty Electronik AB" 329 "Deif A/S" 330 "Kidde Aerospace and Defense" 331 "Horton, Inc." 332 "HWH Corporation" 333 "Hadley Products Corporation" 334 "Takata-Petri AG" 335 "Evo Electric Ltd" 336 "APE s.r.o." 337 "Carraro S.p.A." 338 "GRAF-SYTECO" 339 "Competence Center ISOBUS e.V." 340 "Continental AG" 341 "Boning GmbH & Co" 342 "THOMAS MAGNETE GmbH" 343 "Baumer Group" 344 "Parvus Corporation" 345 "Korean Maritime University" 346 "Control Solutions" 347 "Honeywell" 348 "Amazonen Werke H. Dreyer" 349 "Suonentiet" 350 "Noris Marine Systems GmbH & Co KG" 351 "Thrane & Thrane" 352 "SAME DEUTZ-FAHR" 353 "Hegemon Electronics, Inc." 354 "Junkkari OY" 355 "Mastervolt International B.V." 356 "Fischer Panda Generators, Inc" 357 "Hardi International A/S" 358 "Victron Energy BV" 359 "Ludwig Bergmann GmbH" 360 "HJS Emission Technology GmbH & Co KG" 361 "InMach" 362 "Alois Poettinger Maschinenfabrik GmbH" 363 "BEI Duncan" 364 "OEM Controls Inc." 365 "Digi-Star, LLC" 366 "Viewnyx Corp." 367 "Fliegl Agrartechnik" 368 "HANSENHOF_electronic" 369 "Power Torque Engineering Ltd" 370 "Rolls-Royce Marine AS" 371 "Heinzmann GmbH & Co. KG" 373 "Electronic Design Inc." 374 "Northern Lights, Inc." 381 "B&G" 372 "Delphi" 375 "Williams Controls Inc." 376 "Quake Global" 377 "ifm electronic gmbh" 378 "Glendinning Marine Products" 379 "Yamabiko Corporation" 380 "Suntech International Ltd." 382 "National Agricultural and Food Research Organization" 383 "MCL Industries" 384 "Camano Light" 385 "Johnson Outdoor Marine Electronics" 386 "JLG Automation BVBA" 387 "Orscheln Products, LLC" 388 "Innomatix, LLC" 389 "Benchmark Electronics, Minnesota Division" 390 "Partech Inc." 391 "Electronic Design for Industry, Inc" 392 "Tianyuan Technology Co Ltd." 393 "Harvest Tec, Inc" 394 "Capi 2 Nederland BV" 395 "GENTEC S.R.L." 396 "Beyond Measure" 397 "Sanyo-kiki Co Ltd." 398 "Hilite International" 399 "ISEKI & Co., Ltd." 400 "Livorsi Marine" 401 "Torqeedo GmbH" 402 "Simma Software, Inc." 403 "Trackwell ADS, Inc." 404 "Com Nav Marine Ltd" 405 "Wema System AS" 406 "Vecima Networks Inc." 407 "Comtech Mobile Datacom" 408 "Corvus Energy Ltd." 409 "Transfluid S.r.L." 410 "COBO S.p.A. Divisione 3B6" 411 "Hy-Drive Technologies Ltd." 412 "WebTech Wireless Inc." 413 "Datapross Nijbroek bv" 414 "Cattron Group International" 415 "Valid Manufacturing Ltd." 416 "Kubota Corporation" 417 "KZValve" 418 "Intellistick Inc" 419 "Fusion Electronics Ltd" 420 "Vermeer Corporation, ACS Group" 421 "Vertex Standard Co., Ltd" 422 "True Heading AB" 423 "BSM Wireless, Inc." 424 "Odyne LLC" 425 "Methode Electronics Inc, MDI" 426 "Egersund Marine Electronics AS" 427 "em-trak Marine Electronics Ltd" 428 "Mfg_428" 429 "Rota Engineering Ltd." 455 "ADZ NAGANO GmbH" 456 "General Kinetics" 457 "RUSELPROM-ElectricDrive Ltd" 458 "Control Solutions, Inc." 459 "Alltek Marine Electronics Corp" 460 "San Giorgio S.E.I.N." 461 "HAWE Hydraulik SE" 462 "IHI Shibaura Machinery Corporation" 463 "PROBOTIQ" 464 "Leach International Corporation" 465 "Ashcroft Inc" 466 "Veethree Electronics and Marine LLC" 467 "Lely Industries N.V." 468 "Tyco Fire Protection Products" 469 "RA Consulting GmbH" 470 "SI-TEX Marine Electronics" 471 "Sea Cross Marine AB" 472 "Tenneco Inc." 473 "Boss Industries, Inc." 474 "Persen Technologies Inc." 475 "GME" 476 "Hummingbird Marine Electronics" 477 "OilQuick AB" 478 "OceanSat BV" 479 "Vapor Bus International" 430 "Auteq Telematica S.A." 431 "Tohatsu Corporation" 432 "S&A Systems, Inc." 433 "Rowe Electronics" 434 "Stored Energy Systems" 435 "Zunhammer GmbH" 436 "Kinze Manufacturing" 437 "Digital Yacht Limited" 438 "Comar Systems Ltd" 439 "Hyundai Heavy Industries" 440 "Cummins Power Generation" 441 "PTG Reifendruckregelsysteme GmbH" 442 "Horsch Maschinen GmbH" 443 "SignalQuest, Inc." 444 "ITT Power Solutions" 445 "KAT MECHATRONIC, Electronic Product Division" 446 "CertTech, L.L.C." 447 "Great Plains Mfg." 448 "Stanadyne Corporation, Electronics Systems" 449 "Polaris Industries Inc" 450 "Dycor Technologies Ltd." 451 "Parker Hannifin Corp" 452 "WIKA Alexander Wiegand SE & Co. KG" 453 "Cooper Bussmann" 454 "NGK Spark Plug Co. Ltd" 480 "EnerDel, Inc." 481 "Chetco Digital Instruments" 482 "Tricon Electronics" 483 "Valeo" 484 "Headsight Inc." 485 "MATT automotive" 486 "Westport Innovations Inc." 487 "DSE Test Solutions A/S" 488 "The Charles Machine Works, Inc." 489 "Appareo Systems" 490 "QuikQ" 491 "Penny and Giles Ltd" 492 "Inergy Automotive Systems" 493 "Watcheye" 494 "Synerject" 495 "HOLMER Maschinenbau GmbH" 496 "W. Gessmann GmbH" 497 "SENTRON Sistemas Embarcados" 498 "Innovative Design Solutions, Inc." 499 "LCJ Capteurs" 500 "Oxbo International Corporation" 501 "Agrotronix S.A." 502 "Attwood Corporation" 503 "Naviop S.R.L." 504 "Vesper Marine" 505 "Yetter Farm Equipment" 506 "IHI STAR Machinery Corporation" 507 "Test Center ISOBUS" 508 "Transtech Innovations" 509 "MOTORTECH GmbH" 510 "Marinesoft Co. Ltd" 511 "Sulky" 512 "Inpower LLC" 513 "FarmscanAg" 514 "DISTek Integration, Inc." 515 "GINAF Trucks Nederland B.V." 516 "AVAT Automation GmbH" 517 "Noland Engineering" 518 "Transas USA Inc." 519 "Peeters Landbouwmachines b.v." 520 "Trapeze" ;
VAL_ 2633895166 VehicleSystem 127 "Not Available" 0 "Non-specific System" ;
VAL_ 2633895166 VehicleSystem1 0 "Non-specific System" 127 "Not Available" 1 "Tractor" 2 "Trailer" ;
VAL_ 2633895166 VehicleSystem2 0 "Non-specific System" 127 "Not Available" 1 "Tractor" 2 "Tillage" 3 "Secondary Tillage" 4 "Planters/Seeders" 5 "Fertilizers" 6 "Sprayers" 7 "Harvesters" 8 "Root Harvesters" 9 "Forage" 10 "Irrigation" 11 "Transport/Trailer" 12 "Farm Yard Operations" 13 "Powered Auxiliary Device" 14 "Special Crops" 15 "Earth Work" 16 "Skidder" 17 "Sensor Systems" 19 "Timber Harvesters" 20 "Forwarders" 21 "Timber loaders" 22 "Timber Processing Machines" 23 "Mulchers" 24 "Utility Vehicles" 25 "Slurry Applicators" ;
VAL_ 2633895166 VehicleSystem3 0 "Non-specific System" 127 "Not Available" 1 "Skid Steer Loader" 2 "Articulated Dump Truck" 3 "Backhoe" 4 "Crawler" 5 "Excavator" 6 "Forklift" 7 "Four Wheel Drive Loader" 8 "Grader" ;
VAL_ 2633895166 VehicleSystem4 0 "Non-specific System" 127 "Not Available" 10 "System Tools" 20 "Safety Systems" 25 "Inter/Intranetwork Device" 30 "Electrical Distribution" 40 "Steering and Control Surfaces" 50 "Propulsion" 60 "Navigation" 70 "Communications" 80 "Instrumentation/General Systems (deprecate)" 90 "Internal Environment" 100 "Deck, Cargo and Fishing Equipment" 35 "Electrical Generation" 75 "Sensor Communication Interface" 85 "External Environment" 120 "Display" 125 "Entertainment" ;
VAL_ 2633895166 VehicleSystem5 0 "Ind. Process Control Stationary" 127 "Not Available" ;
VAL_ 2365459454 TactorControlModeCmd2 31 "DoNotCare" 18 "UserDefinedControl" 17 "EnableGuidanceControl" 16 "EnableRearDraftForceControl" 15 "EnableFrontDraftForceControl" 14 "EnableRearPTOTorqueControl" 13 "EnableFrontPTOTorqueControl" 12 "EnableEngineEconomyCruiseControl" 11 "EnableMinimumEngineSpeedControl" 10 "EnableConstPTOSpeedCruiseControl" 9 "EnableConstantPTOSpeedControl" 8 "EnableMaximumDraftPowerControl" 7 "EnableAuxiliaryValveSlipControl" 6 "EnableReduceSpeedSlipControl" 5 "EnableRearPTOSlipControl" 4 "EnableFrontPTOSlipControl" 3 "EnableRearHitchSlipControl" 2 "EnableFrontHitchSlipControl" 1 "EnableCruiseControl" 0 "DisableRemoteControl" ;
VAL_ 2365459454 TractorControlModeCmd1 31 "DontCare" 17 "EnableGuidanceControl" 16 "EnableRearDraftForceControl" 15 "EnableFrontDraftForceControl" 14 "EnableRearPTOTorqueControl" 13 "EnableFrontPTOTorqueControl" 12 "EnableEngineEconomyCruiseControl" 11 "EnableMinimumEngineSpeedControl" 10 "EnableConstPTOSpeedCruiseControl" 9 "EnableConstantPTOSpeedControl" 8 "EnableMaximumDraftPowerControl" 7 "EnableAuxiliaryValveSlipControl" 6 "EnableReduceSpeedSlipControl" 5 "EnableRearPTOSlipControl" 4 "EnableFrontPTOSlipControl" 3 "EnableRearHitchSlipControl" 2 "EnableFrontHitchSlipControl" 1 "EnableCruiseControl" 0 "DisableRemoteControl" ;
VAL_ 2365459198 TractorControlModeResponse2 31 "NotAvailable" 23 "EnableGuidanceControl" 22 "EnableRearDraftForceControl" 21 "EnableFrontDraftForceControl" 20 "EnableRearPTOTorqueControl" 19 "EnableFrontPTOTorqueControl" 18 "EnEngineEcoSpdNavigSpdCruiseCtrl" 17 "EnEngineEcoSpdWheelSpdCrusieCtrl" 16 "EnEngineEcoSpdGndSpeedCruiseCtrl" 15 "EnableMinimumEngineSpeedControl" 14 "EnCoPTOSpeedNavigSpeedCruisCtrl" 13 "EnCoPTOSpeedWheelSpeedCruiseCtrl" 12 "EnCoPTOSpeedGndSpeedCruisCtrl" 11 "EnableConstantPTOSpeedControl" 10 "EnableMaximumDraftPowerControl" 9 "EnableReduceSpeedSlipControl" 8 "EnableAuxiliaryValveSlipControl" 7 "EnableRearPTOSlipControl" 6 "EnableFrontPTOSlipControl" 5 "EnableRearHitchSlipControl" 4 "EnableFrontHitchSlipCtrl" 3 "EnableNavigationSpeedCruiseCtrl" 2 "EnableWheelSpeedCruiseControl" 1 "EnableGroundSpeedCruiseControl" 0 "DisableRemoteControl" ;
VAL_ 2365459198 TractorControlLimitStatus2 0 "Not limited" 1 "Operator Limited" 2 "Limited High" 3 "Limited Low" 4 "Reserved" 5 "Reserver" 6 "Non-recoverable Fault" 7 "Not available" ;
VAL_ 2365459198 TractorControlModeResponse1 31 "NotAvailable" 23 "EnableGuidanceControl" 22 "EnableRearDraftForceControl" 21 "EnableFrontDraftForceControl" 20 "EnableRearPTOTorqueControl" 19 "EnableFrontPTOTorqueControl" 18 "EnEngineEcoSpdNavigSpdCruiseCtrl" 17 "EnEngineEcoSpdWheelSpdCrusieCtrl" 16 "EnEngineEcoSpdGndSpeedCruiseCtrl" 15 "EnableMinimumEngineSpeedControl" 14 "EnCoPTOSpeedNavigSpeedCruisCtrl" 13 "EnCoPTOSpeedWheelSpeedCruiseCtrl" 12 "EnCoPTOSpeedGndSpeedCruisCtrl" 11 "EnableConstantPTOSpeedControl" 10 "EnableMaximumDraftPowerControl" 9 "EnableReduceSpeedSlipControl" 8 "EnableAuxiliaryValveSlipControl" 7 "EnableRearPTOSlipControl" 6 "EnableFrontPTOSlipControl" 5 "EnableRearHitchSlipControl" 4 "EnableFrontHitchSlipCtrl" 3 "EnableNavigationSpeedCruiseCtrl" 2 "EnableWheelSpeedCruiseControl" 1 "EnableGroundSpeedCruiseControl" 0 "DisableRemoteControl" ;
VAL_ 2365459198 TractorControlLimitStatus1 0 "Not limited" 1 "Operator Limited" 2 "Limited High" 3 "Limited Low" 4 "Reserved" 5 "Reserver" 6 "Non-recoverable Fault" 7 "Not available" ;
